VERSION ""

NS_ :

BS_:

BU_: PPIM HCP VDCM APM2 SGW IDCM EVCU2 BPCM

BO_ 1852 HVBATTERY_RM_CELLS8: 64 BPCM
 SG_ HVBatCellVoltage_Cell192 : 36|13@0+ (0.001,0) [0|5] "V"  SGW
 SG_ HVBatCellVoltage_Cell191 : 20|13@0+ (0.001,0) [0|5] "V"  SGW
 SG_ HVBatCellVoltage_Cell190 : 4|13@0+ (0.001,0) [0|5] "V"  SGW
 SG_ HVBatCellVoltage_Cell216 : 420|13@0+ (0.001,0) [0|5] "V"  SGW
 SG_ HVBatCellVoltage_Cell215 : 404|13@0+ (0.001,0) [0|5] "V"  Vector__XXX
 SG_ HVBatCellVoltage_Cell214 : 388|13@0+ (0.001,0) [0|5] "V"  Vector__XXX
 SG_ HVBatCellVoltage_Cell213 : 372|13@0+ (0.001,0) [0|5] "V"  Vector__XXX
 SG_ HVBatCellVoltage_Cell212 : 356|13@0+ (0.001,0) [0|5] "V"  Vector__XXX
 SG_ HVBatCellVoltage_Cell211 : 340|13@0+ (0.001,0) [0|5] "V"  Vector__XXX
 SG_ HVBatCellVoltage_Cell210 : 324|13@0+ (0.001,0) [0|5] "V"  Vector__XXX
 SG_ HVBatCellVoltage_Cell209 : 308|13@0+ (0.001,0) [0|5] "V"  Vector__XXX
 SG_ HVBatCellVoltage_Cell208 : 292|13@0+ (0.001,0) [0|5] "V"  Vector__XXX
 SG_ HVBatCellVoltage_Cell207 : 276|13@0+ (0.001,0) [0|5] "V"  Vector__XXX
 SG_ HVBatCellVoltage_Cell206 : 260|13@0+ (0.001,0) [0|5] "V"  Vector__XXX
 SG_ HVBatCellVoltage_Cell205 : 244|13@0+ (0.001,0) [0|5] "V"  Vector__XXX
 SG_ HVBatCellVoltage_Cell204 : 228|13@0+ (0.001,0) [0|5] "V"  Vector__XXX
 SG_ HVBatCellVoltage_Cell203 : 212|13@0+ (0.001,0) [0|5] "V"  Vector__XXX
 SG_ HVBatCellVoltage_Cell202 : 196|13@0+ (0.001,0) [0|5] "V"  Vector__XXX
 SG_ HVBatCellVoltage_Cell201 : 180|13@0+ (0.001,0) [0|5] "V"  Vector__XXX
 SG_ HVBatCellVoltage_Cell200 : 164|13@0+ (0.001,0) [0|5] "V"  Vector__XXX
 SG_ HVBatCellVoltage_Cell198 : 132|13@0+ (0.001,0) [0|5] "V"  Vector__XXX
 SG_ HVBatCellVoltage_Cell197 : 116|13@0+ (0.001,0) [0|5] "V"  Vector__XXX
 SG_ HVBatCellVoltage_Cell196 : 100|13@0+ (0.001,0) [0|5] "V"  Vector__XXX
 SG_ HVBatCellVoltage_Cell195 : 84|13@0+ (0.001,0) [0|5] "V"  Vector__XXX
 SG_ HVBatCellVoltage_Cell194 : 68|13@0+ (0.001,0) [0|5] "V"  Vector__XXX
 SG_ HVBatCellVoltage_Cell193 : 52|13@0+ (0.001,0) [0|5] "V"  Vector__XXX

BO_ 1851 HVBATTERY_RM_CELLS7: 64 BPCM
 SG_ HVBatCellVoltage_Cell189 : 420|13@0+ (0.001,0) [0|5] "V"  SGW
 SG_ HVBatCellVoltage_Cell188 : 404|13@0+ (0.001,0) [0|5] "V"  SGW
 SG_ HVBatCellVoltage_Cell187 : 388|13@0+ (0.001,0) [0|5] "V"  SGW
 SG_ HVBatCellVoltage_Cell186 : 372|13@0+ (0.001,0) [0|5] "V"  SGW
 SG_ HVBatCellVoltage_Cell185 : 356|13@0+ (0.001,0) [0|5] "V"  SGW
 SG_ HVBatCellVoltage_Cell184 : 340|13@0+ (0.001,0) [0|5] "V"  SGW
 SG_ HVBatCellVoltage_Cell183 : 324|13@0+ (0.001,0) [0|5] "V"  SGW
 SG_ HVBatCellVoltage_Cell182 : 308|13@0+ (0.001,0) [0|5] "V"  SGW
 SG_ HVBatCellVoltage_Cell181 : 292|13@0+ (0.001,0) [0|5] "V"  SGW
 SG_ HVBatCellVoltage_Cell180 : 276|13@0+ (0.001,0) [0|5] "V"  SGW
 SG_ HVBatCellVoltage_Cell179 : 260|13@0+ (0.001,0) [0|5] "V"  SGW
 SG_ HVBatCellVoltage_Cell178 : 244|13@0+ (0.001,0) [0|5] "V"  SGW
 SG_ HVBatCellVoltage_Cell177 : 228|13@0+ (0.001,0) [0|5] "V"  SGW
 SG_ HVBatCellVoltage_Cell176 : 212|13@0+ (0.001,0) [0|5] "V"  SGW
 SG_ HVBatCellVoltage_Cell175 : 196|13@0+ (0.001,0) [0|5] "V"  SGW
 SG_ HVBatCellVoltage_Cell174 : 180|13@0+ (0.001,0) [0|5] "V"  SGW
 SG_ HVBatCellVoltage_Cell173 : 164|13@0+ (0.001,0) [0|5] "V"  SGW
 SG_ HVBatCellVoltage_Cell172 : 148|13@0+ (0.001,0) [0|5] "V"  SGW
 SG_ HVBatCellVoltage_Cell171 : 132|13@0+ (0.001,0) [0|5] "V"  SGW
 SG_ HVBatCellVoltage_Cell170 : 116|13@0+ (0.001,0) [0|5] "V"  SGW
 SG_ HVBatCellVoltage_Cell169 : 100|13@0+ (0.001,0) [0|5] "V"  SGW
 SG_ HVBatCellVoltage_Cell168 : 84|13@0+ (0.001,0) [0|5] "V"  SGW
 SG_ HVBatCellVoltage_Cell167 : 68|13@0+ (0.001,0) [0|5] "V"  SGW
 SG_ HVBatCellVoltage_Cell166 : 52|13@0+ (0.001,0) [0|5] "V"  SGW
 SG_ HVBatCellVoltage_Cell165 : 36|13@0+ (0.001,0) [0|5] "V"  SGW
 SG_ HVBatCellVoltage_Cell164 : 20|13@0+ (0.001,0) [0|5] "V"  SGW
 SG_ HVBatCellVoltage_Cell163 : 4|13@0+ (0.001,0) [0|5] "V"  SGW

BO_ 1850 HVBATTERY_RM_CELLS6: 64 BPCM
 SG_ HVBatCellVoltage_Cell162 : 420|13@0+ (0.001,0) [0|5] "V"  SGW
 SG_ HVBatCellVoltage_Cell161 : 404|13@0+ (0.001,0) [0|5] "V"  SGW
 SG_ HVBatCellVoltage_Cell160 : 388|13@0+ (0.001,0) [0|5] "V"  SGW
 SG_ HVBatCellVoltage_Cell159 : 372|13@0+ (0.001,0) [0|5] "V"  SGW
 SG_ HVBatCellVoltage_Cell158 : 356|13@0+ (0.001,0) [0|5] "V"  SGW
 SG_ HVBatCellVoltage_Cell157 : 340|13@0+ (0.001,0) [0|5] "V"  SGW
 SG_ HVBatCellVoltage_Cell156 : 324|13@0+ (0.001,0) [0|5] "V"  SGW
 SG_ HVBatCellVoltage_Cell155 : 308|13@0+ (0.001,0) [0|5] "V"  SGW
 SG_ HVBatCellVoltage_Cell154 : 292|13@0+ (0.001,0) [0|5] "V"  SGW
 SG_ HVBatCellVoltage_Cell153 : 276|13@0+ (0.001,0) [0|5] "V"  SGW
 SG_ HVBatCellVoltage_Cell152 : 260|13@0+ (0.001,0) [0|5] "V"  SGW
 SG_ HVBatCellVoltage_Cell151 : 244|13@0+ (0.001,0) [0|5] "V"  SGW
 SG_ HVBatCellVoltage_Cell150 : 228|13@0+ (0.001,0) [0|5] "V"  SGW
 SG_ HVBatCellVoltage_Cell149 : 212|13@0+ (0.001,0) [0|5] "V"  SGW
 SG_ HVBatCellVoltage_Cell148 : 196|13@0+ (0.001,0) [0|5] "V"  SGW
 SG_ HVBatCellVoltage_Cell147 : 180|13@0+ (0.001,0) [0|5] "V"  SGW
 SG_ HVBatCellVoltage_Cell146 : 164|13@0+ (0.001,0) [0|5] "V"  SGW
 SG_ HVBatCellVoltage_Cell145 : 148|13@0+ (0.001,0) [0|5] "V"  SGW
 SG_ HVBatCellVoltage_Cell144 : 132|13@0+ (0.001,0) [0|5] "V"  SGW
 SG_ HVBatCellVoltage_Cell143 : 116|13@0+ (0.001,0) [0|5] "V"  SGW
 SG_ HVBatCellVoltage_Cell142 : 100|13@0+ (0.001,0) [0|5] "V"  SGW
 SG_ HVBatCellVoltage_Cell141 : 84|13@0+ (0.001,0) [0|5] "V"  SGW
 SG_ HVBatCellVoltage_Cell140 : 68|13@0+ (0.001,0) [0|5] "V"  SGW
 SG_ HVBatCellVoltage_Cell139 : 52|13@0+ (0.001,0) [0|5] "V"  SGW
 SG_ HVBatCellVoltage_Cell138 : 36|13@0+ (0.001,0) [0|5] "V"  SGW
 SG_ HVBatCellVoltage_Cell137 : 20|13@0+ (0.001,0) [0|5] "V"  SGW
 SG_ HVBatCellVoltage_Cell136 : 4|13@0+ (0.001,0) [0|5] "V"  SGW

BO_ 1849 HVBATTERY_RM_CELLS5: 64 BPCM
 SG_ HVBatCellVoltage_Cell135 : 420|13@0+ (0.001,0) [0|5] "V"  SGW
 SG_ HVBatCellVoltage_Cell134 : 404|13@0+ (0.001,0) [0|5] "V"  SGW
 SG_ HVBatCellVoltage_Cell133 : 388|13@0+ (0.001,0) [0|5] "V"  SGW
 SG_ HVBatCellVoltage_Cell132 : 372|13@0+ (0.001,0) [0|5] "V"  SGW
 SG_ HVBatCellVoltage_Cell131 : 356|13@0+ (0.001,0) [0|5] "V"  SGW
 SG_ HVBatCellVoltage_Cell130 : 340|13@0+ (0.001,0) [0|5] "V"  SGW
 SG_ HVBatCellVoltage_Cell129 : 324|13@0+ (0.001,0) [0|5] "V"  SGW
 SG_ HVBatCellVoltage_Cell128 : 308|13@0+ (0.001,0) [0|5] "V"  SGW
 SG_ HVBatCellVoltage_Cell127 : 292|13@0+ (0.001,0) [0|5] "V"  SGW
 SG_ HVBatCellVoltage_Cell126 : 276|13@0+ (0.001,0) [0|5] "V"  SGW
 SG_ HVBatCellVoltage_Cell125 : 260|13@0+ (0.001,0) [0|5] "V"  SGW
 SG_ HVBatCellVoltage_Cell124 : 244|13@0+ (0.001,0) [0|5] "V"  SGW
 SG_ HVBatCellVoltage_Cell123 : 228|13@0+ (0.001,0) [0|5] "V"  SGW
 SG_ HVBatCellVoltage_Cell122 : 212|13@0+ (0.001,0) [0|5] "V"  SGW
 SG_ HVBatCellVoltage_Cell121 : 196|13@0+ (0.001,0) [0|5] "V"  SGW
 SG_ HVBatCellVoltage_Cell120 : 180|13@0+ (0.001,0) [0|5] "V"  SGW
 SG_ HVBatCellVoltage_Cell119 : 164|13@0+ (0.001,0) [0|5] "V"  SGW
 SG_ HVBatCellVoltage_Cell118 : 148|13@0+ (0.001,0) [0|5] "V"  SGW
 SG_ HVBatCellVoltage_Cell117 : 132|13@0+ (0.001,0) [0|5] "V"  SGW
 SG_ HVBatCellVoltage_Cell116 : 116|13@0+ (0.001,0) [0|5] "V"  SGW
 SG_ HVBatCellVoltage_Cell115 : 100|13@0+ (0.001,0) [0|5] "V"  SGW
 SG_ HVBatCellVoltage_Cell114 : 84|13@0+ (0.001,0) [0|5] "V"  SGW
 SG_ HVBatCellVoltage_Cell113 : 68|13@0+ (0.001,0) [0|5] "V"  SGW
 SG_ HVBatCellVoltage_Cell112 : 52|13@0+ (0.001,0) [0|5] "V"  SGW
 SG_ HVBatCellVoltage_Cell111 : 36|13@0+ (0.001,0) [0|5] "V"  SGW
 SG_ HVBatCellVoltage_Cell110 : 20|13@0+ (0.001,0) [0|5] "V"  SGW
 SG_ HVBatCellVoltage_Cell109 : 4|13@0+ (0.001,0) [0|5] "V"  SGW

BO_ 2564485412 DIAGNOSTIC_RESPONSE_VDCM: 8 VDCM
 SG_ N_PDU_18DAF124 : 7|64@0+ (1,0) [0|0] "" SGW

BO_ 2564433137 DIAGNOSTIC_REQUEST_VDCM: 8 SGW
 SG_ N_PDU_18DA24F1 : 7|64@0+ (1,0) [0|0] "" VDCM

BO_ 502 VDCM_OBCM: 48 EVCU2
 SG_ VDCM_OBCDischCurrentLim : 265|14@0+ (0.1,-815) [-815|823.3] "A"  IDCM
 SG_ VDCM_BattBulkSOC : 283|10@0+ (0.1,0) [0|100] "%"  IDCM
 SG_ HVCMS_ServiceScope : 87|16@0+ (1,0) [0|65534] "" IDCM
 SG_ HVCMS_ReadyToChargeState : 271|1@0+ (1,0) [0|1] "" IDCM
 SG_ HVCMS_Protocol_Entry3 : 39|16@0+ (1,0) [0|65534] "" IDCM
 SG_ HVCMS_Protocol_Entry2 : 23|16@0+ (1,0) [0|65534] "" IDCM
 SG_ HVCMS_Protocol_Entry1 : 7|16@0+ (1,0) [0|65534] "" IDCM
 SG_ HVCMS_EVTargetVoltage : 247|14@0+ (0.1,0) [0|1638.2] "V"  IDCM
 SG_ HVCMS_EVTargetCurrent : 249|10@0+ (1,-500) [-500|522] "" IDCM
 SG_ HVCMS_EVRESSConditioning : 171|1@0+ (1,0) [0|1] "" IDCM
 SG_ HVCMS_EVRESS_SOC : 159|12@0+ (0.02442,0) [0|99.97548] "%"  IDCM
 SG_ HVCMS_EVReady : 170|1@0+ (1,0) [0|1] "" IDCM
 SG_ HVCMS_EVMax_V_Limit : 215|14@0+ (0.1,0) [0|1638.2] "V"  IDCM
 SG_ HVCMS_EVMax_P_Limit : 191|24@0+ (0.1,0) [0|1677721.4] "W"  IDCM
 SG_ HVCMS_EVMax_I_Limit : 169|10@0+ (1,-500) [-500|522] "A"  IDCM
 SG_ HVCMS_EVEnergyCapacity : 217|17@0+ (1,0) [0|131070] "Wh"  IDCM
 SG_ HVCMS_ChargingComplete : 269|1@0+ (1,0) [0|1] "" IDCM
 SG_ HVCMS_BulkChargingComplete : 270|1@0+ (1,0) [0|1] "" IDCM
 SG_ VDCM_TypeCNegotiationSts : 378|3@0+ (1,0) [0|7] "" IDCM
 SG_ VDCM_GenChallenge : 362|16@0+ (1,0) [0|65535] "" IDCM
 SG_ VDCM_ContractAuthenticationID : 346|16@0+ (1,0) [0|65535] "" IDCM
 SG_ HVCMS_EVEnergyRequest : 331|17@0+ (1,0) [0|131071] "Wh"  IDCM
 SG_ OBCM_OutVoltageSyncTgt : 289|10@0+ (1,0) [0|1022] "V"  IDCM
 SG_ HVCMS_ServiceCategory : 103|4@0+ (1,0) [0|15] "" IDCM
 SG_ HVCMS_SelectedServiceId : 135|16@0+ (1,0) [0|65535] "" IDCM
 SG_ HVCMS_SelectedPaymentOptn : 119|2@0+ (1,0) [0|3] "" IDCM
 SG_ HVCMS_SelectedEnergyTransferType : 151|4@0+ (1,0) [0|15] "" IDCM
 SG_ HVCMS_RemaningTimeToFullSOC : 71|16@0+ (1,0) [0|65535] "sec"  IDCM
 SG_ HVCMS_RemaningTimeToBulkSOC : 55|16@0+ (1,0) [0|65534] "" IDCM
 SG_ HVCMS_EVErrorCode : 163|4@0+ (1,0) [0|15] "" IDCM
 SG_ V2X_HVCMS_SlctdEnergyTransfType : 99|1@0+ (1,0) [0|1] "-"  IDCM

BO_ 498 OBCM_VDCM: 48 IDCM
 SG_ HVCMS_EVSEPresentVoltage : 250|14@0+ (0.1,0) [0|1638.3] "V"  EVCU2
 SG_ HVCMS_EVSEPeakCurrentRipple : 199|10@0+ (1,-500) [-500|523] "A"  EVCU2
 SG_ HVCMS_EVSEMinCurrentLimit : 157|10@0+ (1,-500) [-500|523] "A"  EVCU2
 SG_ HVCMS_EVSEMaxPowerLimit : 205|24@0+ (0.1,0) [0|1677721.5] "W"  EVCU2
 SG_ HVCMS_EVSEMaxCurrentLimit : 151|10@0+ (1,-500) [-500|523] "A"  EVCU2
 SG_ HVCMS_EVSECurrRegulationTol : 244|10@0+ (1,-500) [-500|523] "A"  EVCU2
 SG_ HVCMS_EnergyToBeDelivered : 229|17@0+ (1,0) [0|131071] "Wh"  EVCU2
 SG_ EVSE_IsolationSts : 143|3@0+ (1,0) [0|7] "" EVCU2
 SG_ EVSE_Accepted_Protocol : 39|16@0+ (1,0) [0|65535] "" EVCU2
 SG_ DC_TimeOut : 139|1@0+ (1,0) [0|1] "" EVCU2
 SG_ DC_Isolation_Disable_Cmd : 140|1@0+ (1,0) [0|1] "" EVCU2
 SG_ OBCM_PLCTypeSts : 337|3@0+ (1,0) [0|6] "" EVCU2
 SG_ HVCMS_EVSEVoltageLimitAchieved : 286|2@0+ (1,0) [0|3] "" EVCU2
 SG_ HVCMS_EVSEPowerLimitAchieved : 272|2@0+ (1,0) [0|3] "" EVCU2
 SG_ HVCMS_EVSEMinimumVoltageLimit : 300|16@0+ (0.1,0) [0|6553.4] "V"  EVCU2
 SG_ HVCMS_EVSEMaximumVoltageLimit : 284|16@0+ (0.1,0) [0|6553.4] "V"  EVCU2
 SG_ HVCMS_EVSECurrentLimitAchieved : 274|2@0+ (1,0) [0|3] "" EVCU2
 SG_ HVCMS_EVSEPresentCurrent : 350|16@0+ (0.02,0) [0|1310.7] "A"  EVCU2
 SG_ EVSE_OfferedEnergyTransferType : 103|4@0+ (1,0) [0|15] "" EVCU2
 SG_ HVCMS_TxMessageStat : 7|5@0+ (1,0) [0|31] "" EVCU2
 SG_ HVCMS_ResponseCode : 23|5@0+ (1,0) [0|31] "" EVCU2
 SG_ HVCMS_EVSEProcessing : 119|1@0+ (1,0) [0|1] "" EVCU2
 SG_ EVSE_FreeService : 71|1@0+ (1,0) [0|1] "" EVCU2
 SG_ TxMessageResponse : 70|5@0+ (1,0) [0|31] "" EVCU2
 SG_ HVCMS_EVSEStatusCode : 135|4@0+ (1,0) [0|15] "" EVCU2
 SG_ EVSE_ServiceId : 55|16@0+ (1,0) [0|65535] "" EVCU2
 SG_ EVSE_OfferedService : 138|3@0+ (1,0) [0|7] "" EVCU2
 SG_ EVSE_OfferedPaymentOptn : 87|2@0+ (1,0) [0|3] "" EVCU2
 SG_ V2H_HVCMS_EVSEPresentCurrent : 268|10@0+ (1,-500) [-500|523] "A"  EVCU2
 SG_ MC_OBCM_VDCM : 371|4@0+ (1,0) [0|15] "" EVCU2
 SG_ EVSE_Supported_ISO1 : 64|1@0+ (1,0) [0|1] "" EVCU2
 SG_ EVSE_Supported_DIN : 65|1@0+ (1,0) [0|1] "-"  EVCU2
 SG_ CRC_OBCM_VDCM : 383|8@0+ (1,0) [0|255] "" EVCU2
 SG_ EVSE_Supported_SAE : 31|1@0+ (1,0) [0|1] "" EVCU2
 SG_ EVSE_Service2_Certificate : 16|1@0+ (1,0) [0|1] "-"  EVCU2
 SG_ EVSE_OfferedPaymentEIM : 18|1@0+ (1,0) [0|1] "-"  EVCU2
 SG_ EVSE_OfferedPaymentContract : 17|1@0+ (1,0) [0|1] "-"  EVCU2
 SG_ EVSE_Notification : 2|2@0+ (1,0) [0|3] "" EVCU2
 SG_ OBCM_ThermalRunaway : 131|2@0+ (1,0) [0|3] "" EVCU2
 SG_ ReceiptRequired : 0|1@0+ (1,0) [0|1] "-"  EVCU2
 SG_ V2X_EVSE_Service_6_V2G : 29|1@0+ (1,0) [0|1] "-"  EVCU2
 SG_ V2X_EVSE_Service_5_V2H : 30|1@0+ (1,0) [0|1] "-"  EVCU2

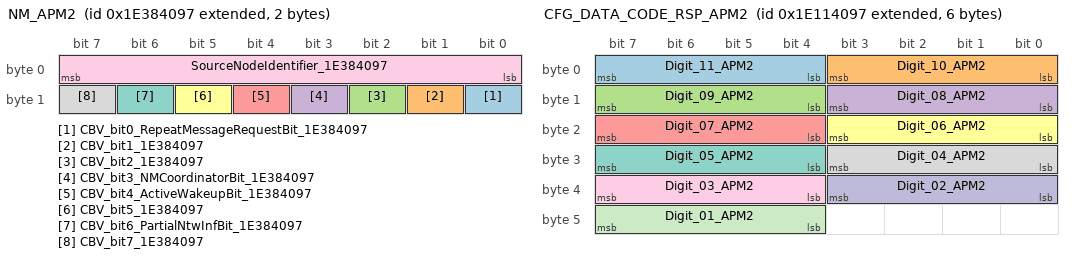
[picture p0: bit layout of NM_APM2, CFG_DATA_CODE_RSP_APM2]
BO_ 2654486679 NM_APM2: 2 APM2
 SG_ CBV_bit0_RepeatMessageRequestBit_1E384097 : 8|1@0+ (1,0) [0|1] "" EVCU2,IDCM,SGW,BPCM
 SG_ CBV_bit1_1E384097 : 9|1@0+ (1,0) [0|1] "" EVCU2,IDCM,SGW,BPCM
 SG_ CBV_bit2_1E384097 : 10|1@0+ (1,0) [0|1] "" EVCU2,IDCM,SGW,BPCM
 SG_ CBV_bit3_NMCoordinatorBit_1E384097 : 11|1@0+ (1,0) [0|1] "" EVCU2,IDCM,SGW,BPCM
 SG_ CBV_bit4_ActiveWakeupBit_1E384097 : 12|1@0+ (1,0) [0|1] "" EVCU2,IDCM,SGW,BPCM
 SG_ CBV_bit5_1E384097 : 13|1@0+ (1,0) [0|1] "" EVCU2,IDCM,SGW,BPCM
 SG_ CBV_bit6_PartialNtwInfBit_1E384097 : 14|1@0+ (1,0) [0|1] "" EVCU2,IDCM,SGW,BPCM
 SG_ CBV_bit7_1E384097 : 15|1@0+ (1,0) [0|1] "" EVCU2,IDCM,SGW,BPCM
 SG_ SourceNodeIdentifier_1E384097 : 7|8@0+ (1,0) [0|255] "-"  EVCU2,IDCM,SGW,BPCM

BO_ 2564682261 DIAGNOSTIC_ROE_FD_MCPB: 64 EVCU2
 SG_ N_PDU_18DDF215 : 7|64@0+ (1,0) [0|0] "" SGW

BO_ 2564682260 DIAGNOSTIC_ROE_FD_MCPA: 64 EVCU2
 SG_ N_PDU_18DDF214 : 7|64@0+ (1,0) [0|0] "" SGW

BO_ 2564682335 DIAGNOSTIC_ROE_FD_APM2: 64 APM2
 SG_ N_PDU_18DDF25F : 7|64@0+ (1,0) [0|0] "" SGW

BO_ 2564682079 DIAGNOSTIC_ROE_APM2: 8 APM2
 SG_ N_PDU_18DDF15F : 7|64@0+ (1,0) [0|0] "" SGW

BO_ 2564485396 DIAGNOSTIC_RESPONSE_MCPA: 8 EVCU2
 SG_ N_PDU_18DAF114 : 7|64@0+ (1,0) [0|0] "" SGW

BO_ 2564485653 DIAGNOSTIC_RESPONSE_FD_MCPB: 64 EVCU2
 SG_ N_PDU_18DAF215 : 7|64@0+ (1,0) [0|0] "" SGW

BO_ 2564485652 DIAGNOSTIC_RESPONSE_FD_MCPA: 64 EVCU2
 SG_ N_PDU_18DAF214 : 7|64@0+ (1,0) [0|0] "" SGW

BO_ 2564485727 DIAGNOSTIC_RESPONSE_FD_APM2: 64 APM2
 SG_ N_PDU_18DAF25F : 7|64@0+ (1,0) [0|0] "" SGW

BO_ 2564485471 DIAGNOSTIC_RESPONSE_APM2: 8 APM2
 SG_ N_PDU_18DAF15F : 7|64@0+ (1,0) [0|0] "" SGW

BO_ 2564429297 DIAGNOSTIC_REQUEST_MCPB: 8 SGW
 SG_ N_PDU_18DA15F1 : 7|64@0+ (1,0) [0|0] "" EVCU2

BO_ 2564429041 DIAGNOSTIC_REQUEST_MCPA: 8 SGW
 SG_ N_PDU_18DA14F1 : 7|64@0+ (1,0) [0|0] "" EVCU2

BO_ 2564429298 DIAGNOSTIC_REQUEST_FD_MCPB: 64 SGW
 SG_ N_PDU_18DA15F2 : 7|64@0+ (1,0) [0|0] "" EVCU2

BO_ 2564429042 DIAGNOSTIC_REQUEST_FD_MCPA: 64 SGW
 SG_ N_PDU_18DA14F2 : 7|64@0+ (1,0) [0|0] "" EVCU2

BO_ 2564448242 DIAGNOSTIC_REQUEST_FD_APM2: 64 SGW
 SG_ N_PDU_18DA5FF2 : 7|64@0+ (1,0) [0|0] "" APM2

BO_ 2564448241 DIAGNOSTIC_REQUEST_APM2: 8 SGW
 SG_ N_PDU_18DA5FF1 : 7|64@0+ (1,0) [0|0] "" APM2

BO_ 2651930775 CFG_DATA_CODE_RSP_APM2: 6 APM2
 SG_ Digit_11_APM2 : 7|4@0+ (1,0) [0|15] "-"  EVCU2
 SG_ Digit_10_APM2 : 3|4@0+ (1,0) [0|15] "-"  EVCU2
 SG_ Digit_09_APM2 : 15|4@0+ (1,0) [0|15] "-"  EVCU2
 SG_ Digit_08_APM2 : 11|4@0+ (1,0) [0|15] "-"  EVCU2
 SG_ Digit_07_APM2 : 23|4@0+ (1,0) [0|15] "-"  EVCU2
 SG_ Digit_06_APM2 : 19|4@0+ (1,0) [0|15] "-"  EVCU2
 SG_ Digit_05_APM2 : 31|4@0+ (1,0) [0|15] "-"  EVCU2
 SG_ Digit_04_APM2 : 27|4@0+ (1,0) [0|15] "-"  EVCU2
 SG_ Digit_03_APM2 : 39|4@0+ (1,0) [0|15] "-"  EVCU2
 SG_ Digit_02_APM2 : 35|4@0+ (1,0) [0|15] "-"  EVCU2
 SG_ Digit_01_APM2 : 47|4@0+ (1,0) [0|15] "-"  EVCU2

BO_ 244 BATTERY_HV: 64 BPCM
 SG_ BMS_HV_Trac_PreCha_Contac_Sts : 305|3@0+ (1,0) [0|7] "" SGW
 SG_ BMS_HV_Trac_Main_Contac_Sts : 318|3@0+ (1,0) [0|7] "" SGW
 SG_ BMS_HV_SOH_Low : 31|7@0+ (1,0) [0|127] "" SGW
 SG_ BMS_HV_SOH : 22|7@0+ (1,0) [0|127] "" SGW
 SG_ BMS_HV_SOC : 55|10@0+ (0.1,0) [0|102.2] "%"  SGW
 SG_ BMS_HV_InternalVoltage : 278|13@0+ (0.1,90.9) [90.9|910] "V"  SGW
 SG_ BMS_HV_Current : 213|15@0+ (0.1,-1638.4) [-1638.4|1638.2] "A"  SGW
 SG_ BMS_HV_Char_PreCha_Contac_Sts : 312|3@0+ (1,0) [0|7] "" SGW
 SG_ BMS_HV_Char_Main_Contac_Sts : 315|3@0+ (1,0) [0|7] "" SGW
 SG_ BMS_HV_Capacity_Vldty : 79|1@0+ (1,0) [0|1] "" SGW
 SG_ BMS_HV_Battery_GFD_Sts : 251|3@0+ (1,0) [0|7] "" SGW
 SG_ BPCM_Comm_Fail_CAN : 162|4@0+ (1,0) [0|14] "" SGW
 SG_ BMS_HV_Trac_Bus_Sts : 61|3@0+ (1,0) [0|6] "" SGW
 SG_ BMS_HV_Temperature_Min : 157|11@0+ (0.1,-40) [-40|164.7] "°C"  SGW
 SG_ BMS_HV_Temperature_Max : 136|11@0+ (0.1,-40) [-40|164.7] "°C"  SGW
 SG_ BMS_HV_Temperature_Avg : 131|11@0+ (0.1,-40) [-40|164.7] "°C"  SGW
 SG_ BMS_HV_SOH_Vldty : 230|1@0+ (1,0) [0|1] "" SGW
 SG_ BMS_HV_AC_Char_Main_Contac_Sts : 200|3@0+ (1,0) [0|7] "" SGW
 SG_ ImpactHardwireV : 500|1@0+ (1,0) [0|1] "" EVCU2
 SG_ ImpactHardwire : 501|1@0+ (1,0) [0|1] "" EVCU2
 SG_ BMS_HV_Capacity : 58|11@0+ (0.15,0) [0|307.05] "Ah"  SGW

BO_ 252 BATT_PACK_LIM: 48 BPCM
 SG_ BMS_HV_Current_MaxDischrg_MdTrm : 93|14@0+ (0.1,0) [0|1638.2] "A"  SGW
 SG_ BMS_HV_Current_MaxDischrg_LgTrm : 149|14@0+ (0.1,0) [0|1638.2] "A"  SGW
 SG_ BMS_HV_Current_Discharge_ShrTrm : 37|14@0+ (0.1,0) [0|1638.2] "A"  SGW
 SG_ BMS_CntctrsShtTrmOpeningWarn : 321|1@0+ (1,0) [0|1] "" SGW
 SG_ BMS_CntctrsMidTrmOpeningWarn : 322|1@0+ (1,0) [0|1] "" SGW

BO_ 500 BATT_PACK_DEV: 32 BPCM
 SG_ BMS_HV_NumCellMinVolt : 61|8@0+ (1,0) [0|255] "" SGW
 SG_ BMS_HV_NumCellMinTemp : 174|9@0+ (1,0) [0|510] "" SGW
 SG_ BMS_HV_NumCellMaxVolt : 53|8@0+ (1,0) [0|255] "" SGW
 SG_ BMS_HV_NumCellMaxTemp : 167|9@0+ (1,0) [0|510] "" SGW
 SG_ BMS_Cell_Volt_Min_Vldty : 96|1@0+ (1,0) [0|1] "" SGW
 SG_ BMS_Cell_Volt_Min : 93|13@0+ (0.001,0) [0|8.19] "V"  SGW
 SG_ BMS_Cell_Volt_Max_Vldty : 94|1@0+ (1,0) [0|1] "" SGW
 SG_ BMS_Cell_Volt_Max : 75|13@0+ (0.001,0) [0|8.19] "V"  SGW

BO_ 250 APM_VDCM: 32 IDCM
 SG_ APM_Water_Temp : 95|8@0+ (1,-40) [-40|214] "°C"  EVCU2
 SG_ APM_RecoveryAction : 101|8@0+ (1,0) [0|255] "" EVCU2
 SG_ APM_PSFB_Temp2 : 75|12@0+ (0.1,-40) [-40|369.4] "°C"  EVCU2
 SG_ APM_PSFB_Temp1 : 71|12@0+ (0.1,-40) [-40|369.4] "°C"  EVCU2
 SG_ APM_LV_V_Fbk : 47|12@0+ (0.009143,0) [0|37.431442] "V"  EVCU2
 SG_ APM_LV_I_Fbk : 23|12@0+ (0.076917,0) [0|314.898198] "A"  EVCU2
 SG_ APM_HV_V_Fbk : 51|12@0+ (0.445636,0) [0|1824.433784] "V"  EVCU2
 SG_ APM_HV_I_Fbk : 27|12@0+ (0.002718,0) [0|11.127492] "A"  EVCU2
 SG_ APM_Buck_Temp : 3|12@0+ (0.1,-40) [-40|369.4] "°C"  EVCU2
 SG_ APM_UtilPctOfDCDC : 154|7@0+ (1,0) [0|127] "%"  EVCU2
 SG_ APM_TempColdPlate : 146|8@0+ (1,-40) [-40|215] "degC"  EVCU2
 SG_ APM_PowerLimitMode : 112|1@0+ (1,0) [0|1] "" EVCU2
 SG_ APM_OutputPower : 179|10@0+ (3,0) [0|3069] "W"  EVCU2
 SG_ APM_InputPower : 173|10@0+ (3,0) [0|3069] "W"  EVCU2
 SG_ APM_IdcHvSetPFdbk : 140|10@0+ (0.2,-100) [-100|104.6] "Amp"  EVCU2
 SG_ APM_HvVsetPFdbk : 185|9@0+ (1,0) [0|511] "V"  EVCU2
 SG_ APM_HvOverVStatus : 114|1@0+ (1,0) [0|1] "" EVCU2
 SG_ APM_FailureType : 103|2@0+ (1,0) [0|3] "" EVCU2
 SG_ APM_FailureReason : 122|6@0+ (1,0) [0|63] "" EVCU2
 SG_ APM_EstPwrLoss : 132|8@0+ (2,0) [0|510] "W"  EVCU2
 SG_ APM_DeratingReason : 127|5@0+ (1,0) [0|31] "" EVCU2
 SG_ APM_DeratingModeStatus : 109|3@0+ (1,0) [0|7] "" EVCU2
 SG_ APM_CurrentLimitMode : 113|1@0+ (1,0) [0|1] "" EVCU2
 SG_ APM_CtrlSts_Fbk : 7|4@0+ (1,0) [0|15] "" EVCU2
 SG_ MessageCounter_APM_VDCM : 243|4@0+ (1,0) [0|15] "-"  EVCU2
 SG_ CRC_APM_VDCM : 255|8@0+ (1,0) [0|255] "-"  EVCU2
 SG_ APM_DeratingPower : 163|6@0+ (50,0) [0|3100] "W"  EVCU2
 SG_ APM_ThermalRunaway : 118|2@0+ (1,0) [0|3] "" EVCU2

BO_ 2564485397 DIAGNOSTIC_RESPONSE_MCPB: 8 EVCU2
 SG_ N_PDU_18DAF115 : 7|64@0+ (1,0) [0|0] "" SGW

CM_ SG_ 1852 HVBatCellVoltage_Cell192 "High voltage battery cell voltage for Cell 192";
CM_ SG_ 1852 HVBatCellVoltage_Cell191 "High voltage battery cell voltage for Cell 191";
CM_ SG_ 1852 HVBatCellVoltage_Cell190 "High voltage battery cell voltage for Cell 190";
CM_ SG_ 1851 HVBatCellVoltage_Cell189 "High voltage battery cell voltage for Cell 189";
CM_ SG_ 1851 HVBatCellVoltage_Cell188 "High voltage battery cell voltage for Cell 188";
CM_ SG_ 1851 HVBatCellVoltage_Cell187 "High voltage battery cell voltage for Cell 187";
CM_ SG_ 1851 HVBatCellVoltage_Cell186 "High voltage battery cell voltage for Cell 186";
CM_ SG_ 1851 HVBatCellVoltage_Cell185 "High voltage battery cell voltage for Cell 185";
CM_ SG_ 1851 HVBatCellVoltage_Cell184 "High voltage battery cell voltage for Cell 184";
CM_ SG_ 1851 HVBatCellVoltage_Cell183 "High voltage battery cell voltage for Cell 183";
CM_ SG_ 1851 HVBatCellVoltage_Cell182 "High voltage battery cell voltage for Cell 182";
CM_ SG_ 1851 HVBatCellVoltage_Cell181 "High voltage battery cell voltage for Cell 181";
CM_ SG_ 1851 HVBatCellVoltage_Cell180 "High voltage battery cell voltage for Cell 180";
CM_ SG_ 1851 HVBatCellVoltage_Cell179 "High voltage battery cell voltage for Cell 179";
CM_ SG_ 1851 HVBatCellVoltage_Cell178 "High voltage battery cell voltage for Cell 178";
CM_ SG_ 1851 HVBatCellVoltage_Cell177 "High voltage battery cell voltage for Cell 177";
CM_ SG_ 1851 HVBatCellVoltage_Cell176 "High voltage battery cell voltage for Cell 176";
CM_ SG_ 1851 HVBatCellVoltage_Cell175 "High voltage battery cell voltage for Cell 175";
CM_ SG_ 1851 HVBatCellVoltage_Cell174 "High voltage battery cell voltage for Cell 174";
CM_ SG_ 1851 HVBatCellVoltage_Cell173 "High voltage battery cell voltage for Cell 173";
CM_ SG_ 1851 HVBatCellVoltage_Cell172 "High voltage battery cell voltage for Cell 172";
CM_ SG_ 1851 HVBatCellVoltage_Cell171 "High voltage battery cell voltage for Cell 171";
CM_ SG_ 1851 HVBatCellVoltage_Cell170 "High voltage battery cell voltage for Cell 170";
CM_ SG_ 1851 HVBatCellVoltage_Cell169 "High voltage battery cell voltage for Cell 169";
CM_ SG_ 1851 HVBatCellVoltage_Cell168 "High voltage battery cell voltage for Cell 168";
CM_ SG_ 1851 HVBatCellVoltage_Cell167 "High voltage battery cell voltage for Cell 167";
CM_ SG_ 1851 HVBatCellVoltage_Cell166 "High voltage battery cell voltage for Cell 166";
CM_ SG_ 1851 HVBatCellVoltage_Cell165 "High voltage battery cell voltage for Cell 165";
CM_ SG_ 1851 HVBatCellVoltage_Cell164 "High voltage battery cell voltage for Cell 164";
CM_ SG_ 1851 HVBatCellVoltage_Cell163 "High voltage battery cell voltage for Cell 163";
CM_ SG_ 1850 HVBatCellVoltage_Cell162 "High voltage battery cell voltage for Cell 162";
CM_ SG_ 1850 HVBatCellVoltage_Cell161 "High voltage battery cell voltage for Cell 161";
CM_ SG_ 1850 HVBatCellVoltage_Cell160 "High voltage battery cell voltage for Cell 160";
CM_ SG_ 1850 HVBatCellVoltage_Cell159 "High voltage battery cell voltage for Cell 159";
CM_ SG_ 1850 HVBatCellVoltage_Cell158 "High voltage battery cell voltage for Cell 158";
CM_ SG_ 1850 HVBatCellVoltage_Cell157 "High voltage battery cell voltage for Cell 157";
CM_ SG_ 1850 HVBatCellVoltage_Cell156 "High voltage battery cell voltage for Cell 156";
CM_ SG_ 1850 HVBatCellVoltage_Cell155 "High voltage battery cell voltage for Cell 155";
CM_ SG_ 1850 HVBatCellVoltage_Cell154 "High voltage battery cell voltage for Cell 154";
CM_ SG_ 1850 HVBatCellVoltage_Cell153 "High voltage battery cell voltage for Cell 153";
CM_ SG_ 1850 HVBatCellVoltage_Cell152 "High voltage battery cell voltage for Cell 152";
CM_ SG_ 1850 HVBatCellVoltage_Cell151 "High voltage battery cell voltage for Cell 151";
CM_ SG_ 1850 HVBatCellVoltage_Cell150 "High voltage battery cell voltage for Cell 150";
CM_ SG_ 1850 HVBatCellVoltage_Cell149 "High voltage battery cell voltage for Cell 149";
CM_ SG_ 1850 HVBatCellVoltage_Cell148 "High voltage battery cell voltage for Cell 148";
CM_ SG_ 1850 HVBatCellVoltage_Cell147 "High voltage battery cell voltage for Cell 147";
CM_ SG_ 1850 HVBatCellVoltage_Cell146 "High voltage battery cell voltage for Cell 146";
CM_ SG_ 1850 HVBatCellVoltage_Cell145 "High voltage battery cell voltage for Cell 145";
CM_ SG_ 1850 HVBatCellVoltage_Cell144 "High voltage battery cell voltage for Cell 144";
CM_ SG_ 1850 HVBatCellVoltage_Cell143 "High voltage battery cell voltage for Cell 143";
CM_ SG_ 1850 HVBatCellVoltage_Cell142 "High voltage battery cell voltage for Cell 142";
CM_ SG_ 1850 HVBatCellVoltage_Cell141 "High voltage battery cell voltage for Cell 141";
CM_ SG_ 1850 HVBatCellVoltage_Cell140 "High voltage battery cell voltage for Cell 140";
CM_ SG_ 1850 HVBatCellVoltage_Cell139 "High voltage battery cell voltage for Cell 139";
CM_ SG_ 1850 HVBatCellVoltage_Cell138 "High voltage battery cell voltage for Cell 138";
CM_ SG_ 1850 HVBatCellVoltage_Cell137 "High voltage battery cell voltage for Cell 137";
CM_ SG_ 1850 HVBatCellVoltage_Cell136 "High voltage battery cell voltage for Cell 136";
CM_ SG_ 1849 HVBatCellVoltage_Cell135 "High voltage battery cell voltage for Cell 135";
CM_ SG_ 1849 HVBatCellVoltage_Cell134 "High voltage battery cell voltage for Cell 134";
CM_ SG_ 1849 HVBatCellVoltage_Cell133 "High voltage battery cell voltage for Cell 133";
CM_ SG_ 1849 HVBatCellVoltage_Cell132 "High voltage battery cell voltage for Cell 132";
CM_ SG_ 1849 HVBatCellVoltage_Cell131 "High voltage battery cell voltage for Cell 131";
CM_ SG_ 1849 HVBatCellVoltage_Cell130 "High voltage battery cell voltage for Cell 130";
CM_ SG_ 1849 HVBatCellVoltage_Cell129 "High voltage battery cell voltage for Cell 129";
CM_ SG_ 1849 HVBatCellVoltage_Cell128 "High voltage battery cell voltage for Cell 128";
CM_ SG_ 1849 HVBatCellVoltage_Cell127 "High voltage battery cell voltage for Cell 127";
CM_ SG_ 1849 HVBatCellVoltage_Cell126 "High voltage battery cell voltage for Cell 126";
CM_ SG_ 1849 HVBatCellVoltage_Cell125 "High voltage battery cell voltage for Cell 125";
CM_ SG_ 1849 HVBatCellVoltage_Cell124 "High voltage battery cell voltage for Cell 124";
CM_ SG_ 1849 HVBatCellVoltage_Cell123 "High voltage battery cell voltage for Cell 123";
CM_ SG_ 1849 HVBatCellVoltage_Cell122 "High voltage battery cell voltage for Cell 122";
CM_ SG_ 1849 HVBatCellVoltage_Cell121 "High voltage battery cell voltage for Cell 121";
CM_ SG_ 1849 HVBatCellVoltage_Cell120 "High voltage battery cell voltage for Cell 120";
CM_ SG_ 1849 HVBatCellVoltage_Cell119 "High voltage battery cell voltage for Cell 119";
CM_ SG_ 1849 HVBatCellVoltage_Cell118 "High voltage battery cell voltage for Cell 118";
CM_ SG_ 1849 HVBatCellVoltage_Cell117 "High voltage battery cell voltage for Cell 117";
CM_ SG_ 1849 HVBatCellVoltage_Cell116 "High voltage battery cell voltage for Cell 116";
CM_ SG_ 1849 HVBatCellVoltage_Cell115 "High voltage battery cell voltage for Cell 115";
CM_ SG_ 1849 HVBatCellVoltage_Cell114 "High voltage battery cell voltage for Cell 114";
CM_ SG_ 1849 HVBatCellVoltage_Cell113 "High voltage battery cell voltage for Cell 113";
CM_ SG_ 1849 HVBatCellVoltage_Cell112 "High voltage battery cell voltage for Cell 112";
CM_ SG_ 1849 HVBatCellVoltage_Cell111 "High voltage battery cell voltage for Cell 111";
CM_ SG_ 1849 HVBatCellVoltage_Cell110 "High voltage battery cell voltage for Cell 110";
CM_ SG_ 1849 HVBatCellVoltage_Cell109 "High voltage battery cell voltage for Cell 109";
CM_ SG_ 502 VDCM_OBCDischCurrentLim "This signal indicates the Limit of discharge current.";
CM_ SG_ 502 VDCM_BattBulkSOC "This signal indicates the SOC at which the battery is considered as full.";
CM_ SG_ 502 HVCMS_ServiceScope "This signal indicates the HVCMS Service Scope.";
CM_ SG_ 502 HVCMS_ReadyToChargeState "This signal indicates the HVCMS_ReadyToChargeState.";
CM_ SG_ 502 HVCMS_Protocol_Entry3 "HVCMS Protocol";
CM_ SG_ 502 HVCMS_Protocol_Entry2 "HVCMS Protocol";
CM_ SG_ 502 HVCMS_Protocol_Entry1 "HVCMS Protocol";
CM_ SG_ 502 HVCMS_EVTargetVoltage "This signal indicates the HVCMS EV Target Voltage.";
CM_ SG_ 502 HVCMS_EVTargetCurrent "This signal indicates the HVCMS_EVTargetCurrent.";
CM_ SG_ 502 HVCMS_EVRESSConditioning "This signal indicates the HVCMS EV RESS Conditioning.";
CM_ SG_ 502 HVCMS_EVRESS_SOC "This signal indicates the HVCMS EV RESS State Of Charge.";
CM_ SG_ 502 HVCMS_EVReady "This signal indicates the HVCMS EV Ready.";
CM_ SG_ 502 HVCMS_EVMax_V_Limit "This signal indicates the HVCMS EV Max Voltage Limit.";
CM_ SG_ 502 HVCMS_EVMax_P_Limit "This signal indicates the HVCMS EV Max Power Limit.";
CM_ SG_ 502 HVCMS_EVMax_I_Limit "This signal indicates the HVCMS EV Max Current Limit.";
CM_ SG_ 502 HVCMS_EVEnergyCapacity "This signal indicates the HVCMS EV Energy Capacity.";
CM_ SG_ 502 HVCMS_ChargingComplete "This signal indicates the HVCMS Charging Complete.";
CM_ SG_ 502 HVCMS_BulkChargingComplete "This signal indicates the HVCMS Bulk Charging Complete.";
CM_ SG_ 498 HVCMS_EVSEPeakCurrentRipple "Peak-to-peak magnitude of the current ripple of the EVSE.";
CM_ SG_ 498 HVCMS_EVSEMaxPowerLimit "Maximum power the EVSE can deliver.";
CM_ SG_ 498 HVCMS_EVSECurrRegulationTol "Absolute magnitude of the regulation tolerance of the EVSE.";
CM_ SG_ 498 HVCMS_EnergyToBeDelivered "Amount of energy to be delivered by the EVSE.";
CM_ SG_ 498 DC_TimeOut "DC Charging session time out";
CM_ SG_ 498 DC_Isolation_Disable_Cmd "Isolation Disabling command for DC charging";
CM_ SG_ 244 BMS_HV_Trac_PreCha_Contac_Sts "Traction pre-charge contactor Physical relay status";
CM_ SG_ 244 BMS_HV_Trac_Main_Contac_Sts "Traction main contactor physical relay status";
CM_ SG_ 244 BMS_HV_SOH_Low "State of Health calculated at low SOC";
CM_ SG_ 244 BMS_HV_SOH "Status of Healt";
CM_ SG_ 244 BMS_HV_SOC "State of Charge";
CM_ SG_ 244 BMS_HV_InternalVoltage "Battery internal voltage";
CM_ SG_ 244 BMS_HV_Current "Battery Current";
CM_ SG_ 244 BMS_HV_Char_PreCha_Contac_Sts "DC Pre-Charging contactor physical relay status";
CM_ SG_ 244 BMS_HV_Char_Main_Contac_Sts "DC Charging main contactor physical relay status";
CM_ SG_ 244 BMS_HV_Capacity_Vldty "Battery Capacity validity";
CM_ SG_ 244 BMS_HV_Battery_GFD_Sts "HV Battery ground fault detection(Isolation)";
CM_ SG_ 252 BMS_HV_Current_MaxDischrg_MdTrm "This signal indicates the Maximum discharge current available for the next mid term.";
CM_ SG_ 252 BMS_HV_Current_MaxDischrg_LgTrm "This signal indicates the Maximum discharge current available for the next long term.";
CM_ SG_ 252 BMS_HV_Current_Discharge_ShrTrm "This signal indicates the Maximum discharge current available for the next short term.";
CM_ SG_ 252 BMS_CntctrsShtTrmOpeningWarn "This signal indicates the Battery warning imminent emergency contactors opening.";
CM_ SG_ 252 BMS_CntctrsMidTrmOpeningWarn "This signal indicates the Battery warning mid term emergency contactors opening.";
CM_ SG_ 500 BMS_HV_NumCellMinVolt "This signal indicates the ID No. of cell with min. voltage";
CM_ SG_ 500 BMS_HV_NumCellMinTemp "This signal indicates the Numner of the battery cell with the lowest temperature.";
CM_ SG_ 500 BMS_HV_NumCellMaxVolt "This signal indicates the ID No. of cell with max. voltage";
CM_ SG_ 500 BMS_HV_NumCellMaxTemp "This signal indicates the Number of the battery cell with the highest temperature.";
CM_ SG_ 500 BMS_Cell_Volt_Min_Vldty "This signal indicates the Min cell voltage validity.";
CM_ SG_ 500 BMS_Cell_Volt_Min "This signal indicates the Min cell voltage.";
CM_ SG_ 500 BMS_Cell_Volt_Max_Vldty "This signal indicates the Max cell voltage validity.";
CM_ SG_ 500 BMS_Cell_Volt_Max "This signal indicates the Max cell voltage.";
CM_ SG_ 250 APM_Water_Temp "This signal indicates the Estimated water temperature  into the cooling channel.";
CM_ SG_ 250 APM_RecoveryAction "This signal indicates the APM recovery action according to fault error";
CM_ SG_ 250 APM_PSFB_Temp2 "This signal indicates the Measured temperature on the phase shift full bridge converter hot spot 2";
CM_ SG_ 250 APM_PSFB_Temp1 "This signal indicates the Measured temperature on the phase shift full bridge converter hot spot 1";
CM_ SG_ 250 APM_LV_V_Fbk "This signal indicates the LV voltage feedback.";
CM_ SG_ 250 APM_LV_I_Fbk "This signal indicates the LV bus current feedback.";
CM_ SG_ 250 APM_HV_V_Fbk "This signal indicates the HV voltage feedback.";
CM_ SG_ 250 APM_HV_I_Fbk "This signal indicates the HV bus current feedback.";
CM_ SG_ 250 APM_Buck_Temp "This signal indicates the Buck stage hot spot temperature.";
CM_ SG_ 502 VDCM_TypeCNegotiationSts "This signal indicates the Status of Negotiation in case of Type C EVSE";
CM_ SG_ 502 VDCM_GenChallenge "This signal indicates the Contract Authentication request gen challenge.";
CM_ SG_ 502 VDCM_ContractAuthenticationID "This signal indicates the Contract Authentication ID.";
CM_ SG_ 502 HVCMS_EVEnergyRequest "This signal indicates the HVCMS EV Energy Request.";
CM_ SG_ 498 OBCM_PLCTypeSts "Power Line communication";
CM_ SG_ 498 HVCMS_EVSEMinimumVoltageLimit "For communication with charging station type A,B,C";
CM_ SG_ 498 HVCMS_EVSEMaximumVoltageLimit "For communication with charging station type A,B,C";
CM_ SG_ 244 BPCM_Comm_Fail_CAN "Communication fault on CAN detected by BPCM.";
CM_ SG_ 502 OBCM_OutVoltageSyncTgt "This signal indicates the OBCM Precharge Voltage Level";
CM_ SG_ 244 BMS_HV_Temperature_Min "Battery Minimum Temperature";
CM_ SG_ 244 BMS_HV_Temperature_Max "Battery Maximum Temperature";
CM_ SG_ 244 BMS_HV_Temperature_Avg "Battery Average Temperature";
CM_ SG_ 244 BMS_HV_SOH_Vldty "HV SOH validity";
CM_ SG_ 244 BMS_HV_AC_Char_Main_Contac_Sts "AC Charging main contactor physical relay status";
CM_ SG_ 250 APM_UtilPctOfDCDC "Utilization of DCDC output power capability";
CM_ SG_ 250 APM_TempColdPlate "Cold Plate Temperature";
CM_ SG_ 250 APM_PowerLimitMode "Low voltage at HV side";
CM_ SG_ 250 APM_OutputPower "APM Output Power";
CM_ SG_ 250 APM_InputPower "APM Input Power";
CM_ SG_ 250 APM_IdcHvSetPFdbk "Feedback of set point high voltage current";
CM_ SG_ 250 APM_HvVsetPFdbk "APM HV  Voltage set point feedback";
CM_ SG_ 250 APM_HvOverVStatus "over voltage at HV";
CM_ SG_ 250 APM_FailureType "APM Failure type";
CM_ SG_ 250 APM_FailureReason "FailureReason";
CM_ SG_ 250 APM_EstPwrLoss "Estimated Power Loss";
CM_ SG_ 250 APM_DeratingReason "APM Derating";
CM_ SG_ 250 APM_DeratingModeStatus "APM Derating status during operation";
CM_ SG_ 250 APM_CurrentLimitMode "Derating becasuse of too high current at HV";
CM_ SG_ 250 APM_CtrlSts_Fbk "This signal indicates the DC-DC feedback mode.";
CM_ SG_ 2564485412 N_PDU_18DAF124 "This signal is used for diagnostic purposes";
CM_ SG_ 2564485396 N_PDU_18DAF114 "This signal is used for diagnostic purposes";
CM_ SG_ 2564433137 N_PDU_18DA24F1 "This signal is used for diagnostic purposes";
CM_ SG_ 2564429041 N_PDU_18DA14F1 "This signal is used for diagnostic purposes";
CM_ SG_ 2654486679 CBV_bit0_RepeatMessageRequestBit_1E384097 "Repeat Message Request Bit";
CM_ SG_ 2654486679 CBV_bit3_NMCoordinatorBit_1E384097 "NM Coordinator Sleep Bit";
CM_ SG_ 2654486679 CBV_bit4_ActiveWakeupBit_1E384097 "Active Wakeup Bit";
CM_ SG_ 2654486679 CBV_bit6_PartialNtwInfBit_1E384097 "Partial Network Information Bit (PNI)";
CM_ SG_ 2654486679 SourceNodeIdentifier_1E384097 "Source Node Identifier";
CM_ SG_ 2564682261 N_PDU_18DDF215 "This signal is used for diagnostic purposes";
CM_ SG_ 2564682260 N_PDU_18DDF214 "This signal is used for diagnostic purposes";
CM_ SG_ 2564682335 N_PDU_18DDF25F "This signal is used for diagnostic purposes";
CM_ SG_ 2564682079 N_PDU_18DDF15F "This signal is used for diagnostic purposes";
CM_ SG_ 2564485653 N_PDU_18DAF215 "This signal is used for diagnostic purposes";
CM_ SG_ 2564485652 N_PDU_18DAF214 "This signal is used for diagnostic purposes";
CM_ SG_ 2564485727 N_PDU_18DAF25F "This signal is used for diagnostic purposes";
CM_ SG_ 2564485471 N_PDU_18DAF15F "This signal is used for diagnostic purposes";
CM_ SG_ 2564429297 N_PDU_18DA15F1 "This signal is used for diagnostic purposes";
CM_ SG_ 2564429298 N_PDU_18DA15F2 "This signal is used for diagnostic purposes";
CM_ SG_ 2564429042 N_PDU_18DA14F2 "This signal is used for diagnostic purposes";
CM_ SG_ 2564448242 N_PDU_18DA5FF2 "This signal is used for diagnostic purposes";
CM_ SG_ 2564448241 N_PDU_18DA5FF1 "This signal is used for diagnostic purposes";
CM_ SG_ 498 HVCMS_TxMessageStat "Response code from the Charging Station";
CM_ SG_ 498 HVCMS_ResponseCode "Response code from the Charging Station";
CM_ SG_ 244 ImpactHardwireV "This signal is used to indicate a Valid serial line comunication";
CM_ SG_ 244 ImpactHardwire "This signal is used to indicate that a crash happened";
CM_ SG_ 250 MessageCounter_APM_VDCM "This signal is a counter used for safety checks strategies. This counter is incremented of 1 (one) unit at each frame transmission.";
CM_ SG_ 250 CRC_APM_VDCM "CRC according to SAE J1850 standard at each frame transmission.";
CM_ SG_ 502 HVCMS_ServiceCategory "This signal indicates the HVCMS Service Category.";
CM_ SG_ 502 HVCMS_SelectedServiceId "This signal indicates the HVCMS Selected Service Identifier.";
CM_ SG_ 502 HVCMS_SelectedPaymentOptn "This signal indicates the HVCMS Selected Payment Option.";
CM_ SG_ 502 HVCMS_SelectedEnergyTransferType "This signal indicates the HVCMS Selected Energy Transfer Type.";
CM_ SG_ 502 HVCMS_RemaningTimeToFullSOC "This signal indicates the HVCM Remaning Time To Full SOC.";
CM_ SG_ 502 HVCMS_RemaningTimeToBulkSOC "This signal indicates the HVCM Remaning Time To Bulk SOC.";
CM_ SG_ 502 HVCMS_EVErrorCode "This signal indicates the HVCMS EV Error Code.";
CM_ SG_ 498 TxMessageResponse "This signal indicates the HVCMS Service Category.";
CM_ SG_ 498 EVSE_ServiceId "EVSE Service ID";
CM_ SG_ 498 EVSE_OfferedPaymentOptn "List of payment options offered.";
CM_ SG_ 244 BMS_HV_Capacity "Battery Capacity";
CM_ SG_ 1852 HVBatCellVoltage_Cell216 "High voltage battery cell voltage for Cell 216";
CM_ SG_ 1852 HVBatCellVoltage_Cell215 "High voltage battery cell voltage for Cell 215";
CM_ SG_ 1852 HVBatCellVoltage_Cell214 "High voltage battery cell voltage for Cell 214";
CM_ SG_ 1852 HVBatCellVoltage_Cell213 "High voltage battery cell voltage for Cell 213";
CM_ SG_ 1852 HVBatCellVoltage_Cell212 "High voltage battery cell voltage for Cell 212";
CM_ SG_ 1852 HVBatCellVoltage_Cell211 "High voltage battery cell voltage for Cell 211";
CM_ SG_ 1852 HVBatCellVoltage_Cell210 "High voltage battery cell voltage for Cell 210";
CM_ SG_ 1852 HVBatCellVoltage_Cell209 "High voltage battery cell voltage for Cell 209";
CM_ SG_ 1852 HVBatCellVoltage_Cell208 "High voltage battery cell voltage for Cell 208";
CM_ SG_ 1852 HVBatCellVoltage_Cell207 "High voltage battery cell voltage for Cell 207";
CM_ SG_ 1852 HVBatCellVoltage_Cell206 "High voltage battery cell voltage for Cell 206";
CM_ SG_ 1852 HVBatCellVoltage_Cell205 "High voltage battery cell voltage for Cell 205";
CM_ SG_ 1852 HVBatCellVoltage_Cell204 "High voltage battery cell voltage for Cell 204";
CM_ SG_ 1852 HVBatCellVoltage_Cell203 "High voltage battery cell voltage for Cell 203";
CM_ SG_ 1852 HVBatCellVoltage_Cell202 "High voltage battery cell voltage for Cell 202";
CM_ SG_ 1852 HVBatCellVoltage_Cell201 "High voltage battery cell voltage for Cell 201";
CM_ SG_ 1852 HVBatCellVoltage_Cell200 "High voltage battery cell voltage for Cell 200";
CM_ SG_ 1852 HVBatCellVoltage_Cell198 "High voltage battery cell voltage for Cell 198";
CM_ SG_ 1852 HVBatCellVoltage_Cell197 "High voltage battery cell voltage for Cell 197";
CM_ SG_ 1852 HVBatCellVoltage_Cell196 "High voltage battery cell voltage for Cell 196";
CM_ SG_ 1852 HVBatCellVoltage_Cell195 "High voltage battery cell voltage for Cell 195";
CM_ SG_ 1852 HVBatCellVoltage_Cell194 "High voltage battery cell voltage for Cell 194";
CM_ SG_ 1852 HVBatCellVoltage_Cell193 "High voltage battery cell voltage for Cell 193";
CM_ SG_ 2564485397 N_PDU_18DAF115 "This signal is used for diagnostic purposes";
CM_ SG_ 498 V2H_HVCMS_EVSEPresentCurrent "Indicates the EVSE Present Current for both Charging and discharging";
CM_ SG_ 498 EVSE_Supported_ISO1 "Used to report if ISO15118_2 protocol is offered or not.";
CM_ SG_ 498 EVSE_Supported_DIN "Used to report if DIN protocol is offered or not.";
CM_ SG_ 498 EVSE_Supported_SAE "Used to report if SAE protocol is offered or not.";
CM_ SG_ 498 EVSE_Service2_Certificate "Used to report the availability of Contract Certificate services.";
CM_ SG_ 498 EVSE_OfferedPaymentEIM "Used to report if EIM is offered as a method of paymet by EVSE.";
CM_ SG_ 498 EVSE_OfferedPaymentContract "Used to report if Contract is offered as a method of paymet by EVSE.";
CM_ SG_ 498 EVSE_Notification "This signal contains an action that the SECC wants the EVCC to perform.";
CM_ SG_ 498 OBCM_ThermalRunaway "OBCM Thermal Runaway Detection signal";
CM_ SG_ 250 APM_ThermalRunaway "APM Thermal Runaway Detection signal";
CM_ SG_ 498 ReceiptRequired "Signal Used by SECC in order to request a MeteringReceiptReq message to the OBCM.";
CM_ SG_ 502 V2X_HVCMS_SlctdEnergyTransfType "Selected Energy Tranfer Type Other/Custom to V2X functions";
CM_ SG_ 498 V2X_EVSE_Service_6_V2G "DC Vehicle to Home - V2G";
CM_ SG_ 498 V2X_EVSE_Service_5_V2H "DC Vehicle to Home - V2H";
BA_DEF_ SG_ "GenSigTimeoutTime_HCP" INT 0 65535;
BA_DEF_ SG_ "GenSigTimeoutTime_PPIM" INT 0 65535;
BA_DEF_ SG_ "GenSigTimeoutTime_APM2" INT 0 65535;
BA_DEF_ SG_ "GenSigTimeoutTime_VDCM" INT 0 65535;
BA_DEF_ SG_ "GenSigStartValue" INT 0 2147483647;
BA_DEF_ SG_ "GenSigInactiveValue" INT 0 2147483647;
BA_DEF_ SG_ "GenSigSendType" ENUM "NotUsed","OnWrite","OnWriteWithRepetition","OnChange","OnChangeWithRepetition","IfActive","IfActiveWithRepetition","NoSigSendType";
BA_DEF_ SG_ "SystemSignalLongSymbol" STRING ;
BA_DEF_ SG_ "GenSigTimeoutTime_BPCM" INT 0 65535;
BA_DEF_ SG_ "GenSigTimeoutTime_EVCU2" INT 0 65535;
BA_DEF_ SG_ "GenSigTimeoutTime_IDCM" INT 0 65535;
BA_DEF_ SG_ "GenSigTimeoutTime_SGW" INT 0 65535;
BA_DEF_ BO_ "DiagRequest" ENUM "No","Yes";
BA_DEF_ BO_ "Type" ENUM "P","C","PE","COC","PE_Cntrl","E","E_Cntrl","OC","S","BAF","DC","EM","MM","ISO-TP","-";
BA_DEF_ BO_ "DiagResponse" ENUM "No","Yes";
BA_DEF_ BO_ "NmMessage" ENUM "No","Yes";
BA_DEF_ BO_ "GenMsgSendType" ENUM "Cyclic","NotUsed","NotUsed","NotUsed","NotUsed","NotUsed","NotUsed","NotUsed","NoMsgSendType";
BA_DEF_ BO_ "GenMsgNrOfRepetition" INT 0 255;
BA_DEF_ BO_ "GenMsgILSupport" ENUM "No","Yes";
BA_DEF_ BO_ "GenMsgStartDelayTime" INT 0 65535;
BA_DEF_ BO_ "GenMsgCycleTimeFast" INT 0 65535;
BA_DEF_ BO_ "GenMsgCycleTime" INT 0 65535;
BA_DEF_ BO_ "GenMsgDelayTime" INT 0 65535;
BA_DEF_ BO_ "NmAsrMessage" ENUM "No","Yes";
BA_DEF_ BO_ "DiagState" ENUM "No","Yes";
BA_DEF_ BO_ "DiagConnection" HEX 0 65535;
BA_DEF_ BO_ "CanTpFcFrameId" HEX 0 2147483647;
BA_DEF_ BO_ "VFrameFormat" ENUM "StandardCAN","ExtendedCAN","reserved","reserved","reserved","reserved","reserved","reserved","reserved","reserved","reserved","reserved","reserved","reserved","StandardCAN_FD","ExtendedCAN_FD";
BA_DEF_ BO_ "CANFD_BRS" ENUM "0","1";
BA_DEF_DEF_ "GenSigTimeoutTime_HCP" 2500;
BA_DEF_DEF_ "GenSigTimeoutTime_PPIM" 2500;
BA_DEF_DEF_ "GenSigTimeoutTime_APM2" 2500;
BA_DEF_DEF_ "GenSigTimeoutTime_VDCM" 2500;
BA_DEF_DEF_ "GenSigStartValue" 0;
BA_DEF_DEF_ "GenSigInactiveValue" 0;
BA_DEF_DEF_ "GenSigSendType" "NoSigSendType";
BA_DEF_DEF_ "SystemSignalLongSymbol" "";
BA_DEF_DEF_ "GenSigTimeoutTime_BPCM" 2500;
BA_DEF_DEF_ "GenSigTimeoutTime_EVCU2" 2500;
BA_DEF_DEF_ "GenSigTimeoutTime_IDCM" 2500;
BA_DEF_DEF_ "GenSigTimeoutTime_SGW" 2500;
BA_DEF_DEF_ "DiagRequest" "No";
BA_DEF_DEF_ "Type" "-";
BA_DEF_DEF_ "DiagResponse" "No";
BA_DEF_DEF_ "NmMessage" "No";
BA_DEF_DEF_ "GenMsgSendType" "NoMsgSendType";
BA_DEF_DEF_ "GenMsgNrOfRepetition" 0;
BA_DEF_DEF_ "GenMsgILSupport" "No";
BA_DEF_DEF_ "GenMsgStartDelayTime" 0;
BA_DEF_DEF_ "GenMsgCycleTimeFast" 0;
BA_DEF_DEF_ "GenMsgCycleTime" 0;
BA_DEF_DEF_ "GenMsgDelayTime" 0;
BA_DEF_DEF_ "NmAsrMessage" "No";
BA_DEF_DEF_ "DiagState" "No";
BA_DEF_DEF_ "DiagConnection" 0;
BA_DEF_DEF_ "CanTpFcFrameId" 2147483647;
BA_DEF_DEF_ "VFrameFormat" "StandardCAN_FD";
BA_DEF_DEF_ "CANFD_BRS" "0";
BA_ "Type" BO_ 1852 1;
BA_ "GenMsgSendType" BO_ 1852 0;
BA_ "GenMsgILSupport" BO_ 1852 1;
BA_ "GenMsgCycleTime" BO_ 1852 1000;
BA_ "CANFD_BRS" BO_ 1852 1;
BA_ "GenMsgCycleTime" BO_ 1851 1000;
BA_ "CANFD_BRS" BO_ 1851 1;
BA_ "Type" BO_ 1851 1;
BA_ "GenMsgSendType" BO_ 1851 0;
BA_ "GenMsgILSupport" BO_ 1851 1;
BA_ "Type" BO_ 1850 1;
BA_ "GenMsgSendType" BO_ 1850 0;
BA_ "GenMsgILSupport" BO_ 1850 1;
BA_ "GenMsgCycleTime" BO_ 1850 1000;
BA_ "CANFD_BRS" BO_ 1850 1;
BA_ "Type" BO_ 1849 1;
BA_ "GenMsgSendType" BO_ 1849 0;
BA_ "GenMsgILSupport" BO_ 1849 1;
BA_ "GenMsgCycleTime" BO_ 1849 1000;
BA_ "CANFD_BRS" BO_ 1849 1;
BA_ "Type" BO_ 2564485412 8;
BA_ "DiagResponse" BO_ 2564485412 1;
BA_ "DiagConnection" BO_ 2564485412 61732;
BA_ "VFrameFormat" BO_ 2564485412 1;
BA_ "DiagRequest" BO_ 2564433137 1;
BA_ "Type" BO_ 2564433137 8;
BA_ "DiagConnection" BO_ 2564433137 61732;
BA_ "VFrameFormat" BO_ 2564433137 1;
BA_ "Type" BO_ 502 1;
BA_ "GenMsgSendType" BO_ 502 0;
BA_ "GenMsgILSupport" BO_ 502 1;
BA_ "GenMsgCycleTime" BO_ 502 20;
BA_ "CANFD_BRS" BO_ 502 1;
BA_ "Type" BO_ 498 1;
BA_ "GenMsgSendType" BO_ 498 0;
BA_ "GenMsgILSupport" BO_ 498 1;
BA_ "GenMsgCycleTime" BO_ 498 20;
BA_ "CANFD_BRS" BO_ 498 1;
BA_ "Type" BO_ 2654486679 8;
BA_ "NmMessage" BO_ 2654486679 1;
BA_ "NmAsrMessage" BO_ 2654486679 1;
BA_ "VFrameFormat" BO_ 2654486679 15;
BA_ "CANFD_BRS" BO_ 2654486679 1;
BA_ "Type" BO_ 2564682261 8;
BA_ "DiagResponse" BO_ 2564682261 1;
BA_ "DiagConnection" BO_ 2564682261 61973;
BA_ "VFrameFormat" BO_ 2564682261 15;
BA_ "CANFD_BRS" BO_ 2564682261 1;
BA_ "Type" BO_ 2564682260 8;
BA_ "DiagResponse" BO_ 2564682260 1;
BA_ "DiagConnection" BO_ 2564682260 61972;
BA_ "VFrameFormat" BO_ 2564682260 15;
BA_ "CANFD_BRS" BO_ 2564682260 1;
BA_ "Type" BO_ 2564682335 8;
BA_ "DiagResponse" BO_ 2564682335 1;
BA_ "DiagConnection" BO_ 2564682335 62047;
BA_ "VFrameFormat" BO_ 2564682335 15;
BA_ "CANFD_BRS" BO_ 2564682335 1;
BA_ "Type" BO_ 2564682079 8;
BA_ "DiagResponse" BO_ 2564682079 1;
BA_ "DiagConnection" BO_ 2564682079 61791;
BA_ "VFrameFormat" BO_ 2564682079 1;
BA_ "Type" BO_ 2564485396 8;
BA_ "DiagResponse" BO_ 2564485396 1;
BA_ "DiagConnection" BO_ 2564485396 61716;
BA_ "VFrameFormat" BO_ 2564485396 1;
BA_ "Type" BO_ 2564485653 8;
BA_ "DiagResponse" BO_ 2564485653 1;
BA_ "DiagConnection" BO_ 2564485653 61973;
BA_ "VFrameFormat" BO_ 2564485653 15;
BA_ "CANFD_BRS" BO_ 2564485653 1;
BA_ "Type" BO_ 2564485652 8;
BA_ "DiagResponse" BO_ 2564485652 1;
BA_ "DiagConnection" BO_ 2564485652 61972;
BA_ "VFrameFormat" BO_ 2564485652 15;
BA_ "CANFD_BRS" BO_ 2564485652 1;
BA_ "Type" BO_ 2564485727 8;
BA_ "DiagResponse" BO_ 2564485727 1;
BA_ "DiagConnection" BO_ 2564485727 62047;
BA_ "VFrameFormat" BO_ 2564485727 15;
BA_ "CANFD_BRS" BO_ 2564485727 1;
BA_ "Type" BO_ 2564485471 8;
BA_ "DiagResponse" BO_ 2564485471 1;
BA_ "DiagConnection" BO_ 2564485471 61791;
BA_ "VFrameFormat" BO_ 2564485471 1;
BA_ "DiagRequest" BO_ 2564429297 1;
BA_ "Type" BO_ 2564429297 8;
BA_ "DiagConnection" BO_ 2564429297 61717;
BA_ "VFrameFormat" BO_ 2564429297 1;
BA_ "DiagRequest" BO_ 2564429041 1;
BA_ "Type" BO_ 2564429041 8;
BA_ "DiagConnection" BO_ 2564429041 61716;
BA_ "VFrameFormat" BO_ 2564429041 1;
BA_ "DiagRequest" BO_ 2564429298 1;
BA_ "Type" BO_ 2564429298 8;
BA_ "DiagConnection" BO_ 2564429298 61973;
BA_ "VFrameFormat" BO_ 2564429298 15;
BA_ "CANFD_BRS" BO_ 2564429298 1;
BA_ "DiagRequest" BO_ 2564429042 1;
BA_ "Type" BO_ 2564429042 8;
BA_ "DiagConnection" BO_ 2564429042 61972;
BA_ "VFrameFormat" BO_ 2564429042 15;
BA_ "CANFD_BRS" BO_ 2564429042 1;
BA_ "DiagRequest" BO_ 2564448242 1;
BA_ "Type" BO_ 2564448242 8;
BA_ "DiagConnection" BO_ 2564448242 62047;
BA_ "VFrameFormat" BO_ 2564448242 15;
BA_ "CANFD_BRS" BO_ 2564448242 1;
BA_ "DiagRequest" BO_ 2564448241 1;
BA_ "Type" BO_ 2564448241 8;
BA_ "DiagConnection" BO_ 2564448241 61791;
BA_ "VFrameFormat" BO_ 2564448241 1;
BA_ "Type" BO_ 2651930775 11;
BA_ "GenMsgILSupport" BO_ 2651930775 1;
BA_ "VFrameFormat" BO_ 2651930775 15;
BA_ "CANFD_BRS" BO_ 2651930775 1;
BA_ "Type" BO_ 244 1;
BA_ "GenMsgSendType" BO_ 244 0;
BA_ "GenMsgILSupport" BO_ 244 1;
BA_ "GenMsgCycleTime" BO_ 244 10;
BA_ "CANFD_BRS" BO_ 244 1;
BA_ "Type" BO_ 252 1;
BA_ "GenMsgSendType" BO_ 252 0;
BA_ "GenMsgILSupport" BO_ 252 1;
BA_ "GenMsgCycleTime" BO_ 252 10;
BA_ "CANFD_BRS" BO_ 252 1;
BA_ "Type" BO_ 500 1;
BA_ "GenMsgSendType" BO_ 500 0;
BA_ "GenMsgILSupport" BO_ 500 1;
BA_ "GenMsgCycleTime" BO_ 500 20;
BA_ "CANFD_BRS" BO_ 500 1;
BA_ "Type" BO_ 250 1;
BA_ "GenMsgSendType" BO_ 250 0;
BA_ "GenMsgILSupport" BO_ 250 1;
BA_ "GenMsgCycleTime" BO_ 250 20;
BA_ "CANFD_BRS" BO_ 250 1;
BA_ "Type" BO_ 2564485397 8;
BA_ "DiagResponse" BO_ 2564485397 1;
BA_ "DiagConnection" BO_ 2564485397 61717;
BA_ "VFrameFormat" BO_ 2564485397 1;
BA_ "GenSigTimeoutTime_APM2" SG_ 252 BMS_CntctrsMidTrmOpeningWarn 0;
BA_ "GenSigTimeoutTime_BPCM" SG_ 252 BMS_CntctrsMidTrmOpeningWarn 0;
BA_ "GenSigTimeoutTime_EVCU2" SG_ 252 BMS_CntctrsMidTrmOpeningWarn 0;
BA_ "GenSigTimeoutTime_IDCM" SG_ 252 BMS_CntctrsMidTrmOpeningWarn 0;
BA_ "GenSigTimeoutTime_APM2" SG_ 252 BMS_CntctrsShtTrmOpeningWarn 0;
BA_ "GenSigTimeoutTime_BPCM" SG_ 252 BMS_CntctrsShtTrmOpeningWarn 0;
BA_ "GenSigTimeoutTime_EVCU2" SG_ 252 BMS_CntctrsShtTrmOpeningWarn 0;
BA_ "GenSigTimeoutTime_IDCM" SG_ 252 BMS_CntctrsShtTrmOpeningWarn 0;
BA_ "GenSigTimeoutTime_APM2" SG_ 252 BMS_HV_Current_Discharge_ShrTrm 0;
BA_ "GenSigTimeoutTime_BPCM" SG_ 252 BMS_HV_Current_Discharge_ShrTrm 0;
BA_ "GenSigTimeoutTime_EVCU2" SG_ 252 BMS_HV_Current_Discharge_ShrTrm 0;
BA_ "GenSigTimeoutTime_IDCM" SG_ 252 BMS_HV_Current_Discharge_ShrTrm 0;
BA_ "GenSigTimeoutTime_APM2" SG_ 252 BMS_HV_Current_MaxDischrg_LgTrm 0;
BA_ "GenSigTimeoutTime_BPCM" SG_ 252 BMS_HV_Current_MaxDischrg_LgTrm 0;
BA_ "GenSigTimeoutTime_EVCU2" SG_ 252 BMS_HV_Current_MaxDischrg_LgTrm 0;
BA_ "GenSigTimeoutTime_IDCM" SG_ 252 BMS_HV_Current_MaxDischrg_LgTrm 0;
BA_ "GenSigTimeoutTime_APM2" SG_ 252 BMS_HV_Current_MaxDischrg_MdTrm 0;
BA_ "GenSigTimeoutTime_BPCM" SG_ 252 BMS_HV_Current_MaxDischrg_MdTrm 0;
BA_ "GenSigTimeoutTime_EVCU2" SG_ 252 BMS_HV_Current_MaxDischrg_MdTrm 0;
BA_ "GenSigTimeoutTime_IDCM" SG_ 252 BMS_HV_Current_MaxDischrg_MdTrm 0;
BA_ "GenSigTimeoutTime_APM2" SG_ 2564485396 N_PDU_18DAF114 0;
BA_ "GenSigTimeoutTime_BPCM" SG_ 2564485396 N_PDU_18DAF114 0;
BA_ "GenSigTimeoutTime_EVCU2" SG_ 2564485396 N_PDU_18DAF114 0;
BA_ "GenSigTimeoutTime_IDCM" SG_ 2564485396 N_PDU_18DAF114 0;
BA_ "GenSigTimeoutTime_SGW" SG_ 2564485396 N_PDU_18DAF114 0;
BA_ "GenSigTimeoutTime_APM2" SG_ 2564429041 N_PDU_18DA14F1 0;
BA_ "GenSigTimeoutTime_BPCM" SG_ 2564429041 N_PDU_18DA14F1 0;
BA_ "GenSigTimeoutTime_EVCU2" SG_ 2564429041 N_PDU_18DA14F1 0;
BA_ "GenSigTimeoutTime_IDCM" SG_ 2564429041 N_PDU_18DA14F1 0;
BA_ "GenSigTimeoutTime_SGW" SG_ 2564429041 N_PDU_18DA14F1 0;
BA_ "GenSigTimeoutTime_APM2" SG_ 2564429297 N_PDU_18DA15F1 0;
BA_ "GenSigTimeoutTime_BPCM" SG_ 2564429297 N_PDU_18DA15F1 0;
BA_ "GenSigTimeoutTime_EVCU2" SG_ 2564429297 N_PDU_18DA15F1 0;
BA_ "GenSigTimeoutTime_IDCM" SG_ 2564429297 N_PDU_18DA15F1 0;
BA_ "GenSigTimeoutTime_SGW" SG_ 2564429297 N_PDU_18DA15F1 0;
BA_ "GenSigTimeoutTime_VDCM" SG_ 2564448242 N_PDU_18DA5FF2 0;
BA_ "GenSigTimeoutTime_APM2" SG_ 2564448242 N_PDU_18DA5FF2 0;
BA_ "GenSigTimeoutTime_BPCM" SG_ 2564448242 N_PDU_18DA5FF2 0;
BA_ "GenSigTimeoutTime_EVCU2" SG_ 2564448242 N_PDU_18DA5FF2 0;
BA_ "GenSigTimeoutTime_IDCM" SG_ 2564448242 N_PDU_18DA5FF2 0;
BA_ "GenSigTimeoutTime_SGW" SG_ 2564448242 N_PDU_18DA5FF2 0;
BA_ "GenSigTimeoutTime_APM2" SG_ 2564448241 N_PDU_18DA5FF1 0;
BA_ "GenSigTimeoutTime_VDCM" SG_ 2564448241 N_PDU_18DA5FF1 0;
BA_ "GenSigTimeoutTime_BPCM" SG_ 2564448241 N_PDU_18DA5FF1 0;
BA_ "GenSigTimeoutTime_EVCU2" SG_ 2564448241 N_PDU_18DA5FF1 0;
BA_ "GenSigTimeoutTime_IDCM" SG_ 2564448241 N_PDU_18DA5FF1 0;
BA_ "GenSigTimeoutTime_SGW" SG_ 2564448241 N_PDU_18DA5FF1 0;
BA_ "GenSigTimeoutTime_APM2" SG_ 2654486679 CBV_bit0_RepeatMessageRequestBit_1E384097 0;
BA_ "GenSigTimeoutTime_VDCM" SG_ 2654486679 CBV_bit0_RepeatMessageRequestBit_1E384097 0;
BA_ "GenSigTimeoutTime_BPCM" SG_ 2654486679 CBV_bit0_RepeatMessageRequestBit_1E384097 0;
BA_ "GenSigTimeoutTime_EVCU2" SG_ 2654486679 CBV_bit0_RepeatMessageRequestBit_1E384097 0;
BA_ "GenSigTimeoutTime_IDCM" SG_ 2654486679 CBV_bit0_RepeatMessageRequestBit_1E384097 0;
BA_ "GenSigTimeoutTime_SGW" SG_ 2654486679 CBV_bit0_RepeatMessageRequestBit_1E384097 0;
BA_ "GenSigTimeoutTime_APM2" SG_ 2564433137 N_PDU_18DA24F1 0;
BA_ "GenSigTimeoutTime_VDCM" SG_ 2564433137 N_PDU_18DA24F1 0;
BA_ "GenSigTimeoutTime_BPCM" SG_ 2564433137 N_PDU_18DA24F1 0;
BA_ "GenSigTimeoutTime_EVCU2" SG_ 2564433137 N_PDU_18DA24F1 0;
BA_ "GenSigTimeoutTime_IDCM" SG_ 2564433137 N_PDU_18DA24F1 0;
BA_ "GenSigTimeoutTime_SGW" SG_ 2564433137 N_PDU_18DA24F1 0;
BA_ "GenSigTimeoutTime_APM2" SG_ 2564485412 N_PDU_18DAF124 0;
BA_ "GenSigTimeoutTime_VDCM" SG_ 2564485412 N_PDU_18DAF124 0;
BA_ "GenSigTimeoutTime_BPCM" SG_ 2564485412 N_PDU_18DAF124 0;
BA_ "GenSigTimeoutTime_EVCU2" SG_ 2564485412 N_PDU_18DAF124 0;
BA_ "GenSigTimeoutTime_IDCM" SG_ 2564485412 N_PDU_18DAF124 0;
BA_ "GenSigTimeoutTime_SGW" SG_ 2564485412 N_PDU_18DAF124 0;
BA_ "GenSigTimeoutTime_APM2" SG_ 2654486679 CBV_bit1_1E384097 0;
BA_ "GenSigTimeoutTime_VDCM" SG_ 2654486679 CBV_bit1_1E384097 0;
BA_ "GenSigTimeoutTime_BPCM" SG_ 2654486679 CBV_bit1_1E384097 0;
BA_ "GenSigTimeoutTime_EVCU2" SG_ 2654486679 CBV_bit1_1E384097 0;
BA_ "GenSigTimeoutTime_IDCM" SG_ 2654486679 CBV_bit1_1E384097 0;
BA_ "GenSigTimeoutTime_SGW" SG_ 2654486679 CBV_bit1_1E384097 0;
BA_ "GenSigTimeoutTime_APM2" SG_ 2654486679 CBV_bit2_1E384097 0;
BA_ "GenSigTimeoutTime_VDCM" SG_ 2654486679 CBV_bit2_1E384097 0;
BA_ "GenSigTimeoutTime_BPCM" SG_ 2654486679 CBV_bit2_1E384097 0;
BA_ "GenSigTimeoutTime_EVCU2" SG_ 2654486679 CBV_bit2_1E384097 0;
BA_ "GenSigTimeoutTime_IDCM" SG_ 2654486679 CBV_bit2_1E384097 0;
BA_ "GenSigTimeoutTime_SGW" SG_ 2654486679 CBV_bit2_1E384097 0;
BA_ "GenSigTimeoutTime_APM2" SG_ 2654486679 CBV_bit3_NMCoordinatorBit_1E384097 0;
BA_ "GenSigTimeoutTime_VDCM" SG_ 2654486679 CBV_bit3_NMCoordinatorBit_1E384097 0;
BA_ "GenSigTimeoutTime_BPCM" SG_ 2654486679 CBV_bit3_NMCoordinatorBit_1E384097 0;
BA_ "GenSigTimeoutTime_EVCU2" SG_ 2654486679 CBV_bit3_NMCoordinatorBit_1E384097 0;
BA_ "GenSigTimeoutTime_IDCM" SG_ 2654486679 CBV_bit3_NMCoordinatorBit_1E384097 0;
BA_ "GenSigTimeoutTime_SGW" SG_ 2654486679 CBV_bit3_NMCoordinatorBit_1E384097 0;
BA_ "GenSigTimeoutTime_APM2" SG_ 2654486679 CBV_bit4_ActiveWakeupBit_1E384097 0;
BA_ "GenSigTimeoutTime_VDCM" SG_ 2654486679 CBV_bit4_ActiveWakeupBit_1E384097 0;
BA_ "GenSigTimeoutTime_BPCM" SG_ 2654486679 CBV_bit4_ActiveWakeupBit_1E384097 0;
BA_ "GenSigTimeoutTime_EVCU2" SG_ 2654486679 CBV_bit4_ActiveWakeupBit_1E384097 0;
BA_ "GenSigTimeoutTime_IDCM" SG_ 2654486679 CBV_bit4_ActiveWakeupBit_1E384097 0;
BA_ "GenSigTimeoutTime_SGW" SG_ 2654486679 CBV_bit4_ActiveWakeupBit_1E384097 0;
BA_ "GenSigTimeoutTime_APM2" SG_ 2654486679 CBV_bit5_1E384097 0;
BA_ "GenSigTimeoutTime_VDCM" SG_ 2654486679 CBV_bit5_1E384097 0;
BA_ "GenSigTimeoutTime_BPCM" SG_ 2654486679 CBV_bit5_1E384097 0;
BA_ "GenSigTimeoutTime_EVCU2" SG_ 2654486679 CBV_bit5_1E384097 0;
BA_ "GenSigTimeoutTime_IDCM" SG_ 2654486679 CBV_bit5_1E384097 0;
BA_ "GenSigTimeoutTime_SGW" SG_ 2654486679 CBV_bit5_1E384097 0;
BA_ "GenSigTimeoutTime_APM2" SG_ 2654486679 CBV_bit6_PartialNtwInfBit_1E384097 0;
BA_ "GenSigTimeoutTime_VDCM" SG_ 2654486679 CBV_bit6_PartialNtwInfBit_1E384097 0;
BA_ "GenSigTimeoutTime_BPCM" SG_ 2654486679 CBV_bit6_PartialNtwInfBit_1E384097 0;
BA_ "GenSigTimeoutTime_EVCU2" SG_ 2654486679 CBV_bit6_PartialNtwInfBit_1E384097 0;
BA_ "GenSigTimeoutTime_IDCM" SG_ 2654486679 CBV_bit6_PartialNtwInfBit_1E384097 0;
BA_ "GenSigTimeoutTime_SGW" SG_ 2654486679 CBV_bit6_PartialNtwInfBit_1E384097 0;
BA_ "GenSigTimeoutTime_APM2" SG_ 2654486679 SourceNodeIdentifier_1E384097 0;
BA_ "GenSigTimeoutTime_VDCM" SG_ 2654486679 SourceNodeIdentifier_1E384097 0;
BA_ "GenSigTimeoutTime_BPCM" SG_ 2654486679 SourceNodeIdentifier_1E384097 0;
BA_ "GenSigTimeoutTime_EVCU2" SG_ 2654486679 SourceNodeIdentifier_1E384097 0;
BA_ "GenSigTimeoutTime_IDCM" SG_ 2654486679 SourceNodeIdentifier_1E384097 0;
BA_ "GenSigTimeoutTime_SGW" SG_ 2654486679 SourceNodeIdentifier_1E384097 0;
BA_ "GenSigTimeoutTime_APM2" SG_ 2654486679 CBV_bit7_1E384097 0;
BA_ "GenSigTimeoutTime_VDCM" SG_ 2654486679 CBV_bit7_1E384097 0;
BA_ "GenSigTimeoutTime_BPCM" SG_ 2654486679 CBV_bit7_1E384097 0;
BA_ "GenSigTimeoutTime_EVCU2" SG_ 2654486679 CBV_bit7_1E384097 0;
BA_ "GenSigTimeoutTime_IDCM" SG_ 2654486679 CBV_bit7_1E384097 0;
BA_ "GenSigTimeoutTime_SGW" SG_ 2654486679 CBV_bit7_1E384097 0;
BA_ "GenSigTimeoutTime_APM2" SG_ 2564682079 N_PDU_18DDF15F 0;
BA_ "GenSigTimeoutTime_VDCM" SG_ 2564682079 N_PDU_18DDF15F 0;
BA_ "GenSigTimeoutTime_BPCM" SG_ 2564682079 N_PDU_18DDF15F 0;
BA_ "GenSigTimeoutTime_EVCU2" SG_ 2564682079 N_PDU_18DDF15F 0;
BA_ "GenSigTimeoutTime_IDCM" SG_ 2564682079 N_PDU_18DDF15F 0;
BA_ "GenSigTimeoutTime_SGW" SG_ 2564682079 N_PDU_18DDF15F 0;
BA_ "GenSigTimeoutTime_VDCM" SG_ 2564682335 N_PDU_18DDF25F 0;
BA_ "GenSigTimeoutTime_APM2" SG_ 2564682335 N_PDU_18DDF25F 0;
BA_ "GenSigTimeoutTime_BPCM" SG_ 2564682335 N_PDU_18DDF25F 0;
BA_ "GenSigTimeoutTime_EVCU2" SG_ 2564682335 N_PDU_18DDF25F 0;
BA_ "GenSigTimeoutTime_IDCM" SG_ 2564682335 N_PDU_18DDF25F 0;
BA_ "GenSigTimeoutTime_SGW" SG_ 2564682335 N_PDU_18DDF25F 0;
BA_ "GenSigTimeoutTime_VDCM" SG_ 2564485727 N_PDU_18DAF25F 0;
BA_ "GenSigTimeoutTime_APM2" SG_ 2564485727 N_PDU_18DAF25F 0;
BA_ "GenSigTimeoutTime_BPCM" SG_ 2564485727 N_PDU_18DAF25F 0;
BA_ "GenSigTimeoutTime_EVCU2" SG_ 2564485727 N_PDU_18DAF25F 0;
BA_ "GenSigTimeoutTime_IDCM" SG_ 2564485727 N_PDU_18DAF25F 0;
BA_ "GenSigTimeoutTime_SGW" SG_ 2564485727 N_PDU_18DAF25F 0;
BA_ "GenSigTimeoutTime_APM2" SG_ 2564485471 N_PDU_18DAF15F 0;
BA_ "GenSigTimeoutTime_VDCM" SG_ 2564485471 N_PDU_18DAF15F 0;
BA_ "GenSigTimeoutTime_BPCM" SG_ 2564485471 N_PDU_18DAF15F 0;
BA_ "GenSigTimeoutTime_EVCU2" SG_ 2564485471 N_PDU_18DAF15F 0;
BA_ "GenSigTimeoutTime_IDCM" SG_ 2564485471 N_PDU_18DAF15F 0;
BA_ "GenSigTimeoutTime_SGW" SG_ 2564485471 N_PDU_18DAF15F 0;
BA_ "GenSigTimeoutTime_APM2" SG_ 2651930775 Digit_11_APM2 0;
BA_ "GenSigTimeoutTime_BPCM" SG_ 2651930775 Digit_11_APM2 0;
BA_ "GenSigTimeoutTime_IDCM" SG_ 2651930775 Digit_11_APM2 0;
BA_ "GenSigTimeoutTime_SGW" SG_ 2651930775 Digit_11_APM2 0;
BA_ "GenSigTimeoutTime_BPCM" SG_ 2651930775 Digit_10_APM2 0;
BA_ "GenSigTimeoutTime_IDCM" SG_ 2651930775 Digit_10_APM2 0;
BA_ "GenSigTimeoutTime_SGW" SG_ 2651930775 Digit_10_APM2 0;
BA_ "GenSigTimeoutTime_APM2" SG_ 1849 HVBatCellVoltage_Cell115 0;
BA_ "GenSigTimeoutTime_VDCM" SG_ 1849 HVBatCellVoltage_Cell115 0;
BA_ "GenSigTimeoutTime_VDCM" SG_ 1849 HVBatCellVoltage_Cell135 0;
BA_ "GenSigTimeoutTime_VDCM" SG_ 1849 HVBatCellVoltage_Cell134 0;
BA_ "GenSigTimeoutTime_VDCM" SG_ 1849 HVBatCellVoltage_Cell133 0;
BA_ "GenSigTimeoutTime_VDCM" SG_ 1849 HVBatCellVoltage_Cell132 0;
BA_ "GenSigTimeoutTime_VDCM" SG_ 1849 HVBatCellVoltage_Cell131 0;
BA_ "GenSigTimeoutTime_VDCM" SG_ 1849 HVBatCellVoltage_Cell130 0;
BA_ "GenSigTimeoutTime_VDCM" SG_ 1849 HVBatCellVoltage_Cell129 0;
BA_ "GenSigTimeoutTime_APM2" SG_ 1849 HVBatCellVoltage_Cell129 0;
BA_ "GenSigTimeoutTime_BPCM" SG_ 1849 HVBatCellVoltage_Cell129 0;
BA_ "GenSigTimeoutTime_EVCU2" SG_ 1849 HVBatCellVoltage_Cell129 0;
BA_ "GenSigTimeoutTime_IDCM" SG_ 1849 HVBatCellVoltage_Cell129 0;
BA_ "GenSigTimeoutTime_VDCM" SG_ 1849 HVBatCellVoltage_Cell128 0;
BA_ "GenSigTimeoutTime_APM2" SG_ 1849 HVBatCellVoltage_Cell128 0;
BA_ "GenSigTimeoutTime_BPCM" SG_ 1849 HVBatCellVoltage_Cell128 0;
BA_ "GenSigTimeoutTime_EVCU2" SG_ 1849 HVBatCellVoltage_Cell128 0;
BA_ "GenSigTimeoutTime_IDCM" SG_ 1849 HVBatCellVoltage_Cell128 0;
BA_ "GenSigTimeoutTime_VDCM" SG_ 1849 HVBatCellVoltage_Cell127 0;
BA_ "GenSigTimeoutTime_APM2" SG_ 1849 HVBatCellVoltage_Cell127 0;
BA_ "GenSigTimeoutTime_BPCM" SG_ 1849 HVBatCellVoltage_Cell127 0;
BA_ "GenSigTimeoutTime_EVCU2" SG_ 1849 HVBatCellVoltage_Cell127 0;
BA_ "GenSigTimeoutTime_IDCM" SG_ 1849 HVBatCellVoltage_Cell127 0;
BA_ "GenSigTimeoutTime_VDCM" SG_ 1849 HVBatCellVoltage_Cell126 0;
BA_ "GenSigTimeoutTime_APM2" SG_ 1849 HVBatCellVoltage_Cell126 0;
BA_ "GenSigTimeoutTime_BPCM" SG_ 1849 HVBatCellVoltage_Cell126 0;
BA_ "GenSigTimeoutTime_EVCU2" SG_ 1849 HVBatCellVoltage_Cell126 0;
BA_ "GenSigTimeoutTime_IDCM" SG_ 1849 HVBatCellVoltage_Cell126 0;
BA_ "GenSigTimeoutTime_VDCM" SG_ 1849 HVBatCellVoltage_Cell125 0;
BA_ "GenSigTimeoutTime_APM2" SG_ 1849 HVBatCellVoltage_Cell125 0;
BA_ "GenSigTimeoutTime_BPCM" SG_ 1849 HVBatCellVoltage_Cell125 0;
BA_ "GenSigTimeoutTime_EVCU2" SG_ 1849 HVBatCellVoltage_Cell125 0;
BA_ "GenSigTimeoutTime_IDCM" SG_ 1849 HVBatCellVoltage_Cell125 0;
BA_ "GenSigTimeoutTime_VDCM" SG_ 1849 HVBatCellVoltage_Cell124 0;
BA_ "GenSigTimeoutTime_APM2" SG_ 1849 HVBatCellVoltage_Cell124 0;
BA_ "GenSigTimeoutTime_BPCM" SG_ 1849 HVBatCellVoltage_Cell124 0;
BA_ "GenSigTimeoutTime_EVCU2" SG_ 1849 HVBatCellVoltage_Cell124 0;
BA_ "GenSigTimeoutTime_IDCM" SG_ 1849 HVBatCellVoltage_Cell124 0;
BA_ "GenSigTimeoutTime_APM2" SG_ 1849 HVBatCellVoltage_Cell123 0;
BA_ "GenSigTimeoutTime_BPCM" SG_ 1849 HVBatCellVoltage_Cell123 0;
BA_ "GenSigTimeoutTime_EVCU2" SG_ 1849 HVBatCellVoltage_Cell123 0;
BA_ "GenSigTimeoutTime_IDCM" SG_ 1849 HVBatCellVoltage_Cell123 0;
BA_ "GenSigTimeoutTime_VDCM" SG_ 1849 HVBatCellVoltage_Cell123 0;
BA_ "GenSigTimeoutTime_APM2" SG_ 1849 HVBatCellVoltage_Cell122 0;
BA_ "GenSigTimeoutTime_BPCM" SG_ 1849 HVBatCellVoltage_Cell122 0;
BA_ "GenSigTimeoutTime_EVCU2" SG_ 1849 HVBatCellVoltage_Cell122 0;
BA_ "GenSigTimeoutTime_IDCM" SG_ 1849 HVBatCellVoltage_Cell122 0;
BA_ "GenSigTimeoutTime_VDCM" SG_ 1849 HVBatCellVoltage_Cell122 0;
BA_ "GenSigTimeoutTime_BPCM" SG_ 1849 HVBatCellVoltage_Cell121 0;
BA_ "GenSigTimeoutTime_EVCU2" SG_ 1849 HVBatCellVoltage_Cell121 0;
BA_ "GenSigTimeoutTime_IDCM" SG_ 1849 HVBatCellVoltage_Cell121 0;
BA_ "GenSigTimeoutTime_VDCM" SG_ 1849 HVBatCellVoltage_Cell121 0;
BA_ "GenSigTimeoutTime_APM2" SG_ 1849 HVBatCellVoltage_Cell121 0;
BA_ "GenSigTimeoutTime_VDCM" SG_ 1849 HVBatCellVoltage_Cell120 0;
BA_ "GenSigTimeoutTime_APM2" SG_ 1849 HVBatCellVoltage_Cell120 0;
BA_ "GenSigTimeoutTime_BPCM" SG_ 1849 HVBatCellVoltage_Cell120 0;
BA_ "GenSigTimeoutTime_EVCU2" SG_ 1849 HVBatCellVoltage_Cell120 0;
BA_ "GenSigTimeoutTime_IDCM" SG_ 1849 HVBatCellVoltage_Cell120 0;
BA_ "GenSigTimeoutTime_VDCM" SG_ 1849 HVBatCellVoltage_Cell118 0;
BA_ "GenSigTimeoutTime_APM2" SG_ 1849 HVBatCellVoltage_Cell118 0;
BA_ "GenSigTimeoutTime_BPCM" SG_ 1849 HVBatCellVoltage_Cell118 0;
BA_ "GenSigTimeoutTime_EVCU2" SG_ 1849 HVBatCellVoltage_Cell118 0;
BA_ "GenSigTimeoutTime_IDCM" SG_ 1849 HVBatCellVoltage_Cell118 0;
BA_ "GenSigTimeoutTime_VDCM" SG_ 1849 HVBatCellVoltage_Cell119 0;
BA_ "GenSigTimeoutTime_APM2" SG_ 1849 HVBatCellVoltage_Cell119 0;
BA_ "GenSigTimeoutTime_BPCM" SG_ 1849 HVBatCellVoltage_Cell119 0;
BA_ "GenSigTimeoutTime_EVCU2" SG_ 1849 HVBatCellVoltage_Cell119 0;
BA_ "GenSigTimeoutTime_IDCM" SG_ 1849 HVBatCellVoltage_Cell119 0;
BA_ "GenSigTimeoutTime_VDCM" SG_ 1849 HVBatCellVoltage_Cell117 0;
BA_ "GenSigTimeoutTime_VDCM" SG_ 1849 HVBatCellVoltage_Cell116 0;
BA_ "GenSigTimeoutTime_APM2" SG_ 1849 HVBatCellVoltage_Cell114 0;
BA_ "GenSigTimeoutTime_BPCM" SG_ 1849 HVBatCellVoltage_Cell114 0;
BA_ "GenSigTimeoutTime_EVCU2" SG_ 1849 HVBatCellVoltage_Cell114 0;
BA_ "GenSigTimeoutTime_IDCM" SG_ 1849 HVBatCellVoltage_Cell114 0;
BA_ "GenSigTimeoutTime_VDCM" SG_ 1849 HVBatCellVoltage_Cell114 0;
BA_ "GenSigTimeoutTime_APM2" SG_ 1849 HVBatCellVoltage_Cell112 0;
BA_ "GenSigTimeoutTime_BPCM" SG_ 1849 HVBatCellVoltage_Cell112 0;
BA_ "GenSigTimeoutTime_EVCU2" SG_ 1849 HVBatCellVoltage_Cell112 0;
BA_ "GenSigTimeoutTime_IDCM" SG_ 1849 HVBatCellVoltage_Cell112 0;
BA_ "GenSigTimeoutTime_VDCM" SG_ 1849 HVBatCellVoltage_Cell112 0;
BA_ "GenSigTimeoutTime_APM2" SG_ 1849 HVBatCellVoltage_Cell113 0;
BA_ "GenSigTimeoutTime_BPCM" SG_ 1849 HVBatCellVoltage_Cell113 0;
BA_ "GenSigTimeoutTime_EVCU2" SG_ 1849 HVBatCellVoltage_Cell113 0;
BA_ "GenSigTimeoutTime_IDCM" SG_ 1849 HVBatCellVoltage_Cell113 0;
BA_ "GenSigTimeoutTime_VDCM" SG_ 1849 HVBatCellVoltage_Cell113 0;
BA_ "GenSigTimeoutTime_VDCM" SG_ 1849 HVBatCellVoltage_Cell111 0;
BA_ "GenSigTimeoutTime_VDCM" SG_ 1849 HVBatCellVoltage_Cell110 0;
BA_ "GenSigTimeoutTime_VDCM" SG_ 1849 HVBatCellVoltage_Cell109 0;
BA_ "GenSigTimeoutTime_VDCM" SG_ 2651930775 Digit_11_APM2 0;
BA_ "GenSigTimeoutTime_APM2" SG_ 2651930775 Digit_07_APM2 0;
BA_ "GenSigTimeoutTime_BPCM" SG_ 2651930775 Digit_07_APM2 0;
BA_ "GenSigTimeoutTime_IDCM" SG_ 2651930775 Digit_07_APM2 0;
BA_ "GenSigTimeoutTime_SGW" SG_ 2651930775 Digit_07_APM2 0;
BA_ "GenSigTimeoutTime_VDCM" SG_ 2651930775 Digit_07_APM2 0;
BA_ "GenSigTimeoutTime_APM2" SG_ 2651930775 Digit_08_APM2 0;
BA_ "GenSigTimeoutTime_BPCM" SG_ 2651930775 Digit_08_APM2 0;
BA_ "GenSigTimeoutTime_IDCM" SG_ 2651930775 Digit_08_APM2 0;
BA_ "GenSigTimeoutTime_SGW" SG_ 2651930775 Digit_08_APM2 0;
BA_ "GenSigTimeoutTime_VDCM" SG_ 2651930775 Digit_08_APM2 0;
BA_ "GenSigTimeoutTime_APM2" SG_ 2651930775 Digit_10_APM2 0;
BA_ "GenSigTimeoutTime_VDCM" SG_ 2651930775 Digit_10_APM2 0;
BA_ "GenSigTimeoutTime_HCP" SG_ 250 APM_ThermalRunaway 0;
BA_ "GenSigTimeoutTime_PPIM" SG_ 250 APM_ThermalRunaway 0;
BA_ "GenSigTimeoutTime_APM2" SG_ 250 APM_ThermalRunaway 0;
BA_ "GenSigTimeoutTime_VDCM" SG_ 250 APM_ThermalRunaway 0;
BA_ "GenSigTimeoutTime_BPCM" SG_ 250 APM_ThermalRunaway 0;
BA_ "GenSigTimeoutTime_IDCM" SG_ 250 APM_ThermalRunaway 0;
BA_ "GenSigTimeoutTime_SGW" SG_ 250 APM_ThermalRunaway 0;
BA_ "GenSigTimeoutTime_HCP" SG_ 498 OBCM_ThermalRunaway 0;
BA_ "GenSigTimeoutTime_PPIM" SG_ 498 OBCM_ThermalRunaway 0;
BA_ "GenSigTimeoutTime_APM2" SG_ 498 OBCM_ThermalRunaway 0;
BA_ "GenSigTimeoutTime_VDCM" SG_ 498 OBCM_ThermalRunaway 0;
BA_ "GenSigTimeoutTime_BPCM" SG_ 498 OBCM_ThermalRunaway 0;
BA_ "GenSigTimeoutTime_IDCM" SG_ 498 OBCM_ThermalRunaway 0;
BA_ "GenSigTimeoutTime_SGW" SG_ 498 OBCM_ThermalRunaway 0;
BA_ "GenSigTimeoutTime_HCP" SG_ 498 EVSE_Supported_ISO1 0;
BA_ "GenSigTimeoutTime_PPIM" SG_ 498 EVSE_Supported_ISO1 0;
BA_ "GenSigTimeoutTime_APM2" SG_ 498 EVSE_Supported_ISO1 0;
BA_ "GenSigTimeoutTime_VDCM" SG_ 498 EVSE_Supported_ISO1 0;
BA_ "GenSigTimeoutTime_HCP" SG_ 498 EVSE_Supported_DIN 0;
BA_ "GenSigTimeoutTime_PPIM" SG_ 498 EVSE_Supported_DIN 0;
BA_ "GenSigTimeoutTime_APM2" SG_ 498 EVSE_Supported_DIN 0;
BA_ "GenSigTimeoutTime_VDCM" SG_ 498 EVSE_Supported_DIN 0;
BA_ "GenSigTimeoutTime_HCP" SG_ 498 CRC_OBCM_VDCM 0;
BA_ "GenSigTimeoutTime_PPIM" SG_ 498 CRC_OBCM_VDCM 0;
BA_ "GenSigTimeoutTime_APM2" SG_ 498 CRC_OBCM_VDCM 0;
BA_ "GenSigTimeoutTime_BPCM" SG_ 498 EVSE_Supported_SAE 0;
BA_ "GenSigTimeoutTime_IDCM" SG_ 498 EVSE_Supported_SAE 0;
BA_ "GenSigTimeoutTime_SGW" SG_ 498 EVSE_Supported_SAE 0;
BA_ "GenSigTimeoutTime_HCP" SG_ 498 EVSE_Supported_SAE 0;
BA_ "GenSigTimeoutTime_PPIM" SG_ 498 EVSE_Supported_SAE 0;
BA_ "GenSigTimeoutTime_APM2" SG_ 498 EVSE_Supported_SAE 0;
BA_ "GenSigTimeoutTime_BPCM" SG_ 498 EVSE_Service2_Certificate 0;
BA_ "GenSigTimeoutTime_IDCM" SG_ 498 EVSE_Service2_Certificate 0;
BA_ "GenSigTimeoutTime_SGW" SG_ 498 EVSE_Service2_Certificate 0;
BA_ "GenSigTimeoutTime_HCP" SG_ 498 EVSE_Service2_Certificate 0;
BA_ "GenSigTimeoutTime_PPIM" SG_ 498 EVSE_Service2_Certificate 0;
BA_ "GenSigTimeoutTime_APM2" SG_ 498 EVSE_Service2_Certificate 0;
BA_ "GenSigTimeoutTime_VDCM" SG_ 498 EVSE_Service2_Certificate 0;
BA_ "GenSigTimeoutTime_BPCM" SG_ 498 EVSE_OfferedPaymentEIM 0;
BA_ "GenSigTimeoutTime_IDCM" SG_ 498 EVSE_OfferedPaymentEIM 0;
BA_ "GenSigTimeoutTime_SGW" SG_ 498 EVSE_OfferedPaymentEIM 0;
BA_ "GenSigTimeoutTime_HCP" SG_ 498 EVSE_OfferedPaymentEIM 0;
BA_ "GenSigTimeoutTime_PPIM" SG_ 498 EVSE_OfferedPaymentEIM 0;
BA_ "GenSigTimeoutTime_APM2" SG_ 498 EVSE_OfferedPaymentEIM 0;
BA_ "GenSigTimeoutTime_VDCM" SG_ 498 EVSE_OfferedPaymentEIM 0;
BA_ "GenSigTimeoutTime_HCP" SG_ 498 V2H_HVCMS_EVSEPresentCurrent 0;
BA_ "GenSigTimeoutTime_PPIM" SG_ 498 V2H_HVCMS_EVSEPresentCurrent 0;
BA_ "GenSigTimeoutTime_APM2" SG_ 498 V2H_HVCMS_EVSEPresentCurrent 0;
BA_ "GenSigStartValue" SG_ 498 V2H_HVCMS_EVSEPresentCurrent 500;
BA_ "GenSigTimeoutTime_BPCM" SG_ 498 V2H_HVCMS_EVSEPresentCurrent 0;
BA_ "GenSigTimeoutTime_IDCM" SG_ 498 V2H_HVCMS_EVSEPresentCurrent 0;
BA_ "GenSigTimeoutTime_SGW" SG_ 498 V2H_HVCMS_EVSEPresentCurrent 0;
BA_ "GenSigTimeoutTime_HCP" SG_ 498 MC_OBCM_VDCM 0;
BA_ "GenSigTimeoutTime_PPIM" SG_ 498 MC_OBCM_VDCM 0;
BA_ "GenSigTimeoutTime_APM2" SG_ 498 MC_OBCM_VDCM 0;
BA_ "GenSigTimeoutTime_BPCM" SG_ 498 MC_OBCM_VDCM 0;
BA_ "GenSigTimeoutTime_IDCM" SG_ 498 MC_OBCM_VDCM 0;
BA_ "GenSigTimeoutTime_SGW" SG_ 498 MC_OBCM_VDCM 0;
BA_ "GenSigTimeoutTime_HCP" SG_ 498 EVSE_OfferedPaymentContract 0;
BA_ "GenSigTimeoutTime_PPIM" SG_ 498 EVSE_OfferedPaymentContract 0;
BA_ "GenSigTimeoutTime_APM2" SG_ 498 EVSE_OfferedPaymentContract 0;
BA_ "GenSigTimeoutTime_VDCM" SG_ 498 EVSE_OfferedPaymentContract 0;
BA_ "GenSigTimeoutTime_HCP" SG_ 498 EVSE_Notification 0;
BA_ "GenSigTimeoutTime_PPIM" SG_ 498 EVSE_Notification 0;
BA_ "GenSigTimeoutTime_APM2" SG_ 498 EVSE_Notification 0;
BA_ "GenSigTimeoutTime_VDCM" SG_ 498 EVSE_Notification 0;
BA_ "GenSigTimeoutTime_HCP" SG_ 498 ReceiptRequired 0;
BA_ "GenSigTimeoutTime_PPIM" SG_ 498 ReceiptRequired 0;
BA_ "GenSigTimeoutTime_APM2" SG_ 498 ReceiptRequired 0;
BA_ "GenSigTimeoutTime_VDCM" SG_ 498 ReceiptRequired 0;
BA_ "GenSigTimeoutTime_HCP" SG_ 498 V2X_EVSE_Service_6_V2G 0;
BA_ "GenSigTimeoutTime_PPIM" SG_ 498 V2X_EVSE_Service_6_V2G 0;
BA_ "GenSigTimeoutTime_APM2" SG_ 498 V2X_EVSE_Service_6_V2G 0;
BA_ "GenSigTimeoutTime_HCP" SG_ 498 V2X_EVSE_Service_5_V2H 0;
BA_ "GenSigTimeoutTime_PPIM" SG_ 498 V2X_EVSE_Service_5_V2H 0;
BA_ "GenSigTimeoutTime_APM2" SG_ 498 V2X_EVSE_Service_5_V2H 0;
BA_ "GenSigTimeoutTime_BPCM" SG_ 498 V2X_EVSE_Service_5_V2H 0;
BA_ "GenSigTimeoutTime_IDCM" SG_ 498 V2X_EVSE_Service_5_V2H 0;
BA_ "GenSigTimeoutTime_SGW" SG_ 498 V2X_EVSE_Service_5_V2H 0;
BA_ "GenSigTimeoutTime_BPCM" SG_ 498 V2X_EVSE_Service_6_V2G 0;
BA_ "GenSigTimeoutTime_IDCM" SG_ 498 V2X_EVSE_Service_6_V2G 0;
BA_ "GenSigTimeoutTime_SGW" SG_ 498 V2X_EVSE_Service_6_V2G 0;
BA_ "GenSigTimeoutTime_BPCM" SG_ 498 ReceiptRequired 0;
BA_ "GenSigTimeoutTime_IDCM" SG_ 498 ReceiptRequired 0;
BA_ "GenSigTimeoutTime_SGW" SG_ 498 ReceiptRequired 0;
BA_ "GenSigTimeoutTime_BPCM" SG_ 498 EVSE_Notification 0;
BA_ "GenSigTimeoutTime_IDCM" SG_ 498 EVSE_Notification 0;
BA_ "GenSigTimeoutTime_SGW" SG_ 498 EVSE_Notification 0;
BA_ "GenSigTimeoutTime_BPCM" SG_ 498 EVSE_OfferedPaymentContract 0;
BA_ "GenSigTimeoutTime_IDCM" SG_ 498 EVSE_OfferedPaymentContract 0;
BA_ "GenSigTimeoutTime_SGW" SG_ 498 EVSE_OfferedPaymentContract 0;
BA_ "GenSigTimeoutTime_BPCM" SG_ 498 CRC_OBCM_VDCM 0;
BA_ "GenSigTimeoutTime_IDCM" SG_ 498 CRC_OBCM_VDCM 0;
BA_ "GenSigTimeoutTime_SGW" SG_ 498 CRC_OBCM_VDCM 0;
BA_ "GenSigTimeoutTime_BPCM" SG_ 498 EVSE_Supported_DIN 0;
BA_ "GenSigTimeoutTime_IDCM" SG_ 498 EVSE_Supported_DIN 0;
BA_ "GenSigTimeoutTime_SGW" SG_ 498 EVSE_Supported_DIN 0;
BA_ "GenSigTimeoutTime_BPCM" SG_ 498 EVSE_Supported_ISO1 0;
BA_ "GenSigTimeoutTime_IDCM" SG_ 498 EVSE_Supported_ISO1 0;
BA_ "GenSigTimeoutTime_SGW" SG_ 498 EVSE_Supported_ISO1 0;
BA_ "GenSigTimeoutTime_HCP" SG_ 502 V2X_HVCMS_SlctdEnergyTransfType 0;
BA_ "GenSigTimeoutTime_PPIM" SG_ 502 V2X_HVCMS_SlctdEnergyTransfType 0;
BA_ "GenSigTimeoutTime_APM2" SG_ 502 V2X_HVCMS_SlctdEnergyTransfType 0;
BA_ "GenSigTimeoutTime_BPCM" SG_ 502 V2X_HVCMS_SlctdEnergyTransfType 0;
BA_ "GenSigTimeoutTime_EVCU2" SG_ 502 V2X_HVCMS_SlctdEnergyTransfType 0;
BA_ "GenSigTimeoutTime_SGW" SG_ 502 V2X_HVCMS_SlctdEnergyTransfType 0;
BA_ "GenSigTimeoutTime_EVCU2" SG_ 1852 HVBatCellVoltage_Cell194 0;
BA_ "GenSigTimeoutTime_IDCM" SG_ 1852 HVBatCellVoltage_Cell194 0;
BA_ "GenSigTimeoutTime_SGW" SG_ 1852 HVBatCellVoltage_Cell194 0;
BA_ "GenSigTimeoutTime_APM2" SG_ 1852 HVBatCellVoltage_Cell193 0;
BA_ "GenSigTimeoutTime_BPCM" SG_ 1852 HVBatCellVoltage_Cell193 0;
BA_ "GenSigTimeoutTime_EVCU2" SG_ 1852 HVBatCellVoltage_Cell193 0;
BA_ "GenSigTimeoutTime_IDCM" SG_ 1852 HVBatCellVoltage_Cell193 0;
BA_ "GenSigTimeoutTime_SGW" SG_ 1852 HVBatCellVoltage_Cell193 0;
BA_ "GenSigTimeoutTime_APM2" SG_ 1852 HVBatCellVoltage_Cell215 0;
BA_ "GenSigTimeoutTime_BPCM" SG_ 1852 HVBatCellVoltage_Cell215 0;
BA_ "GenSigTimeoutTime_EVCU2" SG_ 1852 HVBatCellVoltage_Cell215 0;
BA_ "GenSigTimeoutTime_IDCM" SG_ 1852 HVBatCellVoltage_Cell215 0;
BA_ "GenSigTimeoutTime_SGW" SG_ 1852 HVBatCellVoltage_Cell215 0;
BA_ "GenSigTimeoutTime_APM2" SG_ 1852 HVBatCellVoltage_Cell214 0;
BA_ "GenSigTimeoutTime_BPCM" SG_ 1852 HVBatCellVoltage_Cell214 0;
BA_ "GenSigTimeoutTime_EVCU2" SG_ 1852 HVBatCellVoltage_Cell214 0;
BA_ "GenSigTimeoutTime_IDCM" SG_ 1852 HVBatCellVoltage_Cell214 0;
BA_ "GenSigTimeoutTime_SGW" SG_ 1852 HVBatCellVoltage_Cell214 0;
BA_ "GenSigTimeoutTime_EVCU2" SG_ 1852 HVBatCellVoltage_Cell213 0;
BA_ "GenSigTimeoutTime_IDCM" SG_ 1852 HVBatCellVoltage_Cell213 0;
BA_ "GenSigTimeoutTime_SGW" SG_ 1852 HVBatCellVoltage_Cell213 0;
BA_ "GenSigTimeoutTime_APM2" SG_ 1852 HVBatCellVoltage_Cell216 0;
BA_ "GenSigTimeoutTime_BPCM" SG_ 1852 HVBatCellVoltage_Cell216 0;
BA_ "GenSigTimeoutTime_EVCU2" SG_ 1852 HVBatCellVoltage_Cell216 0;
BA_ "GenSigTimeoutTime_IDCM" SG_ 1852 HVBatCellVoltage_Cell216 0;
BA_ "GenSigTimeoutTime_APM2" SG_ 1852 HVBatCellVoltage_Cell192 0;
BA_ "GenSigTimeoutTime_BPCM" SG_ 1852 HVBatCellVoltage_Cell192 0;
BA_ "GenSigTimeoutTime_EVCU2" SG_ 1852 HVBatCellVoltage_Cell192 0;
BA_ "GenSigTimeoutTime_IDCM" SG_ 1852 HVBatCellVoltage_Cell192 0;
BA_ "GenSigTimeoutTime_SGW" SG_ 1852 HVBatCellVoltage_Cell192 0;
BA_ "GenSigTimeoutTime_APM2" SG_ 1852 HVBatCellVoltage_Cell191 0;
BA_ "GenSigTimeoutTime_BPCM" SG_ 1852 HVBatCellVoltage_Cell191 0;
BA_ "GenSigTimeoutTime_EVCU2" SG_ 1852 HVBatCellVoltage_Cell191 0;
BA_ "GenSigTimeoutTime_IDCM" SG_ 1852 HVBatCellVoltage_Cell191 0;
BA_ "GenSigTimeoutTime_SGW" SG_ 1852 HVBatCellVoltage_Cell191 0;
BA_ "GenSigTimeoutTime_APM2" SG_ 1852 HVBatCellVoltage_Cell190 0;
BA_ "GenSigTimeoutTime_BPCM" SG_ 1852 HVBatCellVoltage_Cell190 0;
BA_ "GenSigTimeoutTime_EVCU2" SG_ 1852 HVBatCellVoltage_Cell190 0;
BA_ "GenSigTimeoutTime_IDCM" SG_ 1852 HVBatCellVoltage_Cell190 0;
BA_ "GenSigTimeoutTime_SGW" SG_ 1852 HVBatCellVoltage_Cell190 0;
BA_ "GenSigTimeoutTime_HCP" SG_ 250 APM_TempColdPlate 0;
BA_ "GenSigTimeoutTime_PPIM" SG_ 250 APM_TempColdPlate 0;
BA_ "GenSigTimeoutTime_APM2" SG_ 250 APM_TempColdPlate 0;
BA_ "GenSigTimeoutTime_VDCM" SG_ 250 APM_TempColdPlate 0;
BA_ "GenSigTimeoutTime_HCP" SG_ 250 MessageCounter_APM_VDCM 0;
BA_ "GenSigTimeoutTime_PPIM" SG_ 250 MessageCounter_APM_VDCM 0;
BA_ "GenSigTimeoutTime_APM2" SG_ 250 MessageCounter_APM_VDCM 0;
BA_ "GenSigTimeoutTime_VDCM" SG_ 250 MessageCounter_APM_VDCM 0;
BA_ "GenSigTimeoutTime_BPCM" SG_ 250 MessageCounter_APM_VDCM 0;
BA_ "GenSigTimeoutTime_IDCM" SG_ 250 MessageCounter_APM_VDCM 0;
BA_ "GenSigTimeoutTime_SGW" SG_ 250 MessageCounter_APM_VDCM 0;
BA_ "GenSigTimeoutTime_HCP" SG_ 250 APM_DeratingPower 0;
BA_ "GenSigTimeoutTime_PPIM" SG_ 250 APM_DeratingPower 0;
BA_ "GenSigTimeoutTime_APM2" SG_ 250 APM_DeratingPower 0;
BA_ "GenSigTimeoutTime_VDCM" SG_ 250 APM_DeratingPower 0;
BA_ "GenSigTimeoutTime_BPCM" SG_ 250 APM_DeratingPower 0;
BA_ "GenSigTimeoutTime_IDCM" SG_ 250 APM_DeratingPower 0;
BA_ "GenSigTimeoutTime_SGW" SG_ 250 APM_DeratingPower 0;
BA_ "GenSigTimeoutTime_HCP" SG_ 250 CRC_APM_VDCM 0;
BA_ "GenSigTimeoutTime_PPIM" SG_ 250 CRC_APM_VDCM 0;
BA_ "GenSigTimeoutTime_APM2" SG_ 250 CRC_APM_VDCM 0;
BA_ "GenSigTimeoutTime_VDCM" SG_ 250 CRC_APM_VDCM 0;
BA_ "GenSigTimeoutTime_BPCM" SG_ 250 CRC_APM_VDCM 0;
BA_ "GenSigTimeoutTime_IDCM" SG_ 250 CRC_APM_VDCM 0;
BA_ "GenSigTimeoutTime_SGW" SG_ 250 CRC_APM_VDCM 0;
BA_ "GenSigStartValue" SG_ 250 APM_TempColdPlate 25;
BA_ "GenSigTimeoutTime_BPCM" SG_ 250 APM_TempColdPlate 0;
BA_ "GenSigTimeoutTime_IDCM" SG_ 250 APM_TempColdPlate 0;
BA_ "GenSigTimeoutTime_SGW" SG_ 250 APM_TempColdPlate 0;
BA_ "GenSigTimeoutTime_HCP" SG_ 250 APM_PowerLimitMode 0;
BA_ "GenSigTimeoutTime_PPIM" SG_ 250 APM_PowerLimitMode 0;
BA_ "GenSigTimeoutTime_APM2" SG_ 250 APM_PowerLimitMode 0;
BA_ "GenSigTimeoutTime_VDCM" SG_ 250 APM_PowerLimitMode 0;
BA_ "GenSigTimeoutTime_BPCM" SG_ 250 APM_PowerLimitMode 0;
BA_ "GenSigTimeoutTime_IDCM" SG_ 250 APM_PowerLimitMode 0;
BA_ "GenSigTimeoutTime_SGW" SG_ 250 APM_PowerLimitMode 0;
BA_ "GenSigTimeoutTime_HCP" SG_ 250 APM_UtilPctOfDCDC 0;
BA_ "GenSigTimeoutTime_PPIM" SG_ 250 APM_UtilPctOfDCDC 0;
BA_ "GenSigTimeoutTime_APM2" SG_ 250 APM_UtilPctOfDCDC 0;
BA_ "GenSigTimeoutTime_VDCM" SG_ 250 APM_UtilPctOfDCDC 0;
BA_ "GenSigTimeoutTime_BPCM" SG_ 250 APM_UtilPctOfDCDC 0;
BA_ "GenSigTimeoutTime_IDCM" SG_ 250 APM_UtilPctOfDCDC 0;
BA_ "GenSigTimeoutTime_SGW" SG_ 250 APM_UtilPctOfDCDC 0;
BA_ "GenSigTimeoutTime_HCP" SG_ 250 APM_HvVsetPFdbk 0;
BA_ "GenSigTimeoutTime_PPIM" SG_ 250 APM_HvVsetPFdbk 0;
BA_ "GenSigTimeoutTime_APM2" SG_ 250 APM_HvVsetPFdbk 0;
BA_ "GenSigTimeoutTime_VDCM" SG_ 250 APM_HvVsetPFdbk 0;
BA_ "GenSigTimeoutTime_BPCM" SG_ 250 APM_HvVsetPFdbk 0;
BA_ "GenSigTimeoutTime_IDCM" SG_ 250 APM_HvVsetPFdbk 0;
BA_ "GenSigTimeoutTime_SGW" SG_ 250 APM_HvVsetPFdbk 0;
BA_ "GenSigTimeoutTime_HCP" SG_ 250 APM_IdcHvSetPFdbk 0;
BA_ "GenSigTimeoutTime_PPIM" SG_ 250 APM_IdcHvSetPFdbk 0;
BA_ "GenSigTimeoutTime_APM2" SG_ 250 APM_IdcHvSetPFdbk 0;
BA_ "GenSigTimeoutTime_VDCM" SG_ 250 APM_IdcHvSetPFdbk 0;
BA_ "GenSigStartValue" SG_ 250 APM_IdcHvSetPFdbk 1021;
BA_ "GenSigTimeoutTime_BPCM" SG_ 250 APM_IdcHvSetPFdbk 0;
BA_ "GenSigTimeoutTime_IDCM" SG_ 250 APM_IdcHvSetPFdbk 0;
BA_ "GenSigTimeoutTime_SGW" SG_ 250 APM_IdcHvSetPFdbk 0;
BA_ "GenSigTimeoutTime_HCP" SG_ 250 APM_InputPower 0;
BA_ "GenSigTimeoutTime_PPIM" SG_ 250 APM_InputPower 0;
BA_ "GenSigTimeoutTime_APM2" SG_ 250 APM_InputPower 0;
BA_ "GenSigTimeoutTime_VDCM" SG_ 250 APM_InputPower 0;
BA_ "GenSigTimeoutTime_BPCM" SG_ 250 APM_InputPower 0;
BA_ "GenSigTimeoutTime_IDCM" SG_ 250 APM_InputPower 0;
BA_ "GenSigTimeoutTime_SGW" SG_ 250 APM_InputPower 0;
BA_ "GenSigTimeoutTime_HCP" SG_ 250 APM_OutputPower 0;
BA_ "GenSigTimeoutTime_PPIM" SG_ 250 APM_OutputPower 0;
BA_ "GenSigTimeoutTime_APM2" SG_ 250 APM_OutputPower 0;
BA_ "GenSigTimeoutTime_VDCM" SG_ 250 APM_OutputPower 0;
BA_ "GenSigTimeoutTime_BPCM" SG_ 250 APM_OutputPower 0;
BA_ "GenSigTimeoutTime_IDCM" SG_ 250 APM_OutputPower 0;
BA_ "GenSigTimeoutTime_SGW" SG_ 250 APM_OutputPower 0;
BA_ "GenSigTimeoutTime_HCP" SG_ 250 APM_CtrlSts_Fbk 0;
BA_ "GenSigTimeoutTime_PPIM" SG_ 250 APM_CtrlSts_Fbk 0;
BA_ "GenSigTimeoutTime_APM2" SG_ 250 APM_CtrlSts_Fbk 0;
BA_ "GenSigTimeoutTime_VDCM" SG_ 250 APM_CtrlSts_Fbk 0;
BA_ "GenSigTimeoutTime_BPCM" SG_ 250 APM_CtrlSts_Fbk 0;
BA_ "GenSigTimeoutTime_IDCM" SG_ 250 APM_CtrlSts_Fbk 0;
BA_ "GenSigTimeoutTime_SGW" SG_ 250 APM_CtrlSts_Fbk 0;
BA_ "GenSigTimeoutTime_HCP" SG_ 250 APM_CurrentLimitMode 0;
BA_ "GenSigTimeoutTime_PPIM" SG_ 250 APM_CurrentLimitMode 0;
BA_ "GenSigTimeoutTime_APM2" SG_ 250 APM_CurrentLimitMode 0;
BA_ "GenSigTimeoutTime_VDCM" SG_ 250 APM_CurrentLimitMode 0;
BA_ "GenSigTimeoutTime_BPCM" SG_ 250 APM_CurrentLimitMode 0;
BA_ "GenSigTimeoutTime_IDCM" SG_ 250 APM_CurrentLimitMode 0;
BA_ "GenSigTimeoutTime_SGW" SG_ 250 APM_CurrentLimitMode 0;
BA_ "GenSigTimeoutTime_HCP" SG_ 250 APM_DeratingModeStatus 0;
BA_ "GenSigTimeoutTime_PPIM" SG_ 250 APM_DeratingModeStatus 0;
BA_ "GenSigTimeoutTime_APM2" SG_ 250 APM_DeratingModeStatus 0;
BA_ "GenSigTimeoutTime_VDCM" SG_ 250 APM_DeratingModeStatus 0;
BA_ "GenSigTimeoutTime_BPCM" SG_ 250 APM_DeratingModeStatus 0;
BA_ "GenSigTimeoutTime_IDCM" SG_ 250 APM_DeratingModeStatus 0;
BA_ "GenSigTimeoutTime_SGW" SG_ 250 APM_DeratingModeStatus 0;
BA_ "GenSigTimeoutTime_HCP" SG_ 250 APM_DeratingReason 0;
BA_ "GenSigTimeoutTime_PPIM" SG_ 250 APM_DeratingReason 0;
BA_ "GenSigTimeoutTime_APM2" SG_ 250 APM_DeratingReason 0;
BA_ "GenSigTimeoutTime_VDCM" SG_ 250 APM_DeratingReason 0;
BA_ "GenSigTimeoutTime_BPCM" SG_ 250 APM_DeratingReason 0;
BA_ "GenSigTimeoutTime_IDCM" SG_ 250 APM_DeratingReason 0;
BA_ "GenSigTimeoutTime_SGW" SG_ 250 APM_DeratingReason 0;
BA_ "GenSigTimeoutTime_HCP" SG_ 250 APM_EstPwrLoss 0;
BA_ "GenSigTimeoutTime_PPIM" SG_ 250 APM_EstPwrLoss 0;
BA_ "GenSigTimeoutTime_APM2" SG_ 250 APM_EstPwrLoss 0;
BA_ "GenSigTimeoutTime_VDCM" SG_ 250 APM_EstPwrLoss 0;
BA_ "GenSigTimeoutTime_BPCM" SG_ 250 APM_EstPwrLoss 0;
BA_ "GenSigTimeoutTime_IDCM" SG_ 250 APM_EstPwrLoss 0;
BA_ "GenSigTimeoutTime_SGW" SG_ 250 APM_EstPwrLoss 0;
BA_ "GenSigTimeoutTime_HCP" SG_ 250 APM_FailureReason 0;
BA_ "GenSigTimeoutTime_PPIM" SG_ 250 APM_FailureReason 0;
BA_ "GenSigTimeoutTime_APM2" SG_ 250 APM_FailureReason 0;
BA_ "GenSigTimeoutTime_VDCM" SG_ 250 APM_FailureReason 0;
BA_ "GenSigTimeoutTime_BPCM" SG_ 250 APM_FailureReason 0;
BA_ "GenSigTimeoutTime_IDCM" SG_ 250 APM_FailureReason 0;
BA_ "GenSigTimeoutTime_SGW" SG_ 250 APM_FailureReason 0;
BA_ "GenSigTimeoutTime_HCP" SG_ 250 APM_FailureType 0;
BA_ "GenSigTimeoutTime_PPIM" SG_ 250 APM_FailureType 0;
BA_ "GenSigTimeoutTime_APM2" SG_ 250 APM_FailureType 0;
BA_ "GenSigTimeoutTime_VDCM" SG_ 250 APM_FailureType 0;
BA_ "GenSigTimeoutTime_BPCM" SG_ 250 APM_FailureType 0;
BA_ "GenSigTimeoutTime_IDCM" SG_ 250 APM_FailureType 0;
BA_ "GenSigTimeoutTime_SGW" SG_ 250 APM_FailureType 0;
BA_ "GenSigTimeoutTime_HCP" SG_ 250 APM_HvOverVStatus 0;
BA_ "GenSigTimeoutTime_PPIM" SG_ 250 APM_HvOverVStatus 0;
BA_ "GenSigTimeoutTime_APM2" SG_ 250 APM_HvOverVStatus 0;
BA_ "GenSigTimeoutTime_VDCM" SG_ 250 APM_HvOverVStatus 0;
BA_ "GenSigTimeoutTime_BPCM" SG_ 250 APM_HvOverVStatus 0;
BA_ "GenSigTimeoutTime_IDCM" SG_ 250 APM_HvOverVStatus 0;
BA_ "GenSigTimeoutTime_SGW" SG_ 250 APM_HvOverVStatus 0;
BA_ "GenSigTimeoutTime_BPCM" SG_ 250 APM_Water_Temp 0;
BA_ "GenSigTimeoutTime_IDCM" SG_ 250 APM_Water_Temp 0;
BA_ "GenSigTimeoutTime_SGW" SG_ 250 APM_Water_Temp 0;
BA_ "GenSigTimeoutTime_HCP" SG_ 250 APM_Water_Temp 0;
BA_ "GenSigTimeoutTime_PPIM" SG_ 250 APM_Water_Temp 0;
BA_ "GenSigTimeoutTime_APM2" SG_ 250 APM_Water_Temp 0;
BA_ "GenSigTimeoutTime_VDCM" SG_ 250 APM_Water_Temp 0;
BA_ "GenSigTimeoutTime_HCP" SG_ 250 APM_LV_V_Fbk 0;
BA_ "GenSigTimeoutTime_PPIM" SG_ 250 APM_LV_V_Fbk 0;
BA_ "GenSigTimeoutTime_APM2" SG_ 250 APM_LV_V_Fbk 0;
BA_ "GenSigTimeoutTime_VDCM" SG_ 250 APM_LV_V_Fbk 0;
BA_ "GenSigTimeoutTime_BPCM" SG_ 250 APM_LV_V_Fbk 0;
BA_ "GenSigTimeoutTime_IDCM" SG_ 250 APM_LV_V_Fbk 0;
BA_ "GenSigTimeoutTime_SGW" SG_ 250 APM_LV_V_Fbk 0;
BA_ "GenSigTimeoutTime_HCP" SG_ 250 APM_PSFB_Temp1 0;
BA_ "GenSigTimeoutTime_PPIM" SG_ 250 APM_PSFB_Temp1 0;
BA_ "GenSigTimeoutTime_APM2" SG_ 250 APM_PSFB_Temp1 0;
BA_ "GenSigTimeoutTime_VDCM" SG_ 250 APM_PSFB_Temp1 0;
BA_ "GenSigTimeoutTime_BPCM" SG_ 250 APM_PSFB_Temp1 0;
BA_ "GenSigTimeoutTime_IDCM" SG_ 250 APM_PSFB_Temp1 0;
BA_ "GenSigTimeoutTime_SGW" SG_ 250 APM_PSFB_Temp1 0;
BA_ "GenSigTimeoutTime_BPCM" SG_ 250 APM_PSFB_Temp2 0;
BA_ "GenSigTimeoutTime_IDCM" SG_ 250 APM_PSFB_Temp2 0;
BA_ "GenSigTimeoutTime_SGW" SG_ 250 APM_PSFB_Temp2 0;
BA_ "GenSigTimeoutTime_HCP" SG_ 250 APM_PSFB_Temp2 0;
BA_ "GenSigTimeoutTime_PPIM" SG_ 250 APM_PSFB_Temp2 0;
BA_ "GenSigTimeoutTime_APM2" SG_ 250 APM_PSFB_Temp2 0;
BA_ "GenSigTimeoutTime_VDCM" SG_ 250 APM_PSFB_Temp2 0;
BA_ "GenSigTimeoutTime_BPCM" SG_ 250 APM_RecoveryAction 0;
BA_ "GenSigTimeoutTime_IDCM" SG_ 250 APM_RecoveryAction 0;
BA_ "GenSigTimeoutTime_SGW" SG_ 250 APM_RecoveryAction 0;
BA_ "GenSigTimeoutTime_HCP" SG_ 250 APM_RecoveryAction 0;
BA_ "GenSigTimeoutTime_PPIM" SG_ 250 APM_RecoveryAction 0;
BA_ "GenSigTimeoutTime_APM2" SG_ 250 APM_RecoveryAction 0;
BA_ "GenSigTimeoutTime_VDCM" SG_ 250 APM_RecoveryAction 0;
BA_ "GenSigTimeoutTime_HCP" SG_ 250 APM_Buck_Temp 0;
BA_ "GenSigTimeoutTime_PPIM" SG_ 250 APM_Buck_Temp 0;
BA_ "GenSigTimeoutTime_APM2" SG_ 250 APM_Buck_Temp 0;
BA_ "GenSigTimeoutTime_VDCM" SG_ 250 APM_Buck_Temp 0;
BA_ "GenSigTimeoutTime_BPCM" SG_ 250 APM_Buck_Temp 0;
BA_ "GenSigTimeoutTime_IDCM" SG_ 250 APM_Buck_Temp 0;
BA_ "GenSigTimeoutTime_SGW" SG_ 250 APM_Buck_Temp 0;
BA_ "GenSigTimeoutTime_HCP" SG_ 250 APM_HV_I_Fbk 0;
BA_ "GenSigTimeoutTime_PPIM" SG_ 250 APM_HV_I_Fbk 0;
BA_ "GenSigTimeoutTime_APM2" SG_ 250 APM_HV_I_Fbk 0;
BA_ "GenSigTimeoutTime_VDCM" SG_ 250 APM_HV_I_Fbk 0;
BA_ "GenSigTimeoutTime_BPCM" SG_ 250 APM_HV_I_Fbk 0;
BA_ "GenSigTimeoutTime_IDCM" SG_ 250 APM_HV_I_Fbk 0;
BA_ "GenSigTimeoutTime_SGW" SG_ 250 APM_HV_I_Fbk 0;
BA_ "GenSigTimeoutTime_HCP" SG_ 250 APM_HV_V_Fbk 0;
BA_ "GenSigTimeoutTime_PPIM" SG_ 250 APM_HV_V_Fbk 0;
BA_ "GenSigTimeoutTime_APM2" SG_ 250 APM_HV_V_Fbk 0;
BA_ "GenSigTimeoutTime_VDCM" SG_ 250 APM_HV_V_Fbk 0;
BA_ "GenSigTimeoutTime_BPCM" SG_ 250 APM_HV_V_Fbk 0;
BA_ "GenSigTimeoutTime_IDCM" SG_ 250 APM_HV_V_Fbk 0;
BA_ "GenSigTimeoutTime_SGW" SG_ 250 APM_HV_V_Fbk 0;
BA_ "GenSigTimeoutTime_HCP" SG_ 250 APM_LV_I_Fbk 0;
BA_ "GenSigTimeoutTime_PPIM" SG_ 250 APM_LV_I_Fbk 0;
BA_ "GenSigTimeoutTime_APM2" SG_ 250 APM_LV_I_Fbk 0;
BA_ "GenSigTimeoutTime_VDCM" SG_ 250 APM_LV_I_Fbk 0;
BA_ "GenSigTimeoutTime_BPCM" SG_ 250 APM_LV_I_Fbk 0;
BA_ "GenSigTimeoutTime_IDCM" SG_ 250 APM_LV_I_Fbk 0;
BA_ "GenSigTimeoutTime_SGW" SG_ 250 APM_LV_I_Fbk 0;
BA_ "GenSigTimeoutTime_APM2" SG_ 500 BMS_Cell_Volt_Max_Vldty 0;
BA_ "GenSigTimeoutTime_BPCM" SG_ 500 BMS_Cell_Volt_Max_Vldty 0;
BA_ "GenSigTimeoutTime_EVCU2" SG_ 500 BMS_Cell_Volt_Max_Vldty 0;
BA_ "GenSigTimeoutTime_IDCM" SG_ 500 BMS_Cell_Volt_Max_Vldty 0;
BA_ "GenSigTimeoutTime_APM2" SG_ 500 BMS_Cell_Volt_Min_Vldty 0;
BA_ "GenSigTimeoutTime_BPCM" SG_ 500 BMS_Cell_Volt_Min_Vldty 0;
BA_ "GenSigTimeoutTime_EVCU2" SG_ 500 BMS_Cell_Volt_Min_Vldty 0;
BA_ "GenSigTimeoutTime_IDCM" SG_ 500 BMS_Cell_Volt_Min_Vldty 0;
BA_ "GenSigTimeoutTime_APM2" SG_ 500 BMS_HV_NumCellMaxTemp 0;
BA_ "GenSigTimeoutTime_VDCM" SG_ 500 BMS_HV_NumCellMaxTemp 0;
BA_ "GenSigTimeoutTime_APM2" SG_ 500 BMS_HV_NumCellMinTemp 0;
BA_ "GenSigTimeoutTime_VDCM" SG_ 500 BMS_HV_NumCellMinTemp 0;
BA_ "GenSigTimeoutTime_BPCM" SG_ 500 BMS_HV_NumCellMinTemp 0;
BA_ "GenSigTimeoutTime_EVCU2" SG_ 500 BMS_HV_NumCellMinTemp 0;
BA_ "GenSigTimeoutTime_IDCM" SG_ 500 BMS_HV_NumCellMinTemp 0;
BA_ "GenSigTimeoutTime_HCP" SG_ 500 BMS_HV_NumCellMaxVolt 0;
BA_ "GenSigTimeoutTime_PPIM" SG_ 500 BMS_HV_NumCellMaxVolt 0;
BA_ "GenSigTimeoutTime_APM2" SG_ 500 BMS_HV_NumCellMaxVolt 0;
BA_ "GenSigTimeoutTime_VDCM" SG_ 500 BMS_HV_NumCellMaxVolt 0;
BA_ "GenSigTimeoutTime_BPCM" SG_ 500 BMS_HV_NumCellMaxVolt 0;
BA_ "GenSigTimeoutTime_EVCU2" SG_ 500 BMS_HV_NumCellMaxVolt 0;
BA_ "GenSigTimeoutTime_IDCM" SG_ 500 BMS_HV_NumCellMaxVolt 0;
BA_ "GenSigTimeoutTime_APM2" SG_ 500 BMS_HV_NumCellMinVolt 0;
BA_ "GenSigTimeoutTime_BPCM" SG_ 500 BMS_HV_NumCellMinVolt 0;
BA_ "GenSigTimeoutTime_EVCU2" SG_ 500 BMS_HV_NumCellMinVolt 0;
BA_ "GenSigTimeoutTime_IDCM" SG_ 500 BMS_HV_NumCellMinVolt 0;
BA_ "GenSigTimeoutTime_APM2" SG_ 244 BMS_HV_Battery_GFD_Sts 0;
BA_ "GenSigTimeoutTime_VDCM" SG_ 244 BMS_HV_Battery_GFD_Sts 0;
BA_ "GenSigTimeoutTime_BPCM" SG_ 244 BMS_HV_Battery_GFD_Sts 0;
BA_ "GenSigTimeoutTime_EVCU2" SG_ 244 BMS_HV_Battery_GFD_Sts 0;
BA_ "GenSigTimeoutTime_IDCM" SG_ 244 BMS_HV_Battery_GFD_Sts 0;
BA_ "GenSigTimeoutTime_BPCM" SG_ 500 BMS_HV_NumCellMaxTemp 0;
BA_ "GenSigTimeoutTime_EVCU2" SG_ 500 BMS_HV_NumCellMaxTemp 0;
BA_ "GenSigTimeoutTime_IDCM" SG_ 500 BMS_HV_NumCellMaxTemp 0;
BA_ "GenSigTimeoutTime_APM2" SG_ 500 BMS_Cell_Volt_Min 0;
BA_ "GenSigTimeoutTime_VDCM" SG_ 500 BMS_Cell_Volt_Min 0;
BA_ "GenSigTimeoutTime_BPCM" SG_ 500 BMS_Cell_Volt_Min 0;
BA_ "GenSigTimeoutTime_EVCU2" SG_ 500 BMS_Cell_Volt_Min 0;
BA_ "GenSigTimeoutTime_IDCM" SG_ 500 BMS_Cell_Volt_Min 0;
BA_ "GenSigTimeoutTime_APM2" SG_ 500 BMS_Cell_Volt_Max 0;
BA_ "GenSigTimeoutTime_VDCM" SG_ 500 BMS_Cell_Volt_Max 0;
BA_ "GenSigTimeoutTime_BPCM" SG_ 500 BMS_Cell_Volt_Max 0;
BA_ "GenSigTimeoutTime_EVCU2" SG_ 500 BMS_Cell_Volt_Max 0;
BA_ "GenSigTimeoutTime_IDCM" SG_ 500 BMS_Cell_Volt_Max 0;
BA_ "GenSigTimeoutTime_APM2" SG_ 244 BMS_HV_Trac_Main_Contac_Sts 0;
BA_ "GenSigTimeoutTime_BPCM" SG_ 244 BMS_HV_Trac_Main_Contac_Sts 0;
BA_ "GenSigTimeoutTime_EVCU2" SG_ 244 BMS_HV_Trac_Main_Contac_Sts 0;
BA_ "GenSigTimeoutTime_IDCM" SG_ 244 BMS_HV_Trac_Main_Contac_Sts 0;
BA_ "GenSigTimeoutTime_APM2" SG_ 244 BMS_HV_Trac_PreCha_Contac_Sts 0;
BA_ "GenSigTimeoutTime_BPCM" SG_ 244 BMS_HV_Trac_PreCha_Contac_Sts 0;
BA_ "GenSigTimeoutTime_EVCU2" SG_ 244 BMS_HV_Trac_PreCha_Contac_Sts 0;
BA_ "GenSigTimeoutTime_IDCM" SG_ 244 BMS_HV_Trac_PreCha_Contac_Sts 0;
BA_ "GenSigTimeoutTime_APM2" SG_ 244 BMS_HV_Capacity_Vldty 0;
BA_ "GenSigTimeoutTime_BPCM" SG_ 244 BMS_HV_Capacity_Vldty 0;
BA_ "GenSigTimeoutTime_EVCU2" SG_ 244 BMS_HV_Capacity_Vldty 0;
BA_ "GenSigTimeoutTime_IDCM" SG_ 244 BMS_HV_Capacity_Vldty 0;
BA_ "GenSigTimeoutTime_APM2" SG_ 244 BMS_HV_Char_Main_Contac_Sts 0;
BA_ "GenSigTimeoutTime_BPCM" SG_ 244 BMS_HV_Char_Main_Contac_Sts 0;
BA_ "GenSigTimeoutTime_EVCU2" SG_ 244 BMS_HV_Char_Main_Contac_Sts 0;
BA_ "GenSigTimeoutTime_IDCM" SG_ 244 BMS_HV_Char_Main_Contac_Sts 0;
BA_ "GenSigTimeoutTime_APM2" SG_ 244 BMS_HV_Char_PreCha_Contac_Sts 0;
BA_ "GenSigTimeoutTime_BPCM" SG_ 244 BMS_HV_Char_PreCha_Contac_Sts 0;
BA_ "GenSigTimeoutTime_EVCU2" SG_ 244 BMS_HV_Char_PreCha_Contac_Sts 0;
BA_ "GenSigTimeoutTime_IDCM" SG_ 244 BMS_HV_Char_PreCha_Contac_Sts 0;
BA_ "GenSigTimeoutTime_APM2" SG_ 244 BMS_HV_Current 0;
BA_ "GenSigTimeoutTime_VDCM" SG_ 244 BMS_HV_Current 0;
BA_ "GenSigTimeoutTime_BPCM" SG_ 244 BMS_HV_Current 0;
BA_ "GenSigTimeoutTime_EVCU2" SG_ 244 BMS_HV_Current 0;
BA_ "GenSigTimeoutTime_IDCM" SG_ 244 BMS_HV_Current 0;
BA_ "GenSigTimeoutTime_APM2" SG_ 244 BMS_HV_InternalVoltage 0;
BA_ "GenSigTimeoutTime_VDCM" SG_ 244 BMS_HV_InternalVoltage 0;
BA_ "GenSigTimeoutTime_BPCM" SG_ 244 BMS_HV_InternalVoltage 0;
BA_ "GenSigTimeoutTime_EVCU2" SG_ 244 BMS_HV_InternalVoltage 0;
BA_ "GenSigTimeoutTime_IDCM" SG_ 244 BMS_HV_InternalVoltage 0;
BA_ "GenSigTimeoutTime_APM2" SG_ 244 BMS_HV_SOC 0;
BA_ "GenSigTimeoutTime_BPCM" SG_ 244 BMS_HV_SOC 0;
BA_ "GenSigTimeoutTime_EVCU2" SG_ 244 BMS_HV_SOC 0;
BA_ "GenSigTimeoutTime_IDCM" SG_ 244 BMS_HV_SOC 0;
BA_ "GenSigTimeoutTime_APM2" SG_ 244 BMS_HV_SOH 0;
BA_ "GenSigTimeoutTime_BPCM" SG_ 244 BMS_HV_SOH 0;
BA_ "GenSigTimeoutTime_EVCU2" SG_ 244 BMS_HV_SOH 0;
BA_ "GenSigTimeoutTime_IDCM" SG_ 244 BMS_HV_SOH 0;
BA_ "GenSigTimeoutTime_APM2" SG_ 244 BMS_HV_SOH_Low 0;
BA_ "GenSigTimeoutTime_BPCM" SG_ 244 BMS_HV_SOH_Low 0;
BA_ "GenSigTimeoutTime_EVCU2" SG_ 244 BMS_HV_SOH_Low 0;
BA_ "GenSigTimeoutTime_IDCM" SG_ 244 BMS_HV_SOH_Low 0;
BA_ "GenSigTimeoutTime_HCP" SG_ 498 DC_Isolation_Disable_Cmd 0;
BA_ "GenSigTimeoutTime_PPIM" SG_ 498 DC_Isolation_Disable_Cmd 0;
BA_ "GenSigTimeoutTime_APM2" SG_ 498 DC_Isolation_Disable_Cmd 0;
BA_ "GenSigTimeoutTime_VDCM" SG_ 498 DC_Isolation_Disable_Cmd 0;
BA_ "GenSigTimeoutTime_HCP" SG_ 498 DC_TimeOut 0;
BA_ "GenSigTimeoutTime_PPIM" SG_ 498 DC_TimeOut 0;
BA_ "GenSigTimeoutTime_APM2" SG_ 498 DC_TimeOut 0;
BA_ "GenSigTimeoutTime_VDCM" SG_ 498 DC_TimeOut 0;
BA_ "GenSigTimeoutTime_HCP" SG_ 498 EVSE_Accepted_Protocol 0;
BA_ "GenSigTimeoutTime_PPIM" SG_ 498 EVSE_Accepted_Protocol 0;
BA_ "GenSigTimeoutTime_APM2" SG_ 498 EVSE_Accepted_Protocol 0;
BA_ "GenSigTimeoutTime_VDCM" SG_ 498 EVSE_Accepted_Protocol 0;
BA_ "GenSigTimeoutTime_HCP" SG_ 498 EVSE_IsolationSts 0;
BA_ "GenSigTimeoutTime_PPIM" SG_ 498 EVSE_IsolationSts 0;
BA_ "GenSigTimeoutTime_APM2" SG_ 498 EVSE_IsolationSts 0;
BA_ "GenSigTimeoutTime_VDCM" SG_ 498 EVSE_IsolationSts 0;
BA_ "GenSigTimeoutTime_HCP" SG_ 498 HVCMS_EnergyToBeDelivered 0;
BA_ "GenSigTimeoutTime_PPIM" SG_ 498 HVCMS_EnergyToBeDelivered 0;
BA_ "GenSigTimeoutTime_APM2" SG_ 498 HVCMS_EnergyToBeDelivered 0;
BA_ "GenSigTimeoutTime_VDCM" SG_ 498 HVCMS_EnergyToBeDelivered 0;
BA_ "GenSigTimeoutTime_HCP" SG_ 498 HVCMS_EVSEPresentCurrent 0;
BA_ "GenSigTimeoutTime_PPIM" SG_ 498 HVCMS_EVSEPresentCurrent 0;
BA_ "GenSigTimeoutTime_APM2" SG_ 498 HVCMS_EVSEPresentCurrent 0;
BA_ "GenSigTimeoutTime_APM2" SG_ 244 BPCM_Comm_Fail_CAN 0;
BA_ "GenSigTimeoutTime_BPCM" SG_ 244 BPCM_Comm_Fail_CAN 0;
BA_ "GenSigTimeoutTime_EVCU2" SG_ 244 BPCM_Comm_Fail_CAN 0;
BA_ "GenSigTimeoutTime_IDCM" SG_ 244 BPCM_Comm_Fail_CAN 0;
BA_ "GenSigTimeoutTime_APM2" SG_ 244 BMS_HV_Trac_Bus_Sts 0;
BA_ "GenSigTimeoutTime_BPCM" SG_ 244 BMS_HV_Trac_Bus_Sts 0;
BA_ "GenSigTimeoutTime_EVCU2" SG_ 244 BMS_HV_Trac_Bus_Sts 0;
BA_ "GenSigTimeoutTime_IDCM" SG_ 244 BMS_HV_Trac_Bus_Sts 0;
BA_ "GenSigTimeoutTime_HCP" SG_ 498 OBCM_PLCTypeSts 0;
BA_ "GenSigTimeoutTime_PPIM" SG_ 498 OBCM_PLCTypeSts 0;
BA_ "GenSigTimeoutTime_APM2" SG_ 498 OBCM_PLCTypeSts 0;
BA_ "GenSigTimeoutTime_VDCM" SG_ 498 OBCM_PLCTypeSts 0;
BA_ "GenSigTimeoutTime_HCP" SG_ 2564485652 N_PDU_18DAF214 0;
BA_ "GenSigTimeoutTime_PPIM" SG_ 2564485652 N_PDU_18DAF214 0;
BA_ "GenSigTimeoutTime_APM2" SG_ 2564485652 N_PDU_18DAF214 0;
BA_ "GenSigTimeoutTime_VDCM" SG_ 2564485652 N_PDU_18DAF214 0;
BA_ "GenSigTimeoutTime_BPCM" SG_ 2564485652 N_PDU_18DAF214 0;
BA_ "GenSigTimeoutTime_EVCU2" SG_ 2564485652 N_PDU_18DAF214 0;
BA_ "GenSigTimeoutTime_IDCM" SG_ 2564485652 N_PDU_18DAF214 0;
BA_ "GenSigTimeoutTime_SGW" SG_ 2564485652 N_PDU_18DAF214 0;
BA_ "GenSigTimeoutTime_HCP" SG_ 2564682260 N_PDU_18DDF214 0;
BA_ "GenSigTimeoutTime_PPIM" SG_ 2564682260 N_PDU_18DDF214 0;
BA_ "GenSigTimeoutTime_BPCM" SG_ 2564682260 N_PDU_18DDF214 0;
BA_ "GenSigTimeoutTime_EVCU2" SG_ 2564682260 N_PDU_18DDF214 0;
BA_ "GenSigTimeoutTime_IDCM" SG_ 2564682260 N_PDU_18DDF214 0;
BA_ "GenSigTimeoutTime_SGW" SG_ 2564682260 N_PDU_18DDF214 0;
BA_ "GenSigTimeoutTime_HCP" SG_ 2564485653 N_PDU_18DAF215 0;
BA_ "GenSigTimeoutTime_PPIM" SG_ 2564485653 N_PDU_18DAF215 0;
BA_ "GenSigTimeoutTime_APM2" SG_ 2564485653 N_PDU_18DAF215 0;
BA_ "GenSigTimeoutTime_VDCM" SG_ 2564485653 N_PDU_18DAF215 0;
BA_ "GenSigTimeoutTime_BPCM" SG_ 2564485653 N_PDU_18DAF215 0;
BA_ "GenSigTimeoutTime_EVCU2" SG_ 2564485653 N_PDU_18DAF215 0;
BA_ "GenSigTimeoutTime_IDCM" SG_ 2564485653 N_PDU_18DAF215 0;
BA_ "GenSigTimeoutTime_SGW" SG_ 2564485653 N_PDU_18DAF215 0;
BA_ "GenSigTimeoutTime_EVCU2" SG_ 2564682261 N_PDU_18DDF215 0;
BA_ "GenSigTimeoutTime_IDCM" SG_ 2564682261 N_PDU_18DDF215 0;
BA_ "GenSigTimeoutTime_SGW" SG_ 2564682261 N_PDU_18DDF215 0;
BA_ "GenSigTimeoutTime_HCP" SG_ 2564682261 N_PDU_18DDF215 0;
BA_ "GenSigTimeoutTime_PPIM" SG_ 2564682261 N_PDU_18DDF215 0;
BA_ "GenSigTimeoutTime_BPCM" SG_ 2564682261 N_PDU_18DDF215 0;
BA_ "GenSigTimeoutTime_APM2" SG_ 244 BMS_HV_AC_Char_Main_Contac_Sts 0;
BA_ "GenSigTimeoutTime_BPCM" SG_ 244 BMS_HV_AC_Char_Main_Contac_Sts 0;
BA_ "GenSigTimeoutTime_EVCU2" SG_ 244 BMS_HV_AC_Char_Main_Contac_Sts 0;
BA_ "GenSigTimeoutTime_IDCM" SG_ 244 BMS_HV_AC_Char_Main_Contac_Sts 0;
BA_ "GenSigTimeoutTime_APM2" SG_ 244 BMS_HV_SOH_Vldty 0;
BA_ "GenSigTimeoutTime_BPCM" SG_ 244 BMS_HV_SOH_Vldty 0;
BA_ "GenSigTimeoutTime_EVCU2" SG_ 244 BMS_HV_SOH_Vldty 0;
BA_ "GenSigTimeoutTime_IDCM" SG_ 244 BMS_HV_SOH_Vldty 0;
BA_ "GenSigTimeoutTime_APM2" SG_ 244 BMS_HV_Temperature_Avg 0;
BA_ "GenSigTimeoutTime_BPCM" SG_ 244 BMS_HV_Temperature_Avg 0;
BA_ "GenSigTimeoutTime_EVCU2" SG_ 244 BMS_HV_Temperature_Avg 0;
BA_ "GenSigTimeoutTime_IDCM" SG_ 244 BMS_HV_Temperature_Avg 0;
BA_ "GenSigTimeoutTime_APM2" SG_ 244 BMS_HV_Temperature_Max 0;
BA_ "GenSigTimeoutTime_VDCM" SG_ 244 BMS_HV_Temperature_Max 0;
BA_ "GenSigTimeoutTime_BPCM" SG_ 244 BMS_HV_Temperature_Max 0;
BA_ "GenSigTimeoutTime_EVCU2" SG_ 244 BMS_HV_Temperature_Max 0;
BA_ "GenSigTimeoutTime_IDCM" SG_ 244 BMS_HV_Temperature_Max 0;
BA_ "GenSigTimeoutTime_APM2" SG_ 244 BMS_HV_Temperature_Min 0;
BA_ "GenSigTimeoutTime_VDCM" SG_ 244 BMS_HV_Temperature_Min 0;
BA_ "GenSigTimeoutTime_BPCM" SG_ 244 BMS_HV_Temperature_Min 0;
BA_ "GenSigTimeoutTime_EVCU2" SG_ 244 BMS_HV_Temperature_Min 0;
BA_ "GenSigTimeoutTime_IDCM" SG_ 244 BMS_HV_Temperature_Min 0;
BA_ "GenSigTimeoutTime_HCP" SG_ 244 ImpactHardwireV 0;
BA_ "GenSigTimeoutTime_PPIM" SG_ 244 ImpactHardwireV 0;
BA_ "GenSigTimeoutTime_APM2" SG_ 244 ImpactHardwireV 0;
BA_ "GenSigTimeoutTime_VDCM" SG_ 244 ImpactHardwireV 0;
BA_ "GenSigTimeoutTime_BPCM" SG_ 244 ImpactHardwireV 0;
BA_ "GenSigTimeoutTime_IDCM" SG_ 244 ImpactHardwireV 0;
BA_ "GenSigTimeoutTime_SGW" SG_ 244 ImpactHardwireV 0;
BA_ "GenSigTimeoutTime_HCP" SG_ 244 ImpactHardwire 0;
BA_ "GenSigTimeoutTime_PPIM" SG_ 244 ImpactHardwire 0;
BA_ "GenSigTimeoutTime_APM2" SG_ 244 ImpactHardwire 0;
BA_ "GenSigTimeoutTime_VDCM" SG_ 244 ImpactHardwire 0;
BA_ "GenSigTimeoutTime_BPCM" SG_ 244 ImpactHardwire 0;
BA_ "GenSigTimeoutTime_IDCM" SG_ 244 ImpactHardwire 0;
BA_ "GenSigTimeoutTime_SGW" SG_ 244 ImpactHardwire 0;
BA_ "GenSigTimeoutTime_HCP" SG_ 2564429042 N_PDU_18DA14F2 0;
BA_ "GenSigTimeoutTime_PPIM" SG_ 2564429042 N_PDU_18DA14F2 0;
BA_ "GenSigTimeoutTime_APM2" SG_ 2564429042 N_PDU_18DA14F2 0;
BA_ "GenSigTimeoutTime_VDCM" SG_ 2564429042 N_PDU_18DA14F2 0;
BA_ "GenSigTimeoutTime_BPCM" SG_ 2564429042 N_PDU_18DA14F2 0;
BA_ "GenSigTimeoutTime_EVCU2" SG_ 2564429042 N_PDU_18DA14F2 0;
BA_ "GenSigTimeoutTime_IDCM" SG_ 2564429042 N_PDU_18DA14F2 0;
BA_ "GenSigTimeoutTime_SGW" SG_ 2564429042 N_PDU_18DA14F2 0;
BA_ "GenSigTimeoutTime_HCP" SG_ 2564429298 N_PDU_18DA15F2 0;
BA_ "GenSigTimeoutTime_PPIM" SG_ 2564429298 N_PDU_18DA15F2 0;
BA_ "GenSigTimeoutTime_APM2" SG_ 2564429298 N_PDU_18DA15F2 0;
BA_ "GenSigTimeoutTime_VDCM" SG_ 2564429298 N_PDU_18DA15F2 0;
BA_ "GenSigTimeoutTime_BPCM" SG_ 2564429298 N_PDU_18DA15F2 0;
BA_ "GenSigTimeoutTime_EVCU2" SG_ 2564429298 N_PDU_18DA15F2 0;
BA_ "GenSigTimeoutTime_IDCM" SG_ 2564429298 N_PDU_18DA15F2 0;
BA_ "GenSigTimeoutTime_SGW" SG_ 2564429298 N_PDU_18DA15F2 0;
BA_ "GenSigTimeoutTime_APM2" SG_ 244 BMS_HV_Capacity 0;
BA_ "GenSigTimeoutTime_BPCM" SG_ 244 BMS_HV_Capacity 0;
BA_ "GenSigTimeoutTime_EVCU2" SG_ 244 BMS_HV_Capacity 0;
BA_ "GenSigTimeoutTime_IDCM" SG_ 244 BMS_HV_Capacity 0;
BA_ "GenSigTimeoutTime_HCP" SG_ 498 HVCMS_TxMessageStat 0;
BA_ "GenSigTimeoutTime_PPIM" SG_ 498 HVCMS_TxMessageStat 0;
BA_ "GenSigTimeoutTime_APM2" SG_ 498 HVCMS_TxMessageStat 0;
BA_ "GenSigTimeoutTime_VDCM" SG_ 498 HVCMS_TxMessageStat 0;
BA_ "GenSigTimeoutTime_BPCM" SG_ 498 HVCMS_TxMessageStat 0;
BA_ "GenSigTimeoutTime_IDCM" SG_ 498 HVCMS_TxMessageStat 0;
BA_ "GenSigTimeoutTime_SGW" SG_ 498 HVCMS_TxMessageStat 0;
BA_ "GenSigTimeoutTime_HCP" SG_ 498 HVCMS_EVSEProcessing 0;
BA_ "GenSigTimeoutTime_PPIM" SG_ 498 HVCMS_EVSEProcessing 0;
BA_ "GenSigTimeoutTime_APM2" SG_ 498 HVCMS_EVSEProcessing 0;
BA_ "GenSigTimeoutTime_VDCM" SG_ 498 HVCMS_EVSEProcessing 0;
BA_ "GenSigTimeoutTime_BPCM" SG_ 498 HVCMS_EVSEProcessing 0;
BA_ "GenSigTimeoutTime_IDCM" SG_ 498 HVCMS_EVSEProcessing 0;
BA_ "GenSigTimeoutTime_SGW" SG_ 498 HVCMS_EVSEProcessing 0;
BA_ "GenSigTimeoutTime_HCP" SG_ 498 HVCMS_ResponseCode 0;
BA_ "GenSigTimeoutTime_PPIM" SG_ 498 HVCMS_ResponseCode 0;
BA_ "GenSigTimeoutTime_APM2" SG_ 498 HVCMS_ResponseCode 0;
BA_ "GenSigTimeoutTime_VDCM" SG_ 498 HVCMS_ResponseCode 0;
BA_ "GenSigTimeoutTime_BPCM" SG_ 498 HVCMS_ResponseCode 0;
BA_ "GenSigTimeoutTime_IDCM" SG_ 498 HVCMS_ResponseCode 0;
BA_ "GenSigTimeoutTime_SGW" SG_ 498 HVCMS_ResponseCode 0;
BA_ "GenSigTimeoutTime_HCP" SG_ 498 EVSE_FreeService 0;
BA_ "GenSigTimeoutTime_PPIM" SG_ 498 EVSE_FreeService 0;
BA_ "GenSigTimeoutTime_APM2" SG_ 498 EVSE_FreeService 0;
BA_ "GenSigTimeoutTime_VDCM" SG_ 498 EVSE_FreeService 0;
BA_ "GenSigTimeoutTime_BPCM" SG_ 498 EVSE_FreeService 0;
BA_ "GenSigTimeoutTime_IDCM" SG_ 498 EVSE_FreeService 0;
BA_ "GenSigTimeoutTime_SGW" SG_ 498 EVSE_FreeService 0;
BA_ "GenSigTimeoutTime_HCP" SG_ 498 TxMessageResponse 0;
BA_ "GenSigTimeoutTime_PPIM" SG_ 498 TxMessageResponse 0;
BA_ "GenSigTimeoutTime_APM2" SG_ 498 TxMessageResponse 0;
BA_ "GenSigTimeoutTime_VDCM" SG_ 498 TxMessageResponse 0;
BA_ "GenSigTimeoutTime_BPCM" SG_ 498 TxMessageResponse 0;
BA_ "GenSigTimeoutTime_IDCM" SG_ 498 TxMessageResponse 0;
BA_ "GenSigTimeoutTime_SGW" SG_ 498 TxMessageResponse 0;
BA_ "GenSigTimeoutTime_BPCM" SG_ 498 EVSE_ServiceId 0;
BA_ "GenSigTimeoutTime_IDCM" SG_ 498 EVSE_ServiceId 0;
BA_ "GenSigTimeoutTime_SGW" SG_ 498 EVSE_ServiceId 0;
BA_ "GenSigTimeoutTime_HCP" SG_ 498 EVSE_ServiceId 0;
BA_ "GenSigTimeoutTime_PPIM" SG_ 498 EVSE_ServiceId 0;
BA_ "GenSigTimeoutTime_APM2" SG_ 498 EVSE_ServiceId 0;
BA_ "GenSigTimeoutTime_VDCM" SG_ 498 EVSE_ServiceId 0;
BA_ "GenSigStartValue" SG_ 498 HVCMS_EVSEStatusCode 15;
BA_ "GenSigTimeoutTime_BPCM" SG_ 498 HVCMS_EVSEStatusCode 0;
BA_ "GenSigTimeoutTime_IDCM" SG_ 498 HVCMS_EVSEStatusCode 0;
BA_ "GenSigTimeoutTime_SGW" SG_ 498 HVCMS_EVSEStatusCode 0;
BA_ "GenSigTimeoutTime_HCP" SG_ 498 HVCMS_EVSEStatusCode 0;
BA_ "GenSigTimeoutTime_PPIM" SG_ 498 HVCMS_EVSEStatusCode 0;
BA_ "GenSigTimeoutTime_APM2" SG_ 498 HVCMS_EVSEStatusCode 0;
BA_ "GenSigTimeoutTime_VDCM" SG_ 498 HVCMS_EVSEStatusCode 0;
BA_ "GenSigTimeoutTime_SGW" SG_ 498 EVSE_OfferedPaymentOptn 0;
BA_ "GenSigTimeoutTime_HCP" SG_ 498 EVSE_OfferedPaymentOptn 0;
BA_ "GenSigTimeoutTime_PPIM" SG_ 498 EVSE_OfferedPaymentOptn 0;
BA_ "GenSigTimeoutTime_APM2" SG_ 498 EVSE_OfferedPaymentOptn 0;
BA_ "GenSigTimeoutTime_VDCM" SG_ 498 EVSE_OfferedPaymentOptn 0;
BA_ "GenSigTimeoutTime_BPCM" SG_ 498 EVSE_OfferedPaymentOptn 0;
BA_ "GenSigTimeoutTime_IDCM" SG_ 498 EVSE_OfferedPaymentOptn 0;
BA_ "GenSigTimeoutTime_BPCM" SG_ 498 EVSE_OfferedService 0;
BA_ "GenSigTimeoutTime_IDCM" SG_ 498 EVSE_OfferedService 0;
BA_ "GenSigTimeoutTime_SGW" SG_ 498 EVSE_OfferedService 0;
BA_ "GenSigTimeoutTime_HCP" SG_ 498 EVSE_OfferedService 0;
BA_ "GenSigTimeoutTime_PPIM" SG_ 498 EVSE_OfferedService 0;
BA_ "GenSigTimeoutTime_APM2" SG_ 498 EVSE_OfferedService 0;
BA_ "GenSigTimeoutTime_VDCM" SG_ 498 EVSE_OfferedService 0;
BA_ "GenSigTimeoutTime_HCP" SG_ 498 EVSE_OfferedEnergyTransferType 0;
BA_ "GenSigTimeoutTime_PPIM" SG_ 498 EVSE_OfferedEnergyTransferType 0;
BA_ "GenSigTimeoutTime_APM2" SG_ 498 EVSE_OfferedEnergyTransferType 0;
BA_ "GenSigTimeoutTime_VDCM" SG_ 498 EVSE_OfferedEnergyTransferType 0;
BA_ "GenSigTimeoutTime_BPCM" SG_ 498 EVSE_OfferedEnergyTransferType 0;
BA_ "GenSigTimeoutTime_IDCM" SG_ 498 EVSE_OfferedEnergyTransferType 0;
BA_ "GenSigTimeoutTime_SGW" SG_ 498 EVSE_OfferedEnergyTransferType 0;
BA_ "GenSigTimeoutTime_BPCM" SG_ 498 OBCM_PLCTypeSts 0;
BA_ "GenSigTimeoutTime_IDCM" SG_ 498 OBCM_PLCTypeSts 0;
BA_ "GenSigTimeoutTime_SGW" SG_ 498 OBCM_PLCTypeSts 0;
BA_ "GenSigTimeoutTime_HCP" SG_ 498 HVCMS_EVSEVoltageLimitAchieved 0;
BA_ "GenSigTimeoutTime_PPIM" SG_ 498 HVCMS_EVSEVoltageLimitAchieved 0;
BA_ "GenSigTimeoutTime_APM2" SG_ 498 HVCMS_EVSEVoltageLimitAchieved 0;
BA_ "GenSigTimeoutTime_VDCM" SG_ 498 HVCMS_EVSEVoltageLimitAchieved 0;
BA_ "GenSigStartValue" SG_ 498 HVCMS_EVSEVoltageLimitAchieved 2;
BA_ "GenSigTimeoutTime_BPCM" SG_ 498 HVCMS_EVSEVoltageLimitAchieved 0;
BA_ "GenSigTimeoutTime_IDCM" SG_ 498 HVCMS_EVSEVoltageLimitAchieved 0;
BA_ "GenSigTimeoutTime_SGW" SG_ 498 HVCMS_EVSEVoltageLimitAchieved 0;
BA_ "GenSigTimeoutTime_HCP" SG_ 498 HVCMS_EVSECurrentLimitAchieved 0;
BA_ "GenSigTimeoutTime_PPIM" SG_ 498 HVCMS_EVSECurrentLimitAchieved 0;
BA_ "GenSigTimeoutTime_APM2" SG_ 498 HVCMS_EVSECurrentLimitAchieved 0;
BA_ "GenSigTimeoutTime_VDCM" SG_ 498 HVCMS_EVSECurrentLimitAchieved 0;
BA_ "GenSigStartValue" SG_ 498 HVCMS_EVSECurrentLimitAchieved 2;
BA_ "GenSigTimeoutTime_BPCM" SG_ 498 HVCMS_EVSECurrentLimitAchieved 0;
BA_ "GenSigTimeoutTime_IDCM" SG_ 498 HVCMS_EVSECurrentLimitAchieved 0;
BA_ "GenSigTimeoutTime_SGW" SG_ 498 HVCMS_EVSECurrentLimitAchieved 0;
BA_ "GenSigTimeoutTime_HCP" SG_ 498 HVCMS_EVSEMaximumVoltageLimit 0;
BA_ "GenSigTimeoutTime_PPIM" SG_ 498 HVCMS_EVSEMaximumVoltageLimit 0;
BA_ "GenSigTimeoutTime_APM2" SG_ 498 HVCMS_EVSEMaximumVoltageLimit 0;
BA_ "GenSigTimeoutTime_VDCM" SG_ 498 HVCMS_EVSEMaximumVoltageLimit 0;
BA_ "GenSigTimeoutTime_BPCM" SG_ 498 HVCMS_EVSEMaximumVoltageLimit 0;
BA_ "GenSigTimeoutTime_IDCM" SG_ 498 HVCMS_EVSEMaximumVoltageLimit 0;
BA_ "GenSigTimeoutTime_SGW" SG_ 498 HVCMS_EVSEMaximumVoltageLimit 0;
BA_ "GenSigTimeoutTime_HCP" SG_ 498 HVCMS_EVSEMinimumVoltageLimit 0;
BA_ "GenSigTimeoutTime_PPIM" SG_ 498 HVCMS_EVSEMinimumVoltageLimit 0;
BA_ "GenSigTimeoutTime_APM2" SG_ 498 HVCMS_EVSEMinimumVoltageLimit 0;
BA_ "GenSigTimeoutTime_VDCM" SG_ 498 HVCMS_EVSEMinimumVoltageLimit 0;
BA_ "GenSigTimeoutTime_BPCM" SG_ 498 HVCMS_EVSEMinimumVoltageLimit 0;
BA_ "GenSigTimeoutTime_IDCM" SG_ 498 HVCMS_EVSEMinimumVoltageLimit 0;
BA_ "GenSigTimeoutTime_SGW" SG_ 498 HVCMS_EVSEMinimumVoltageLimit 0;
BA_ "GenSigTimeoutTime_HCP" SG_ 498 HVCMS_EVSEPowerLimitAchieved 0;
BA_ "GenSigTimeoutTime_PPIM" SG_ 498 HVCMS_EVSEPowerLimitAchieved 0;
BA_ "GenSigTimeoutTime_APM2" SG_ 498 HVCMS_EVSEPowerLimitAchieved 0;
BA_ "GenSigTimeoutTime_VDCM" SG_ 498 HVCMS_EVSEPowerLimitAchieved 0;
BA_ "GenSigStartValue" SG_ 498 HVCMS_EVSEPowerLimitAchieved 2;
BA_ "GenSigTimeoutTime_BPCM" SG_ 498 HVCMS_EVSEPowerLimitAchieved 0;
BA_ "GenSigTimeoutTime_IDCM" SG_ 498 HVCMS_EVSEPowerLimitAchieved 0;
BA_ "GenSigTimeoutTime_SGW" SG_ 498 HVCMS_EVSEPowerLimitAchieved 0;
BA_ "GenSigTimeoutTime_VDCM" SG_ 498 HVCMS_EVSEPresentCurrent 0;
BA_ "GenSigTimeoutTime_BPCM" SG_ 498 HVCMS_EVSEPresentCurrent 0;
BA_ "GenSigTimeoutTime_IDCM" SG_ 498 HVCMS_EVSEPresentCurrent 0;
BA_ "GenSigTimeoutTime_SGW" SG_ 498 HVCMS_EVSEPresentCurrent 0;
BA_ "GenSigTimeoutTime_BPCM" SG_ 498 HVCMS_EnergyToBeDelivered 0;
BA_ "GenSigTimeoutTime_IDCM" SG_ 498 HVCMS_EnergyToBeDelivered 0;
BA_ "GenSigTimeoutTime_SGW" SG_ 498 HVCMS_EnergyToBeDelivered 0;
BA_ "GenSigTimeoutTime_BPCM" SG_ 498 EVSE_IsolationSts 0;
BA_ "GenSigTimeoutTime_IDCM" SG_ 498 EVSE_IsolationSts 0;
BA_ "GenSigTimeoutTime_SGW" SG_ 498 EVSE_IsolationSts 0;
BA_ "GenSigTimeoutTime_BPCM" SG_ 498 EVSE_Accepted_Protocol 0;
BA_ "GenSigTimeoutTime_IDCM" SG_ 498 EVSE_Accepted_Protocol 0;
BA_ "GenSigTimeoutTime_SGW" SG_ 498 EVSE_Accepted_Protocol 0;
BA_ "GenSigTimeoutTime_BPCM" SG_ 498 DC_TimeOut 0;
BA_ "GenSigTimeoutTime_IDCM" SG_ 498 DC_TimeOut 0;
BA_ "GenSigTimeoutTime_SGW" SG_ 498 DC_TimeOut 0;
BA_ "GenSigTimeoutTime_BPCM" SG_ 498 DC_Isolation_Disable_Cmd 0;
BA_ "GenSigTimeoutTime_IDCM" SG_ 498 DC_Isolation_Disable_Cmd 0;
BA_ "GenSigTimeoutTime_SGW" SG_ 498 DC_Isolation_Disable_Cmd 0;
BA_ "GenSigTimeoutTime_HCP" SG_ 498 HVCMS_EVSECurrRegulationTol 0;
BA_ "GenSigTimeoutTime_PPIM" SG_ 498 HVCMS_EVSECurrRegulationTol 0;
BA_ "GenSigTimeoutTime_APM2" SG_ 498 HVCMS_EVSECurrRegulationTol 0;
BA_ "GenSigTimeoutTime_VDCM" SG_ 498 HVCMS_EVSECurrRegulationTol 0;
BA_ "GenSigTimeoutTime_HCP" SG_ 498 HVCMS_EVSEMaxCurrentLimit 0;
BA_ "GenSigTimeoutTime_PPIM" SG_ 498 HVCMS_EVSEMaxCurrentLimit 0;
BA_ "GenSigTimeoutTime_APM2" SG_ 498 HVCMS_EVSEMaxCurrentLimit 0;
BA_ "GenSigTimeoutTime_VDCM" SG_ 498 HVCMS_EVSEMaxCurrentLimit 0;
BA_ "GenSigTimeoutTime_HCP" SG_ 498 HVCMS_EVSEMaxPowerLimit 0;
BA_ "GenSigTimeoutTime_PPIM" SG_ 498 HVCMS_EVSEMaxPowerLimit 0;
BA_ "GenSigTimeoutTime_APM2" SG_ 498 HVCMS_EVSEMaxPowerLimit 0;
BA_ "GenSigTimeoutTime_VDCM" SG_ 498 HVCMS_EVSEMaxPowerLimit 0;
BA_ "GenSigTimeoutTime_HCP" SG_ 498 HVCMS_EVSEMinCurrentLimit 0;
BA_ "GenSigTimeoutTime_PPIM" SG_ 498 HVCMS_EVSEMinCurrentLimit 0;
BA_ "GenSigTimeoutTime_APM2" SG_ 498 HVCMS_EVSEMinCurrentLimit 0;
BA_ "GenSigTimeoutTime_VDCM" SG_ 498 HVCMS_EVSEMinCurrentLimit 0;
BA_ "GenSigTimeoutTime_HCP" SG_ 498 HVCMS_EVSEPeakCurrentRipple 0;
BA_ "GenSigTimeoutTime_PPIM" SG_ 498 HVCMS_EVSEPeakCurrentRipple 0;
BA_ "GenSigTimeoutTime_APM2" SG_ 498 HVCMS_EVSEPeakCurrentRipple 0;
BA_ "GenSigTimeoutTime_VDCM" SG_ 498 HVCMS_EVSEPeakCurrentRipple 0;
BA_ "GenSigTimeoutTime_HCP" SG_ 498 HVCMS_EVSEPresentVoltage 0;
BA_ "GenSigTimeoutTime_PPIM" SG_ 498 HVCMS_EVSEPresentVoltage 0;
BA_ "GenSigTimeoutTime_APM2" SG_ 498 HVCMS_EVSEPresentVoltage 0;
BA_ "GenSigTimeoutTime_VDCM" SG_ 498 HVCMS_EVSEPresentVoltage 0;
BA_ "GenSigTimeoutTime_BPCM" SG_ 498 HVCMS_EVSEPresentVoltage 0;
BA_ "GenSigTimeoutTime_IDCM" SG_ 498 HVCMS_EVSEPresentVoltage 0;
BA_ "GenSigTimeoutTime_SGW" SG_ 498 HVCMS_EVSEPresentVoltage 0;
BA_ "GenSigStartValue" SG_ 498 HVCMS_EVSEPeakCurrentRipple 500;
BA_ "GenSigTimeoutTime_BPCM" SG_ 498 HVCMS_EVSEPeakCurrentRipple 0;
BA_ "GenSigTimeoutTime_IDCM" SG_ 498 HVCMS_EVSEPeakCurrentRipple 0;
BA_ "GenSigTimeoutTime_SGW" SG_ 498 HVCMS_EVSEPeakCurrentRipple 0;
BA_ "GenSigTimeoutTime_HCP" SG_ 502 HVCMS_BulkChargingComplete 0;
BA_ "GenSigTimeoutTime_PPIM" SG_ 502 HVCMS_BulkChargingComplete 0;
BA_ "GenSigTimeoutTime_APM2" SG_ 502 HVCMS_BulkChargingComplete 0;
BA_ "GenSigTimeoutTime_VDCM" SG_ 502 HVCMS_BulkChargingComplete 0;
BA_ "GenSigTimeoutTime_BPCM" SG_ 502 HVCMS_BulkChargingComplete 0;
BA_ "GenSigTimeoutTime_EVCU2" SG_ 502 HVCMS_BulkChargingComplete 0;
BA_ "GenSigTimeoutTime_SGW" SG_ 502 HVCMS_BulkChargingComplete 0;
BA_ "GenSigTimeoutTime_HCP" SG_ 502 HVCMS_ChargingComplete 0;
BA_ "GenSigTimeoutTime_PPIM" SG_ 502 HVCMS_ChargingComplete 0;
BA_ "GenSigTimeoutTime_APM2" SG_ 502 HVCMS_ChargingComplete 0;
BA_ "GenSigTimeoutTime_VDCM" SG_ 502 HVCMS_ChargingComplete 0;
BA_ "GenSigTimeoutTime_BPCM" SG_ 502 HVCMS_ChargingComplete 0;
BA_ "GenSigTimeoutTime_EVCU2" SG_ 502 HVCMS_ChargingComplete 0;
BA_ "GenSigTimeoutTime_SGW" SG_ 502 HVCMS_ChargingComplete 0;
BA_ "GenSigTimeoutTime_BPCM" SG_ 498 HVCMS_EVSEMinCurrentLimit 0;
BA_ "GenSigTimeoutTime_IDCM" SG_ 498 HVCMS_EVSEMinCurrentLimit 0;
BA_ "GenSigTimeoutTime_SGW" SG_ 498 HVCMS_EVSEMinCurrentLimit 0;
BA_ "GenSigTimeoutTime_BPCM" SG_ 498 HVCMS_EVSEMaxPowerLimit 0;
BA_ "GenSigTimeoutTime_IDCM" SG_ 498 HVCMS_EVSEMaxPowerLimit 0;
BA_ "GenSigTimeoutTime_SGW" SG_ 498 HVCMS_EVSEMaxPowerLimit 0;
BA_ "GenSigTimeoutTime_BPCM" SG_ 498 HVCMS_EVSEMaxCurrentLimit 0;
BA_ "GenSigTimeoutTime_IDCM" SG_ 498 HVCMS_EVSEMaxCurrentLimit 0;
BA_ "GenSigTimeoutTime_SGW" SG_ 498 HVCMS_EVSEMaxCurrentLimit 0;
BA_ "GenSigStartValue" SG_ 498 HVCMS_EVSECurrRegulationTol 500;
BA_ "GenSigTimeoutTime_BPCM" SG_ 498 HVCMS_EVSECurrRegulationTol 0;
BA_ "GenSigTimeoutTime_IDCM" SG_ 498 HVCMS_EVSECurrRegulationTol 0;
BA_ "GenSigTimeoutTime_SGW" SG_ 498 HVCMS_EVSECurrRegulationTol 0;
BA_ "GenSigTimeoutTime_EVCU2" SG_ 502 HVCMS_EVEnergyCapacity 0;
BA_ "GenSigTimeoutTime_SGW" SG_ 502 HVCMS_EVEnergyCapacity 0;
BA_ "GenSigTimeoutTime_HCP" SG_ 502 HVCMS_EVEnergyCapacity 0;
BA_ "GenSigTimeoutTime_PPIM" SG_ 502 HVCMS_EVEnergyCapacity 0;
BA_ "GenSigTimeoutTime_APM2" SG_ 502 HVCMS_EVEnergyCapacity 0;
BA_ "GenSigTimeoutTime_VDCM" SG_ 502 HVCMS_EVEnergyCapacity 0;
BA_ "GenSigTimeoutTime_BPCM" SG_ 502 HVCMS_EVEnergyCapacity 0;
BA_ "GenSigTimeoutTime_BPCM" SG_ 502 HVCMS_EVMax_I_Limit 0;
BA_ "GenSigTimeoutTime_EVCU2" SG_ 502 HVCMS_EVMax_I_Limit 0;
BA_ "GenSigTimeoutTime_SGW" SG_ 502 HVCMS_EVMax_I_Limit 0;
BA_ "GenSigTimeoutTime_HCP" SG_ 502 HVCMS_EVMax_I_Limit 0;
BA_ "GenSigTimeoutTime_PPIM" SG_ 502 HVCMS_EVMax_I_Limit 0;
BA_ "GenSigTimeoutTime_APM2" SG_ 502 HVCMS_EVMax_I_Limit 0;
BA_ "GenSigTimeoutTime_VDCM" SG_ 502 HVCMS_EVMax_I_Limit 0;
BA_ "GenSigTimeoutTime_BPCM" SG_ 502 HVCMS_EVMax_P_Limit 0;
BA_ "GenSigTimeoutTime_EVCU2" SG_ 502 HVCMS_EVMax_P_Limit 0;
BA_ "GenSigTimeoutTime_SGW" SG_ 502 HVCMS_EVMax_P_Limit 0;
BA_ "GenSigTimeoutTime_HCP" SG_ 502 HVCMS_EVMax_P_Limit 0;
BA_ "GenSigTimeoutTime_PPIM" SG_ 502 HVCMS_EVMax_P_Limit 0;
BA_ "GenSigTimeoutTime_APM2" SG_ 502 HVCMS_EVMax_P_Limit 0;
BA_ "GenSigTimeoutTime_VDCM" SG_ 502 HVCMS_EVMax_P_Limit 0;
BA_ "GenSigTimeoutTime_BPCM" SG_ 502 HVCMS_EVMax_V_Limit 0;
BA_ "GenSigTimeoutTime_EVCU2" SG_ 502 HVCMS_EVMax_V_Limit 0;
BA_ "GenSigTimeoutTime_SGW" SG_ 502 HVCMS_EVMax_V_Limit 0;
BA_ "GenSigTimeoutTime_HCP" SG_ 502 HVCMS_EVMax_V_Limit 0;
BA_ "GenSigTimeoutTime_PPIM" SG_ 502 HVCMS_EVMax_V_Limit 0;
BA_ "GenSigTimeoutTime_APM2" SG_ 502 HVCMS_EVMax_V_Limit 0;
BA_ "GenSigTimeoutTime_VDCM" SG_ 502 HVCMS_EVMax_V_Limit 0;
BA_ "GenSigTimeoutTime_HCP" SG_ 502 HVCMS_EVReady 0;
BA_ "GenSigTimeoutTime_PPIM" SG_ 502 HVCMS_EVReady 0;
BA_ "GenSigTimeoutTime_APM2" SG_ 502 HVCMS_EVReady 0;
BA_ "GenSigTimeoutTime_VDCM" SG_ 502 HVCMS_EVReady 0;
BA_ "GenSigTimeoutTime_BPCM" SG_ 502 HVCMS_EVReady 0;
BA_ "GenSigTimeoutTime_EVCU2" SG_ 502 HVCMS_EVReady 0;
BA_ "GenSigTimeoutTime_SGW" SG_ 502 HVCMS_EVReady 0;
BA_ "GenSigTimeoutTime_HCP" SG_ 502 HVCMS_EVRESS_SOC 0;
BA_ "GenSigTimeoutTime_PPIM" SG_ 502 HVCMS_EVRESS_SOC 0;
BA_ "GenSigTimeoutTime_APM2" SG_ 502 HVCMS_EVRESS_SOC 0;
BA_ "GenSigTimeoutTime_VDCM" SG_ 502 HVCMS_EVRESS_SOC 0;
BA_ "GenSigTimeoutTime_BPCM" SG_ 502 HVCMS_EVRESS_SOC 0;
BA_ "GenSigTimeoutTime_EVCU2" SG_ 502 HVCMS_EVRESS_SOC 0;
BA_ "GenSigTimeoutTime_SGW" SG_ 502 HVCMS_EVRESS_SOC 0;
BA_ "GenSigTimeoutTime_HCP" SG_ 502 HVCMS_EVRESSConditioning 0;
BA_ "GenSigTimeoutTime_PPIM" SG_ 502 HVCMS_EVRESSConditioning 0;
BA_ "GenSigTimeoutTime_APM2" SG_ 502 HVCMS_EVRESSConditioning 0;
BA_ "GenSigTimeoutTime_VDCM" SG_ 502 HVCMS_EVRESSConditioning 0;
BA_ "GenSigTimeoutTime_BPCM" SG_ 502 HVCMS_EVRESSConditioning 0;
BA_ "GenSigTimeoutTime_EVCU2" SG_ 502 HVCMS_EVRESSConditioning 0;
BA_ "GenSigTimeoutTime_SGW" SG_ 502 HVCMS_EVRESSConditioning 0;
BA_ "GenSigTimeoutTime_HCP" SG_ 502 HVCMS_EVTargetCurrent 0;
BA_ "GenSigTimeoutTime_PPIM" SG_ 502 HVCMS_EVTargetCurrent 0;
BA_ "GenSigTimeoutTime_APM2" SG_ 502 HVCMS_EVTargetCurrent 0;
BA_ "GenSigTimeoutTime_VDCM" SG_ 502 HVCMS_EVTargetCurrent 0;
BA_ "GenSigTimeoutTime_BPCM" SG_ 502 HVCMS_EVTargetCurrent 0;
BA_ "GenSigTimeoutTime_EVCU2" SG_ 502 HVCMS_EVTargetCurrent 0;
BA_ "GenSigTimeoutTime_SGW" SG_ 502 HVCMS_EVTargetCurrent 0;
BA_ "GenSigTimeoutTime_HCP" SG_ 502 VDCM_BattBulkSOC 0;
BA_ "GenSigTimeoutTime_PPIM" SG_ 502 VDCM_BattBulkSOC 0;
BA_ "GenSigTimeoutTime_APM2" SG_ 502 VDCM_BattBulkSOC 0;
BA_ "GenSigTimeoutTime_VDCM" SG_ 502 VDCM_BattBulkSOC 0;
BA_ "GenSigTimeoutTime_HCP" SG_ 502 HVCMS_ReadyToChargeState 0;
BA_ "GenSigTimeoutTime_PPIM" SG_ 502 HVCMS_ReadyToChargeState 0;
BA_ "GenSigTimeoutTime_APM2" SG_ 502 HVCMS_ReadyToChargeState 0;
BA_ "GenSigTimeoutTime_VDCM" SG_ 502 HVCMS_ReadyToChargeState 0;
BA_ "GenSigTimeoutTime_HCP" SG_ 502 HVCMS_ServiceScope 0;
BA_ "GenSigTimeoutTime_PPIM" SG_ 502 HVCMS_ServiceScope 0;
BA_ "GenSigTimeoutTime_APM2" SG_ 502 HVCMS_ServiceScope 0;
BA_ "GenSigTimeoutTime_VDCM" SG_ 502 HVCMS_ServiceScope 0;
BA_ "GenSigTimeoutTime_HCP" SG_ 502 HVCMS_EVTargetVoltage 0;
BA_ "GenSigTimeoutTime_PPIM" SG_ 502 HVCMS_EVTargetVoltage 0;
BA_ "GenSigTimeoutTime_APM2" SG_ 502 HVCMS_EVTargetVoltage 0;
BA_ "GenSigTimeoutTime_VDCM" SG_ 502 HVCMS_EVTargetVoltage 0;
BA_ "GenSigTimeoutTime_BPCM" SG_ 502 HVCMS_EVTargetVoltage 0;
BA_ "GenSigTimeoutTime_EVCU2" SG_ 502 HVCMS_EVTargetVoltage 0;
BA_ "GenSigTimeoutTime_SGW" SG_ 502 HVCMS_EVTargetVoltage 0;
BA_ "GenSigTimeoutTime_HCP" SG_ 502 HVCMS_Protocol_Entry1 0;
BA_ "GenSigTimeoutTime_PPIM" SG_ 502 HVCMS_Protocol_Entry1 0;
BA_ "GenSigTimeoutTime_APM2" SG_ 502 HVCMS_Protocol_Entry1 0;
BA_ "GenSigTimeoutTime_VDCM" SG_ 502 HVCMS_Protocol_Entry1 0;
BA_ "GenSigTimeoutTime_BPCM" SG_ 502 HVCMS_Protocol_Entry1 0;
BA_ "GenSigTimeoutTime_EVCU2" SG_ 502 HVCMS_Protocol_Entry1 0;
BA_ "GenSigTimeoutTime_SGW" SG_ 502 HVCMS_Protocol_Entry1 0;
BA_ "GenSigTimeoutTime_HCP" SG_ 502 HVCMS_Protocol_Entry2 0;
BA_ "GenSigTimeoutTime_PPIM" SG_ 502 HVCMS_Protocol_Entry2 0;
BA_ "GenSigTimeoutTime_APM2" SG_ 502 HVCMS_Protocol_Entry2 0;
BA_ "GenSigTimeoutTime_VDCM" SG_ 502 HVCMS_Protocol_Entry2 0;
BA_ "GenSigTimeoutTime_HCP" SG_ 502 HVCMS_Protocol_Entry3 0;
BA_ "GenSigTimeoutTime_PPIM" SG_ 502 HVCMS_Protocol_Entry3 0;
BA_ "GenSigTimeoutTime_APM2" SG_ 502 HVCMS_Protocol_Entry3 0;
BA_ "GenSigTimeoutTime_VDCM" SG_ 502 HVCMS_Protocol_Entry3 0;
BA_ "GenSigTimeoutTime_HCP" SG_ 502 VDCM_OBCDischCurrentLim 0;
BA_ "GenSigTimeoutTime_PPIM" SG_ 502 VDCM_OBCDischCurrentLim 0;
BA_ "GenSigTimeoutTime_APM2" SG_ 502 VDCM_OBCDischCurrentLim 0;
BA_ "GenSigTimeoutTime_VDCM" SG_ 502 VDCM_OBCDischCurrentLim 0;
BA_ "GenSigTimeoutTime_BPCM" SG_ 502 OBCM_OutVoltageSyncTgt 0;
BA_ "GenSigTimeoutTime_EVCU2" SG_ 502 OBCM_OutVoltageSyncTgt 0;
BA_ "GenSigTimeoutTime_SGW" SG_ 502 OBCM_OutVoltageSyncTgt 0;
BA_ "GenSigTimeoutTime_HCP" SG_ 502 OBCM_OutVoltageSyncTgt 0;
BA_ "GenSigTimeoutTime_PPIM" SG_ 502 OBCM_OutVoltageSyncTgt 0;
BA_ "GenSigTimeoutTime_APM2" SG_ 502 OBCM_OutVoltageSyncTgt 0;
BA_ "GenSigTimeoutTime_VDCM" SG_ 502 OBCM_OutVoltageSyncTgt 0;
BA_ "GenSigTimeoutTime_HCP" SG_ 502 VDCM_ContractAuthenticationID 0;
BA_ "GenSigTimeoutTime_PPIM" SG_ 502 VDCM_ContractAuthenticationID 0;
BA_ "GenSigTimeoutTime_APM2" SG_ 502 VDCM_ContractAuthenticationID 0;
BA_ "GenSigTimeoutTime_VDCM" SG_ 502 VDCM_ContractAuthenticationID 0;
BA_ "GenSigStartValue" SG_ 502 HVCMS_EVEnergyRequest 131071;
BA_ "GenSigTimeoutTime_BPCM" SG_ 502 HVCMS_EVEnergyRequest 0;
BA_ "GenSigTimeoutTime_EVCU2" SG_ 502 HVCMS_EVEnergyRequest 0;
BA_ "GenSigTimeoutTime_SGW" SG_ 502 HVCMS_EVEnergyRequest 0;
BA_ "GenSigTimeoutTime_HCP" SG_ 502 HVCMS_EVEnergyRequest 0;
BA_ "GenSigTimeoutTime_PPIM" SG_ 502 HVCMS_EVEnergyRequest 0;
BA_ "GenSigTimeoutTime_APM2" SG_ 502 HVCMS_EVEnergyRequest 0;
BA_ "GenSigTimeoutTime_VDCM" SG_ 502 HVCMS_EVEnergyRequest 0;
BA_ "GenSigTimeoutTime_HCP" SG_ 502 VDCM_GenChallenge 0;
BA_ "GenSigTimeoutTime_PPIM" SG_ 502 VDCM_GenChallenge 0;
BA_ "GenSigTimeoutTime_APM2" SG_ 502 VDCM_GenChallenge 0;
BA_ "GenSigTimeoutTime_VDCM" SG_ 502 VDCM_GenChallenge 0;
BA_ "GenSigTimeoutTime_HCP" SG_ 502 VDCM_TypeCNegotiationSts 0;
BA_ "GenSigTimeoutTime_PPIM" SG_ 502 VDCM_TypeCNegotiationSts 0;
BA_ "GenSigTimeoutTime_APM2" SG_ 502 VDCM_TypeCNegotiationSts 0;
BA_ "GenSigTimeoutTime_VDCM" SG_ 502 VDCM_TypeCNegotiationSts 0;
BA_ "GenSigTimeoutTime_BPCM" SG_ 502 HVCMS_ServiceCategory 0;
BA_ "GenSigTimeoutTime_EVCU2" SG_ 502 HVCMS_ServiceCategory 0;
BA_ "GenSigTimeoutTime_SGW" SG_ 502 HVCMS_ServiceCategory 0;
BA_ "GenSigTimeoutTime_HCP" SG_ 502 HVCMS_ServiceCategory 0;
BA_ "GenSigTimeoutTime_PPIM" SG_ 502 HVCMS_ServiceCategory 0;
BA_ "GenSigTimeoutTime_APM2" SG_ 502 HVCMS_ServiceCategory 0;
BA_ "GenSigTimeoutTime_VDCM" SG_ 502 HVCMS_ServiceCategory 0;
BA_ "GenSigTimeoutTime_HCP" SG_ 502 HVCMS_SelectedPaymentOptn 0;
BA_ "GenSigTimeoutTime_PPIM" SG_ 502 HVCMS_SelectedPaymentOptn 0;
BA_ "GenSigTimeoutTime_APM2" SG_ 502 HVCMS_SelectedPaymentOptn 0;
BA_ "GenSigTimeoutTime_VDCM" SG_ 502 HVCMS_SelectedPaymentOptn 0;
BA_ "GenSigTimeoutTime_HCP" SG_ 502 HVCMS_SelectedServiceId 0;
BA_ "GenSigTimeoutTime_PPIM" SG_ 502 HVCMS_SelectedServiceId 0;
BA_ "GenSigTimeoutTime_APM2" SG_ 502 HVCMS_SelectedServiceId 0;
BA_ "GenSigTimeoutTime_VDCM" SG_ 502 HVCMS_SelectedServiceId 0;
BA_ "GenSigTimeoutTime_HCP" SG_ 502 HVCMS_EVErrorCode 0;
BA_ "GenSigTimeoutTime_PPIM" SG_ 502 HVCMS_EVErrorCode 0;
BA_ "GenSigTimeoutTime_APM2" SG_ 502 HVCMS_EVErrorCode 0;
BA_ "GenSigTimeoutTime_VDCM" SG_ 502 HVCMS_EVErrorCode 0;
BA_ "GenSigTimeoutTime_HCP" SG_ 502 HVCMS_RemaningTimeToBulkSOC 0;
BA_ "GenSigTimeoutTime_PPIM" SG_ 502 HVCMS_RemaningTimeToBulkSOC 0;
BA_ "GenSigTimeoutTime_APM2" SG_ 502 HVCMS_RemaningTimeToBulkSOC 0;
BA_ "GenSigTimeoutTime_VDCM" SG_ 502 HVCMS_RemaningTimeToBulkSOC 0;
BA_ "GenSigTimeoutTime_HCP" SG_ 502 HVCMS_RemaningTimeToFullSOC 0;
BA_ "GenSigTimeoutTime_PPIM" SG_ 502 HVCMS_RemaningTimeToFullSOC 0;
BA_ "GenSigTimeoutTime_APM2" SG_ 502 HVCMS_RemaningTimeToFullSOC 0;
BA_ "GenSigTimeoutTime_VDCM" SG_ 502 HVCMS_RemaningTimeToFullSOC 0;
BA_ "GenSigTimeoutTime_HCP" SG_ 502 HVCMS_SelectedEnergyTransferType 0;
BA_ "GenSigTimeoutTime_PPIM" SG_ 502 HVCMS_SelectedEnergyTransferType 0;
BA_ "GenSigTimeoutTime_APM2" SG_ 502 HVCMS_SelectedEnergyTransferType 0;
BA_ "GenSigTimeoutTime_VDCM" SG_ 502 HVCMS_SelectedEnergyTransferType 0;
BA_ "GenSigTimeoutTime_BPCM" SG_ 502 VDCM_TypeCNegotiationSts 0;
BA_ "GenSigTimeoutTime_EVCU2" SG_ 502 VDCM_TypeCNegotiationSts 0;
BA_ "GenSigTimeoutTime_SGW" SG_ 502 VDCM_TypeCNegotiationSts 0;
BA_ "GenSigTimeoutTime_BPCM" SG_ 502 VDCM_GenChallenge 0;
BA_ "GenSigTimeoutTime_EVCU2" SG_ 502 VDCM_GenChallenge 0;
BA_ "GenSigTimeoutTime_SGW" SG_ 502 VDCM_GenChallenge 0;
BA_ "GenSigTimeoutTime_BPCM" SG_ 502 HVCMS_ReadyToChargeState 0;
BA_ "GenSigTimeoutTime_EVCU2" SG_ 502 HVCMS_ReadyToChargeState 0;
BA_ "GenSigTimeoutTime_SGW" SG_ 502 HVCMS_ReadyToChargeState 0;
BA_ "GenSigTimeoutTime_BPCM" SG_ 502 HVCMS_Protocol_Entry3 0;
BA_ "GenSigTimeoutTime_EVCU2" SG_ 502 HVCMS_Protocol_Entry3 0;
BA_ "GenSigTimeoutTime_SGW" SG_ 502 HVCMS_Protocol_Entry3 0;
BA_ "GenSigTimeoutTime_BPCM" SG_ 502 VDCM_BattBulkSOC 0;
BA_ "GenSigTimeoutTime_EVCU2" SG_ 502 VDCM_BattBulkSOC 0;
BA_ "GenSigTimeoutTime_SGW" SG_ 502 VDCM_BattBulkSOC 0;
BA_ "GenSigTimeoutTime_BPCM" SG_ 502 HVCMS_ServiceScope 0;
BA_ "GenSigTimeoutTime_EVCU2" SG_ 502 HVCMS_ServiceScope 0;
BA_ "GenSigTimeoutTime_SGW" SG_ 502 HVCMS_ServiceScope 0;
BA_ "GenSigStartValue" SG_ 502 VDCM_OBCDischCurrentLim 815;
BA_ "GenSigTimeoutTime_BPCM" SG_ 502 VDCM_OBCDischCurrentLim 0;
BA_ "GenSigTimeoutTime_EVCU2" SG_ 502 VDCM_OBCDischCurrentLim 0;
BA_ "GenSigTimeoutTime_SGW" SG_ 502 VDCM_OBCDischCurrentLim 0;
BA_ "GenSigTimeoutTime_BPCM" SG_ 502 HVCMS_Protocol_Entry2 0;
BA_ "GenSigTimeoutTime_EVCU2" SG_ 502 HVCMS_Protocol_Entry2 0;
BA_ "GenSigTimeoutTime_SGW" SG_ 502 HVCMS_Protocol_Entry2 0;
BA_ "GenSigTimeoutTime_BPCM" SG_ 502 VDCM_ContractAuthenticationID 0;
BA_ "GenSigTimeoutTime_EVCU2" SG_ 502 VDCM_ContractAuthenticationID 0;
BA_ "GenSigTimeoutTime_SGW" SG_ 502 VDCM_ContractAuthenticationID 0;
BA_ "GenSigTimeoutTime_BPCM" SG_ 502 HVCMS_SelectedEnergyTransferType 0;
BA_ "GenSigTimeoutTime_EVCU2" SG_ 502 HVCMS_SelectedEnergyTransferType 0;
BA_ "GenSigTimeoutTime_SGW" SG_ 502 HVCMS_SelectedEnergyTransferType 0;
BA_ "GenSigTimeoutTime_BPCM" SG_ 502 HVCMS_RemaningTimeToFullSOC 0;
BA_ "GenSigTimeoutTime_EVCU2" SG_ 502 HVCMS_RemaningTimeToFullSOC 0;
BA_ "GenSigTimeoutTime_SGW" SG_ 502 HVCMS_RemaningTimeToFullSOC 0;
BA_ "GenSigTimeoutTime_BPCM" SG_ 502 HVCMS_RemaningTimeToBulkSOC 0;
BA_ "GenSigTimeoutTime_EVCU2" SG_ 502 HVCMS_RemaningTimeToBulkSOC 0;
BA_ "GenSigTimeoutTime_SGW" SG_ 502 HVCMS_RemaningTimeToBulkSOC 0;
BA_ "GenSigTimeoutTime_BPCM" SG_ 502 HVCMS_EVErrorCode 0;
BA_ "GenSigTimeoutTime_EVCU2" SG_ 502 HVCMS_EVErrorCode 0;
BA_ "GenSigTimeoutTime_SGW" SG_ 502 HVCMS_EVErrorCode 0;
BA_ "GenSigTimeoutTime_BPCM" SG_ 502 HVCMS_SelectedServiceId 0;
BA_ "GenSigTimeoutTime_EVCU2" SG_ 502 HVCMS_SelectedServiceId 0;
BA_ "GenSigTimeoutTime_SGW" SG_ 502 HVCMS_SelectedServiceId 0;
BA_ "GenSigTimeoutTime_BPCM" SG_ 502 HVCMS_SelectedPaymentOptn 0;
BA_ "GenSigTimeoutTime_EVCU2" SG_ 502 HVCMS_SelectedPaymentOptn 0;
BA_ "GenSigTimeoutTime_SGW" SG_ 502 HVCMS_SelectedPaymentOptn 0;
BA_ "GenSigTimeoutTime_APM2" SG_ 2564485397 N_PDU_18DAF115 0;
BA_ "GenSigTimeoutTime_BPCM" SG_ 2564485397 N_PDU_18DAF115 0;
BA_ "GenSigTimeoutTime_EVCU2" SG_ 2564485397 N_PDU_18DAF115 0;
BA_ "GenSigTimeoutTime_IDCM" SG_ 2564485397 N_PDU_18DAF115 0;
BA_ "GenSigTimeoutTime_SGW" SG_ 2564485397 N_PDU_18DAF115 0;
BA_ "GenSigTimeoutTime_APM2" SG_ 2651930775 Digit_09_APM2 0;
BA_ "GenSigTimeoutTime_BPCM" SG_ 2651930775 Digit_09_APM2 0;
BA_ "GenSigTimeoutTime_IDCM" SG_ 2651930775 Digit_09_APM2 0;
BA_ "GenSigTimeoutTime_SGW" SG_ 2651930775 Digit_09_APM2 0;
BA_ "GenSigTimeoutTime_VDCM" SG_ 2651930775 Digit_09_APM2 0;
BA_ "GenSigTimeoutTime_VDCM" SG_ 2651930775 Digit_01_APM2 0;
BA_ "GenSigTimeoutTime_APM2" SG_ 2651930775 Digit_01_APM2 0;
BA_ "GenSigSendType" SG_ 2651930775 Digit_01_APM2 1;
BA_ "GenSigTimeoutTime_BPCM" SG_ 2651930775 Digit_01_APM2 0;
BA_ "GenSigTimeoutTime_IDCM" SG_ 2651930775 Digit_01_APM2 0;
BA_ "GenSigTimeoutTime_SGW" SG_ 2651930775 Digit_01_APM2 0;
BA_ "GenSigTimeoutTime_VDCM" SG_ 2651930775 Digit_02_APM2 0;
BA_ "GenSigTimeoutTime_APM2" SG_ 2651930775 Digit_02_APM2 0;
BA_ "GenSigTimeoutTime_BPCM" SG_ 2651930775 Digit_02_APM2 0;
BA_ "GenSigTimeoutTime_IDCM" SG_ 2651930775 Digit_02_APM2 0;
BA_ "GenSigTimeoutTime_SGW" SG_ 2651930775 Digit_02_APM2 0;
BA_ "GenSigTimeoutTime_VDCM" SG_ 2651930775 Digit_03_APM2 0;
BA_ "GenSigTimeoutTime_APM2" SG_ 2651930775 Digit_03_APM2 0;
BA_ "GenSigTimeoutTime_BPCM" SG_ 2651930775 Digit_03_APM2 0;
BA_ "GenSigTimeoutTime_IDCM" SG_ 2651930775 Digit_03_APM2 0;
BA_ "GenSigTimeoutTime_SGW" SG_ 2651930775 Digit_03_APM2 0;
BA_ "GenSigTimeoutTime_SGW" SG_ 2651930775 Digit_04_APM2 0;
BA_ "GenSigTimeoutTime_VDCM" SG_ 2651930775 Digit_04_APM2 0;
BA_ "GenSigTimeoutTime_APM2" SG_ 2651930775 Digit_04_APM2 0;
BA_ "GenSigTimeoutTime_BPCM" SG_ 2651930775 Digit_04_APM2 0;
BA_ "GenSigTimeoutTime_IDCM" SG_ 2651930775 Digit_04_APM2 0;
BA_ "GenSigTimeoutTime_APM2" SG_ 2651930775 Digit_05_APM2 0;
BA_ "GenSigTimeoutTime_BPCM" SG_ 2651930775 Digit_05_APM2 0;
BA_ "GenSigTimeoutTime_IDCM" SG_ 2651930775 Digit_05_APM2 0;
BA_ "GenSigTimeoutTime_SGW" SG_ 2651930775 Digit_05_APM2 0;
BA_ "GenSigTimeoutTime_VDCM" SG_ 2651930775 Digit_05_APM2 0;
BA_ "GenSigTimeoutTime_APM2" SG_ 2651930775 Digit_06_APM2 0;
BA_ "GenSigTimeoutTime_BPCM" SG_ 2651930775 Digit_06_APM2 0;
BA_ "GenSigTimeoutTime_IDCM" SG_ 2651930775 Digit_06_APM2 0;
BA_ "GenSigTimeoutTime_SGW" SG_ 2651930775 Digit_06_APM2 0;
BA_ "GenSigTimeoutTime_VDCM" SG_ 2651930775 Digit_06_APM2 0;
BA_ "GenSigTimeoutTime_APM2" SG_ 1850 HVBatCellVoltage_Cell162 0;
BA_ "GenSigTimeoutTime_VDCM" SG_ 1850 HVBatCellVoltage_Cell162 0;
BA_ "GenSigTimeoutTime_APM2" SG_ 1850 HVBatCellVoltage_Cell161 0;
BA_ "GenSigTimeoutTime_BPCM" SG_ 1850 HVBatCellVoltage_Cell161 0;
BA_ "GenSigTimeoutTime_EVCU2" SG_ 1850 HVBatCellVoltage_Cell161 0;
BA_ "GenSigTimeoutTime_IDCM" SG_ 1850 HVBatCellVoltage_Cell161 0;
BA_ "GenSigTimeoutTime_VDCM" SG_ 1850 HVBatCellVoltage_Cell161 0;
BA_ "GenSigTimeoutTime_APM2" SG_ 1849 HVBatCellVoltage_Cell130 0;
BA_ "GenSigTimeoutTime_BPCM" SG_ 1849 HVBatCellVoltage_Cell130 0;
BA_ "GenSigTimeoutTime_EVCU2" SG_ 1849 HVBatCellVoltage_Cell130 0;
BA_ "GenSigTimeoutTime_IDCM" SG_ 1849 HVBatCellVoltage_Cell130 0;
BA_ "GenSigTimeoutTime_APM2" SG_ 1849 HVBatCellVoltage_Cell132 0;
BA_ "GenSigTimeoutTime_BPCM" SG_ 1849 HVBatCellVoltage_Cell132 0;
BA_ "GenSigTimeoutTime_EVCU2" SG_ 1849 HVBatCellVoltage_Cell132 0;
BA_ "GenSigTimeoutTime_IDCM" SG_ 1849 HVBatCellVoltage_Cell132 0;
BA_ "GenSigTimeoutTime_APM2" SG_ 1849 HVBatCellVoltage_Cell131 0;
BA_ "GenSigTimeoutTime_BPCM" SG_ 1849 HVBatCellVoltage_Cell131 0;
BA_ "GenSigTimeoutTime_EVCU2" SG_ 1849 HVBatCellVoltage_Cell131 0;
BA_ "GenSigTimeoutTime_IDCM" SG_ 1849 HVBatCellVoltage_Cell131 0;
BA_ "GenSigTimeoutTime_APM2" SG_ 1849 HVBatCellVoltage_Cell135 0;
BA_ "GenSigTimeoutTime_BPCM" SG_ 1849 HVBatCellVoltage_Cell135 0;
BA_ "GenSigTimeoutTime_EVCU2" SG_ 1849 HVBatCellVoltage_Cell135 0;
BA_ "GenSigTimeoutTime_IDCM" SG_ 1849 HVBatCellVoltage_Cell135 0;
BA_ "GenSigTimeoutTime_VDCM" SG_ 1850 HVBatCellVoltage_Cell136 0;
BA_ "GenSigTimeoutTime_APM2" SG_ 1850 HVBatCellVoltage_Cell136 0;
BA_ "GenSigTimeoutTime_BPCM" SG_ 1850 HVBatCellVoltage_Cell136 0;
BA_ "GenSigTimeoutTime_EVCU2" SG_ 1850 HVBatCellVoltage_Cell136 0;
BA_ "GenSigTimeoutTime_IDCM" SG_ 1850 HVBatCellVoltage_Cell136 0;
BA_ "GenSigTimeoutTime_APM2" SG_ 1849 HVBatCellVoltage_Cell134 0;
BA_ "GenSigTimeoutTime_BPCM" SG_ 1849 HVBatCellVoltage_Cell134 0;
BA_ "GenSigTimeoutTime_EVCU2" SG_ 1849 HVBatCellVoltage_Cell134 0;
BA_ "GenSigTimeoutTime_IDCM" SG_ 1849 HVBatCellVoltage_Cell134 0;
BA_ "GenSigTimeoutTime_APM2" SG_ 1849 HVBatCellVoltage_Cell133 0;
BA_ "GenSigTimeoutTime_BPCM" SG_ 1849 HVBatCellVoltage_Cell133 0;
BA_ "GenSigTimeoutTime_EVCU2" SG_ 1849 HVBatCellVoltage_Cell133 0;
BA_ "GenSigTimeoutTime_IDCM" SG_ 1849 HVBatCellVoltage_Cell133 0;
BA_ "GenSigTimeoutTime_VDCM" SG_ 1850 HVBatCellVoltage_Cell137 0;
BA_ "GenSigTimeoutTime_APM2" SG_ 1850 HVBatCellVoltage_Cell137 0;
BA_ "GenSigTimeoutTime_BPCM" SG_ 1850 HVBatCellVoltage_Cell137 0;
BA_ "GenSigTimeoutTime_EVCU2" SG_ 1850 HVBatCellVoltage_Cell137 0;
BA_ "GenSigTimeoutTime_IDCM" SG_ 1850 HVBatCellVoltage_Cell137 0;
BA_ "GenSigTimeoutTime_IDCM" SG_ 1850 HVBatCellVoltage_Cell138 0;
BA_ "GenSigTimeoutTime_VDCM" SG_ 1850 HVBatCellVoltage_Cell138 0;
BA_ "GenSigTimeoutTime_APM2" SG_ 1850 HVBatCellVoltage_Cell138 0;
BA_ "GenSigTimeoutTime_BPCM" SG_ 1850 HVBatCellVoltage_Cell138 0;
BA_ "GenSigTimeoutTime_EVCU2" SG_ 1850 HVBatCellVoltage_Cell138 0;
BA_ "GenSigTimeoutTime_APM2" SG_ 1850 HVBatCellVoltage_Cell139 0;
BA_ "GenSigTimeoutTime_BPCM" SG_ 1850 HVBatCellVoltage_Cell139 0;
BA_ "GenSigTimeoutTime_EVCU2" SG_ 1850 HVBatCellVoltage_Cell139 0;
BA_ "GenSigTimeoutTime_IDCM" SG_ 1850 HVBatCellVoltage_Cell139 0;
BA_ "GenSigTimeoutTime_VDCM" SG_ 1850 HVBatCellVoltage_Cell139 0;
BA_ "GenSigTimeoutTime_VDCM" SG_ 1850 HVBatCellVoltage_Cell140 0;
BA_ "GenSigTimeoutTime_APM2" SG_ 1850 HVBatCellVoltage_Cell140 0;
BA_ "GenSigTimeoutTime_BPCM" SG_ 1850 HVBatCellVoltage_Cell140 0;
BA_ "GenSigTimeoutTime_EVCU2" SG_ 1850 HVBatCellVoltage_Cell140 0;
BA_ "GenSigTimeoutTime_IDCM" SG_ 1850 HVBatCellVoltage_Cell140 0;
BA_ "GenSigTimeoutTime_VDCM" SG_ 1850 HVBatCellVoltage_Cell141 0;
BA_ "GenSigTimeoutTime_APM2" SG_ 1850 HVBatCellVoltage_Cell141 0;
BA_ "GenSigTimeoutTime_BPCM" SG_ 1850 HVBatCellVoltage_Cell141 0;
BA_ "GenSigTimeoutTime_EVCU2" SG_ 1850 HVBatCellVoltage_Cell141 0;
BA_ "GenSigTimeoutTime_IDCM" SG_ 1850 HVBatCellVoltage_Cell141 0;
BA_ "GenSigTimeoutTime_VDCM" SG_ 1850 HVBatCellVoltage_Cell142 0;
BA_ "GenSigTimeoutTime_APM2" SG_ 1850 HVBatCellVoltage_Cell142 0;
BA_ "GenSigTimeoutTime_BPCM" SG_ 1850 HVBatCellVoltage_Cell142 0;
BA_ "GenSigTimeoutTime_EVCU2" SG_ 1850 HVBatCellVoltage_Cell142 0;
BA_ "GenSigTimeoutTime_IDCM" SG_ 1850 HVBatCellVoltage_Cell142 0;
BA_ "GenSigTimeoutTime_VDCM" SG_ 1850 HVBatCellVoltage_Cell143 0;
BA_ "GenSigTimeoutTime_APM2" SG_ 1850 HVBatCellVoltage_Cell143 0;
BA_ "GenSigTimeoutTime_BPCM" SG_ 1850 HVBatCellVoltage_Cell143 0;
BA_ "GenSigTimeoutTime_EVCU2" SG_ 1850 HVBatCellVoltage_Cell143 0;
BA_ "GenSigTimeoutTime_IDCM" SG_ 1850 HVBatCellVoltage_Cell143 0;
BA_ "GenSigTimeoutTime_VDCM" SG_ 1850 HVBatCellVoltage_Cell144 0;
BA_ "GenSigTimeoutTime_APM2" SG_ 1850 HVBatCellVoltage_Cell144 0;
BA_ "GenSigTimeoutTime_BPCM" SG_ 1850 HVBatCellVoltage_Cell144 0;
BA_ "GenSigTimeoutTime_EVCU2" SG_ 1850 HVBatCellVoltage_Cell144 0;
BA_ "GenSigTimeoutTime_IDCM" SG_ 1850 HVBatCellVoltage_Cell144 0;
BA_ "GenSigTimeoutTime_VDCM" SG_ 1850 HVBatCellVoltage_Cell145 0;
BA_ "GenSigTimeoutTime_APM2" SG_ 1850 HVBatCellVoltage_Cell145 0;
BA_ "GenSigTimeoutTime_BPCM" SG_ 1850 HVBatCellVoltage_Cell145 0;
BA_ "GenSigTimeoutTime_EVCU2" SG_ 1850 HVBatCellVoltage_Cell145 0;
BA_ "GenSigTimeoutTime_IDCM" SG_ 1850 HVBatCellVoltage_Cell145 0;
BA_ "GenSigTimeoutTime_VDCM" SG_ 1850 HVBatCellVoltage_Cell146 0;
BA_ "GenSigTimeoutTime_APM2" SG_ 1850 HVBatCellVoltage_Cell146 0;
BA_ "GenSigTimeoutTime_BPCM" SG_ 1850 HVBatCellVoltage_Cell146 0;
BA_ "GenSigTimeoutTime_EVCU2" SG_ 1850 HVBatCellVoltage_Cell146 0;
BA_ "GenSigTimeoutTime_IDCM" SG_ 1850 HVBatCellVoltage_Cell146 0;
BA_ "GenSigTimeoutTime_VDCM" SG_ 1850 HVBatCellVoltage_Cell147 0;
BA_ "GenSigTimeoutTime_APM2" SG_ 1850 HVBatCellVoltage_Cell147 0;
BA_ "GenSigTimeoutTime_BPCM" SG_ 1850 HVBatCellVoltage_Cell147 0;
BA_ "GenSigTimeoutTime_EVCU2" SG_ 1850 HVBatCellVoltage_Cell147 0;
BA_ "GenSigTimeoutTime_IDCM" SG_ 1850 HVBatCellVoltage_Cell147 0;
BA_ "GenSigTimeoutTime_VDCM" SG_ 1850 HVBatCellVoltage_Cell148 0;
BA_ "GenSigTimeoutTime_APM2" SG_ 1850 HVBatCellVoltage_Cell148 0;
BA_ "GenSigTimeoutTime_BPCM" SG_ 1850 HVBatCellVoltage_Cell148 0;
BA_ "GenSigTimeoutTime_EVCU2" SG_ 1850 HVBatCellVoltage_Cell148 0;
BA_ "GenSigTimeoutTime_IDCM" SG_ 1850 HVBatCellVoltage_Cell148 0;
BA_ "GenSigTimeoutTime_VDCM" SG_ 1850 HVBatCellVoltage_Cell149 0;
BA_ "GenSigTimeoutTime_APM2" SG_ 1850 HVBatCellVoltage_Cell149 0;
BA_ "GenSigTimeoutTime_BPCM" SG_ 1850 HVBatCellVoltage_Cell149 0;
BA_ "GenSigTimeoutTime_EVCU2" SG_ 1850 HVBatCellVoltage_Cell149 0;
BA_ "GenSigTimeoutTime_IDCM" SG_ 1850 HVBatCellVoltage_Cell149 0;
BA_ "GenSigTimeoutTime_VDCM" SG_ 1850 HVBatCellVoltage_Cell150 0;
BA_ "GenSigTimeoutTime_APM2" SG_ 1850 HVBatCellVoltage_Cell150 0;
BA_ "GenSigTimeoutTime_BPCM" SG_ 1850 HVBatCellVoltage_Cell150 0;
BA_ "GenSigTimeoutTime_EVCU2" SG_ 1850 HVBatCellVoltage_Cell150 0;
BA_ "GenSigTimeoutTime_IDCM" SG_ 1850 HVBatCellVoltage_Cell150 0;
BA_ "GenSigTimeoutTime_VDCM" SG_ 1850 HVBatCellVoltage_Cell151 0;
BA_ "GenSigTimeoutTime_APM2" SG_ 1850 HVBatCellVoltage_Cell151 0;
BA_ "GenSigTimeoutTime_BPCM" SG_ 1850 HVBatCellVoltage_Cell151 0;
BA_ "GenSigTimeoutTime_EVCU2" SG_ 1850 HVBatCellVoltage_Cell151 0;
BA_ "GenSigTimeoutTime_IDCM" SG_ 1850 HVBatCellVoltage_Cell151 0;
BA_ "GenSigTimeoutTime_VDCM" SG_ 1850 HVBatCellVoltage_Cell152 0;
BA_ "GenSigTimeoutTime_APM2" SG_ 1850 HVBatCellVoltage_Cell152 0;
BA_ "GenSigTimeoutTime_BPCM" SG_ 1850 HVBatCellVoltage_Cell152 0;
BA_ "GenSigTimeoutTime_EVCU2" SG_ 1850 HVBatCellVoltage_Cell152 0;
BA_ "GenSigTimeoutTime_IDCM" SG_ 1850 HVBatCellVoltage_Cell152 0;
BA_ "GenSigTimeoutTime_VDCM" SG_ 1850 HVBatCellVoltage_Cell153 0;
BA_ "GenSigTimeoutTime_APM2" SG_ 1850 HVBatCellVoltage_Cell153 0;
BA_ "GenSigTimeoutTime_BPCM" SG_ 1850 HVBatCellVoltage_Cell153 0;
BA_ "GenSigTimeoutTime_EVCU2" SG_ 1850 HVBatCellVoltage_Cell153 0;
BA_ "GenSigTimeoutTime_IDCM" SG_ 1850 HVBatCellVoltage_Cell153 0;
BA_ "GenSigTimeoutTime_VDCM" SG_ 1850 HVBatCellVoltage_Cell154 0;
BA_ "GenSigTimeoutTime_APM2" SG_ 1850 HVBatCellVoltage_Cell154 0;
BA_ "GenSigTimeoutTime_BPCM" SG_ 1850 HVBatCellVoltage_Cell154 0;
BA_ "GenSigTimeoutTime_EVCU2" SG_ 1850 HVBatCellVoltage_Cell154 0;
BA_ "GenSigTimeoutTime_IDCM" SG_ 1850 HVBatCellVoltage_Cell154 0;
BA_ "GenSigTimeoutTime_VDCM" SG_ 1850 HVBatCellVoltage_Cell155 0;
BA_ "GenSigTimeoutTime_APM2" SG_ 1850 HVBatCellVoltage_Cell155 0;
BA_ "GenSigTimeoutTime_BPCM" SG_ 1850 HVBatCellVoltage_Cell155 0;
BA_ "GenSigTimeoutTime_EVCU2" SG_ 1850 HVBatCellVoltage_Cell155 0;
BA_ "GenSigTimeoutTime_IDCM" SG_ 1850 HVBatCellVoltage_Cell155 0;
BA_ "GenSigTimeoutTime_VDCM" SG_ 1850 HVBatCellVoltage_Cell156 0;
BA_ "GenSigTimeoutTime_APM2" SG_ 1850 HVBatCellVoltage_Cell156 0;
BA_ "GenSigTimeoutTime_BPCM" SG_ 1850 HVBatCellVoltage_Cell156 0;
BA_ "GenSigTimeoutTime_EVCU2" SG_ 1850 HVBatCellVoltage_Cell156 0;
BA_ "GenSigTimeoutTime_IDCM" SG_ 1850 HVBatCellVoltage_Cell156 0;
BA_ "GenSigTimeoutTime_VDCM" SG_ 1850 HVBatCellVoltage_Cell157 0;
BA_ "GenSigTimeoutTime_APM2" SG_ 1850 HVBatCellVoltage_Cell157 0;
BA_ "GenSigTimeoutTime_BPCM" SG_ 1850 HVBatCellVoltage_Cell157 0;
BA_ "GenSigTimeoutTime_EVCU2" SG_ 1850 HVBatCellVoltage_Cell157 0;
BA_ "GenSigTimeoutTime_IDCM" SG_ 1850 HVBatCellVoltage_Cell157 0;
BA_ "GenSigTimeoutTime_APM2" SG_ 1850 HVBatCellVoltage_Cell158 0;
BA_ "GenSigTimeoutTime_BPCM" SG_ 1850 HVBatCellVoltage_Cell158 0;
BA_ "GenSigTimeoutTime_EVCU2" SG_ 1850 HVBatCellVoltage_Cell158 0;
BA_ "GenSigTimeoutTime_IDCM" SG_ 1850 HVBatCellVoltage_Cell158 0;
BA_ "GenSigTimeoutTime_VDCM" SG_ 1850 HVBatCellVoltage_Cell158 0;
BA_ "GenSigTimeoutTime_APM2" SG_ 1850 HVBatCellVoltage_Cell159 0;
BA_ "GenSigTimeoutTime_BPCM" SG_ 1850 HVBatCellVoltage_Cell159 0;
BA_ "GenSigTimeoutTime_EVCU2" SG_ 1850 HVBatCellVoltage_Cell159 0;
BA_ "GenSigTimeoutTime_IDCM" SG_ 1850 HVBatCellVoltage_Cell159 0;
BA_ "GenSigTimeoutTime_VDCM" SG_ 1850 HVBatCellVoltage_Cell159 0;
BA_ "GenSigTimeoutTime_APM2" SG_ 1850 HVBatCellVoltage_Cell160 0;
BA_ "GenSigTimeoutTime_BPCM" SG_ 1850 HVBatCellVoltage_Cell160 0;
BA_ "GenSigTimeoutTime_EVCU2" SG_ 1850 HVBatCellVoltage_Cell160 0;
BA_ "GenSigTimeoutTime_IDCM" SG_ 1850 HVBatCellVoltage_Cell160 0;
BA_ "GenSigTimeoutTime_VDCM" SG_ 1850 HVBatCellVoltage_Cell160 0;
BA_ "GenSigTimeoutTime_APM2" SG_ 1849 HVBatCellVoltage_Cell109 0;
BA_ "GenSigTimeoutTime_BPCM" SG_ 1849 HVBatCellVoltage_Cell109 0;
BA_ "GenSigTimeoutTime_EVCU2" SG_ 1849 HVBatCellVoltage_Cell109 0;
BA_ "GenSigTimeoutTime_IDCM" SG_ 1849 HVBatCellVoltage_Cell109 0;
BA_ "GenSigTimeoutTime_APM2" SG_ 1849 HVBatCellVoltage_Cell111 0;
BA_ "GenSigTimeoutTime_BPCM" SG_ 1849 HVBatCellVoltage_Cell111 0;
BA_ "GenSigTimeoutTime_EVCU2" SG_ 1849 HVBatCellVoltage_Cell111 0;
BA_ "GenSigTimeoutTime_IDCM" SG_ 1849 HVBatCellVoltage_Cell111 0;
BA_ "GenSigTimeoutTime_APM2" SG_ 1849 HVBatCellVoltage_Cell110 0;
BA_ "GenSigTimeoutTime_BPCM" SG_ 1849 HVBatCellVoltage_Cell110 0;
BA_ "GenSigTimeoutTime_EVCU2" SG_ 1849 HVBatCellVoltage_Cell110 0;
BA_ "GenSigTimeoutTime_IDCM" SG_ 1849 HVBatCellVoltage_Cell110 0;
BA_ "GenSigTimeoutTime_APM2" SG_ 1849 HVBatCellVoltage_Cell117 0;
BA_ "GenSigTimeoutTime_BPCM" SG_ 1849 HVBatCellVoltage_Cell117 0;
BA_ "GenSigTimeoutTime_EVCU2" SG_ 1849 HVBatCellVoltage_Cell117 0;
BA_ "GenSigTimeoutTime_IDCM" SG_ 1849 HVBatCellVoltage_Cell117 0;
BA_ "GenSigTimeoutTime_APM2" SG_ 1849 HVBatCellVoltage_Cell116 0;
BA_ "GenSigTimeoutTime_BPCM" SG_ 1849 HVBatCellVoltage_Cell116 0;
BA_ "GenSigTimeoutTime_EVCU2" SG_ 1849 HVBatCellVoltage_Cell116 0;
BA_ "GenSigTimeoutTime_IDCM" SG_ 1849 HVBatCellVoltage_Cell116 0;
BA_ "GenSigTimeoutTime_BPCM" SG_ 1849 HVBatCellVoltage_Cell115 0;
BA_ "GenSigTimeoutTime_EVCU2" SG_ 1849 HVBatCellVoltage_Cell115 0;
BA_ "GenSigTimeoutTime_IDCM" SG_ 1849 HVBatCellVoltage_Cell115 0;
BA_ "GenSigTimeoutTime_BPCM" SG_ 1850 HVBatCellVoltage_Cell162 0;
BA_ "GenSigTimeoutTime_EVCU2" SG_ 1850 HVBatCellVoltage_Cell162 0;
BA_ "GenSigTimeoutTime_IDCM" SG_ 1850 HVBatCellVoltage_Cell162 0;
BA_ "GenSigTimeoutTime_VDCM" SG_ 1851 HVBatCellVoltage_Cell163 0;
BA_ "GenSigTimeoutTime_APM2" SG_ 1851 HVBatCellVoltage_Cell163 0;
BA_ "GenSigTimeoutTime_BPCM" SG_ 1851 HVBatCellVoltage_Cell163 0;
BA_ "GenSigTimeoutTime_EVCU2" SG_ 1851 HVBatCellVoltage_Cell163 0;
BA_ "GenSigTimeoutTime_IDCM" SG_ 1851 HVBatCellVoltage_Cell163 0;
BA_ "GenSigTimeoutTime_VDCM" SG_ 1851 HVBatCellVoltage_Cell164 0;
BA_ "GenSigTimeoutTime_APM2" SG_ 1851 HVBatCellVoltage_Cell164 0;
BA_ "GenSigTimeoutTime_BPCM" SG_ 1851 HVBatCellVoltage_Cell164 0;
BA_ "GenSigTimeoutTime_EVCU2" SG_ 1851 HVBatCellVoltage_Cell164 0;
BA_ "GenSigTimeoutTime_IDCM" SG_ 1851 HVBatCellVoltage_Cell164 0;
BA_ "GenSigTimeoutTime_VDCM" SG_ 1851 HVBatCellVoltage_Cell165 0;
BA_ "GenSigTimeoutTime_APM2" SG_ 1851 HVBatCellVoltage_Cell165 0;
BA_ "GenSigTimeoutTime_BPCM" SG_ 1851 HVBatCellVoltage_Cell165 0;
BA_ "GenSigTimeoutTime_EVCU2" SG_ 1851 HVBatCellVoltage_Cell165 0;
BA_ "GenSigTimeoutTime_IDCM" SG_ 1851 HVBatCellVoltage_Cell165 0;
BA_ "GenSigTimeoutTime_VDCM" SG_ 1851 HVBatCellVoltage_Cell166 0;
BA_ "GenSigTimeoutTime_APM2" SG_ 1851 HVBatCellVoltage_Cell166 0;
BA_ "GenSigTimeoutTime_BPCM" SG_ 1851 HVBatCellVoltage_Cell166 0;
BA_ "GenSigTimeoutTime_EVCU2" SG_ 1851 HVBatCellVoltage_Cell166 0;
BA_ "GenSigTimeoutTime_IDCM" SG_ 1851 HVBatCellVoltage_Cell166 0;
BA_ "GenSigTimeoutTime_VDCM" SG_ 1851 HVBatCellVoltage_Cell167 0;
BA_ "GenSigTimeoutTime_APM2" SG_ 1851 HVBatCellVoltage_Cell167 0;
BA_ "GenSigTimeoutTime_BPCM" SG_ 1851 HVBatCellVoltage_Cell167 0;
BA_ "GenSigTimeoutTime_EVCU2" SG_ 1851 HVBatCellVoltage_Cell167 0;
BA_ "GenSigTimeoutTime_IDCM" SG_ 1851 HVBatCellVoltage_Cell167 0;
BA_ "GenSigTimeoutTime_VDCM" SG_ 1851 HVBatCellVoltage_Cell168 0;
BA_ "GenSigTimeoutTime_APM2" SG_ 1851 HVBatCellVoltage_Cell168 0;
BA_ "GenSigTimeoutTime_BPCM" SG_ 1851 HVBatCellVoltage_Cell168 0;
BA_ "GenSigTimeoutTime_EVCU2" SG_ 1851 HVBatCellVoltage_Cell168 0;
BA_ "GenSigTimeoutTime_IDCM" SG_ 1851 HVBatCellVoltage_Cell168 0;
BA_ "GenSigTimeoutTime_VDCM" SG_ 1851 HVBatCellVoltage_Cell169 0;
BA_ "GenSigTimeoutTime_APM2" SG_ 1851 HVBatCellVoltage_Cell169 0;
BA_ "GenSigTimeoutTime_BPCM" SG_ 1851 HVBatCellVoltage_Cell169 0;
BA_ "GenSigTimeoutTime_EVCU2" SG_ 1851 HVBatCellVoltage_Cell169 0;
BA_ "GenSigTimeoutTime_IDCM" SG_ 1851 HVBatCellVoltage_Cell169 0;
BA_ "GenSigTimeoutTime_VDCM" SG_ 1851 HVBatCellVoltage_Cell170 0;
BA_ "GenSigTimeoutTime_APM2" SG_ 1851 HVBatCellVoltage_Cell170 0;
BA_ "GenSigTimeoutTime_BPCM" SG_ 1851 HVBatCellVoltage_Cell170 0;
BA_ "GenSigTimeoutTime_EVCU2" SG_ 1851 HVBatCellVoltage_Cell170 0;
BA_ "GenSigTimeoutTime_IDCM" SG_ 1851 HVBatCellVoltage_Cell170 0;
BA_ "GenSigTimeoutTime_VDCM" SG_ 1851 HVBatCellVoltage_Cell171 0;
BA_ "GenSigTimeoutTime_APM2" SG_ 1851 HVBatCellVoltage_Cell171 0;
BA_ "GenSigTimeoutTime_BPCM" SG_ 1851 HVBatCellVoltage_Cell171 0;
BA_ "GenSigTimeoutTime_EVCU2" SG_ 1851 HVBatCellVoltage_Cell171 0;
BA_ "GenSigTimeoutTime_IDCM" SG_ 1851 HVBatCellVoltage_Cell171 0;
BA_ "GenSigTimeoutTime_VDCM" SG_ 1851 HVBatCellVoltage_Cell172 0;
BA_ "GenSigTimeoutTime_APM2" SG_ 1851 HVBatCellVoltage_Cell172 0;
BA_ "GenSigTimeoutTime_BPCM" SG_ 1851 HVBatCellVoltage_Cell172 0;
BA_ "GenSigTimeoutTime_EVCU2" SG_ 1851 HVBatCellVoltage_Cell172 0;
BA_ "GenSigTimeoutTime_IDCM" SG_ 1851 HVBatCellVoltage_Cell172 0;
BA_ "GenSigTimeoutTime_VDCM" SG_ 1851 HVBatCellVoltage_Cell173 0;
BA_ "GenSigTimeoutTime_APM2" SG_ 1851 HVBatCellVoltage_Cell173 0;
BA_ "GenSigTimeoutTime_BPCM" SG_ 1851 HVBatCellVoltage_Cell173 0;
BA_ "GenSigTimeoutTime_EVCU2" SG_ 1851 HVBatCellVoltage_Cell173 0;
BA_ "GenSigTimeoutTime_IDCM" SG_ 1851 HVBatCellVoltage_Cell173 0;
BA_ "GenSigTimeoutTime_VDCM" SG_ 1851 HVBatCellVoltage_Cell174 0;
BA_ "GenSigTimeoutTime_APM2" SG_ 1851 HVBatCellVoltage_Cell174 0;
BA_ "GenSigTimeoutTime_BPCM" SG_ 1851 HVBatCellVoltage_Cell174 0;
BA_ "GenSigTimeoutTime_EVCU2" SG_ 1851 HVBatCellVoltage_Cell174 0;
BA_ "GenSigTimeoutTime_IDCM" SG_ 1851 HVBatCellVoltage_Cell174 0;
BA_ "GenSigTimeoutTime_VDCM" SG_ 1851 HVBatCellVoltage_Cell175 0;
BA_ "GenSigTimeoutTime_APM2" SG_ 1851 HVBatCellVoltage_Cell175 0;
BA_ "GenSigTimeoutTime_BPCM" SG_ 1851 HVBatCellVoltage_Cell175 0;
BA_ "GenSigTimeoutTime_EVCU2" SG_ 1851 HVBatCellVoltage_Cell175 0;
BA_ "GenSigTimeoutTime_IDCM" SG_ 1851 HVBatCellVoltage_Cell175 0;
BA_ "GenSigTimeoutTime_VDCM" SG_ 1851 HVBatCellVoltage_Cell176 0;
BA_ "GenSigTimeoutTime_APM2" SG_ 1851 HVBatCellVoltage_Cell176 0;
BA_ "GenSigTimeoutTime_BPCM" SG_ 1851 HVBatCellVoltage_Cell176 0;
BA_ "GenSigTimeoutTime_EVCU2" SG_ 1851 HVBatCellVoltage_Cell176 0;
BA_ "GenSigTimeoutTime_IDCM" SG_ 1851 HVBatCellVoltage_Cell176 0;
BA_ "GenSigTimeoutTime_VDCM" SG_ 1851 HVBatCellVoltage_Cell185 0;
BA_ "GenSigTimeoutTime_APM2" SG_ 1851 HVBatCellVoltage_Cell185 0;
BA_ "GenSigTimeoutTime_BPCM" SG_ 1851 HVBatCellVoltage_Cell185 0;
BA_ "GenSigTimeoutTime_EVCU2" SG_ 1851 HVBatCellVoltage_Cell185 0;
BA_ "GenSigTimeoutTime_IDCM" SG_ 1851 HVBatCellVoltage_Cell185 0;
BA_ "GenSigTimeoutTime_SGW" SG_ 1851 HVBatCellVoltage_Cell185 0;
BA_ "GenSigTimeoutTime_VDCM" SG_ 1851 HVBatCellVoltage_Cell186 0;
BA_ "GenSigTimeoutTime_APM2" SG_ 1851 HVBatCellVoltage_Cell186 0;
BA_ "GenSigTimeoutTime_BPCM" SG_ 1851 HVBatCellVoltage_Cell186 0;
BA_ "GenSigTimeoutTime_EVCU2" SG_ 1851 HVBatCellVoltage_Cell186 0;
BA_ "GenSigTimeoutTime_IDCM" SG_ 1851 HVBatCellVoltage_Cell186 0;
BA_ "GenSigTimeoutTime_SGW" SG_ 1851 HVBatCellVoltage_Cell186 0;
BA_ "GenSigTimeoutTime_VDCM" SG_ 1851 HVBatCellVoltage_Cell187 0;
BA_ "GenSigTimeoutTime_APM2" SG_ 1851 HVBatCellVoltage_Cell187 0;
BA_ "GenSigTimeoutTime_BPCM" SG_ 1851 HVBatCellVoltage_Cell187 0;
BA_ "GenSigTimeoutTime_EVCU2" SG_ 1851 HVBatCellVoltage_Cell187 0;
BA_ "GenSigTimeoutTime_IDCM" SG_ 1851 HVBatCellVoltage_Cell187 0;
BA_ "GenSigTimeoutTime_SGW" SG_ 1851 HVBatCellVoltage_Cell187 0;
BA_ "GenSigTimeoutTime_VDCM" SG_ 1851 HVBatCellVoltage_Cell188 0;
BA_ "GenSigTimeoutTime_APM2" SG_ 1851 HVBatCellVoltage_Cell188 0;
BA_ "GenSigTimeoutTime_BPCM" SG_ 1851 HVBatCellVoltage_Cell188 0;
BA_ "GenSigTimeoutTime_EVCU2" SG_ 1851 HVBatCellVoltage_Cell188 0;
BA_ "GenSigTimeoutTime_IDCM" SG_ 1851 HVBatCellVoltage_Cell188 0;
BA_ "GenSigTimeoutTime_SGW" SG_ 1851 HVBatCellVoltage_Cell188 0;
BA_ "GenSigTimeoutTime_VDCM" SG_ 1851 HVBatCellVoltage_Cell189 0;
BA_ "GenSigTimeoutTime_APM2" SG_ 1851 HVBatCellVoltage_Cell189 0;
BA_ "GenSigTimeoutTime_BPCM" SG_ 1851 HVBatCellVoltage_Cell189 0;
BA_ "GenSigTimeoutTime_EVCU2" SG_ 1851 HVBatCellVoltage_Cell189 0;
BA_ "GenSigTimeoutTime_IDCM" SG_ 1851 HVBatCellVoltage_Cell189 0;
BA_ "GenSigTimeoutTime_SGW" SG_ 1851 HVBatCellVoltage_Cell189 0;
BA_ "GenSigTimeoutTime_VDCM" SG_ 1852 HVBatCellVoltage_Cell190 0;
BA_ "GenSigTimeoutTime_VDCM" SG_ 1852 HVBatCellVoltage_Cell191 0;
BA_ "GenSigTimeoutTime_VDCM" SG_ 1852 HVBatCellVoltage_Cell192 0;
BA_ "GenSigTimeoutTime_VDCM" SG_ 1851 HVBatCellVoltage_Cell181 0;
BA_ "GenSigTimeoutTime_APM2" SG_ 1851 HVBatCellVoltage_Cell181 0;
BA_ "GenSigTimeoutTime_BPCM" SG_ 1851 HVBatCellVoltage_Cell181 0;
BA_ "GenSigTimeoutTime_EVCU2" SG_ 1851 HVBatCellVoltage_Cell181 0;
BA_ "GenSigTimeoutTime_IDCM" SG_ 1851 HVBatCellVoltage_Cell181 0;
BA_ "GenSigTimeoutTime_VDCM" SG_ 1851 HVBatCellVoltage_Cell182 0;
BA_ "GenSigTimeoutTime_APM2" SG_ 1851 HVBatCellVoltage_Cell182 0;
BA_ "GenSigTimeoutTime_BPCM" SG_ 1851 HVBatCellVoltage_Cell182 0;
BA_ "GenSigTimeoutTime_EVCU2" SG_ 1851 HVBatCellVoltage_Cell182 0;
BA_ "GenSigTimeoutTime_IDCM" SG_ 1851 HVBatCellVoltage_Cell182 0;
BA_ "GenSigTimeoutTime_VDCM" SG_ 1851 HVBatCellVoltage_Cell183 0;
BA_ "GenSigTimeoutTime_APM2" SG_ 1851 HVBatCellVoltage_Cell183 0;
BA_ "GenSigTimeoutTime_BPCM" SG_ 1851 HVBatCellVoltage_Cell183 0;
BA_ "GenSigTimeoutTime_EVCU2" SG_ 1851 HVBatCellVoltage_Cell183 0;
BA_ "GenSigTimeoutTime_IDCM" SG_ 1851 HVBatCellVoltage_Cell183 0;
BA_ "GenSigTimeoutTime_VDCM" SG_ 1851 HVBatCellVoltage_Cell184 0;
BA_ "GenSigTimeoutTime_APM2" SG_ 1851 HVBatCellVoltage_Cell184 0;
BA_ "GenSigTimeoutTime_BPCM" SG_ 1851 HVBatCellVoltage_Cell184 0;
BA_ "GenSigTimeoutTime_EVCU2" SG_ 1851 HVBatCellVoltage_Cell184 0;
BA_ "GenSigTimeoutTime_IDCM" SG_ 1851 HVBatCellVoltage_Cell184 0;
BA_ "GenSigTimeoutTime_SGW" SG_ 1851 HVBatCellVoltage_Cell184 0;
BA_ "GenSigTimeoutTime_VDCM" SG_ 1851 HVBatCellVoltage_Cell179 0;
BA_ "GenSigTimeoutTime_APM2" SG_ 1851 HVBatCellVoltage_Cell179 0;
BA_ "GenSigTimeoutTime_BPCM" SG_ 1851 HVBatCellVoltage_Cell179 0;
BA_ "GenSigTimeoutTime_EVCU2" SG_ 1851 HVBatCellVoltage_Cell179 0;
BA_ "GenSigTimeoutTime_IDCM" SG_ 1851 HVBatCellVoltage_Cell179 0;
BA_ "GenSigTimeoutTime_VDCM" SG_ 1851 HVBatCellVoltage_Cell180 0;
BA_ "GenSigTimeoutTime_APM2" SG_ 1851 HVBatCellVoltage_Cell180 0;
BA_ "GenSigTimeoutTime_BPCM" SG_ 1851 HVBatCellVoltage_Cell180 0;
BA_ "GenSigTimeoutTime_EVCU2" SG_ 1851 HVBatCellVoltage_Cell180 0;
BA_ "GenSigTimeoutTime_IDCM" SG_ 1851 HVBatCellVoltage_Cell180 0;
BA_ "GenSigTimeoutTime_VDCM" SG_ 1851 HVBatCellVoltage_Cell178 0;
BA_ "GenSigTimeoutTime_APM2" SG_ 1851 HVBatCellVoltage_Cell178 0;
BA_ "GenSigTimeoutTime_BPCM" SG_ 1851 HVBatCellVoltage_Cell178 0;
BA_ "GenSigTimeoutTime_EVCU2" SG_ 1851 HVBatCellVoltage_Cell178 0;
BA_ "GenSigTimeoutTime_IDCM" SG_ 1851 HVBatCellVoltage_Cell178 0;
BA_ "GenSigTimeoutTime_VDCM" SG_ 1851 HVBatCellVoltage_Cell177 0;
BA_ "GenSigTimeoutTime_APM2" SG_ 1851 HVBatCellVoltage_Cell177 0;
BA_ "GenSigTimeoutTime_BPCM" SG_ 1851 HVBatCellVoltage_Cell177 0;
BA_ "GenSigTimeoutTime_EVCU2" SG_ 1851 HVBatCellVoltage_Cell177 0;
BA_ "GenSigTimeoutTime_IDCM" SG_ 1851 HVBatCellVoltage_Cell177 0;
BA_ "GenSigTimeoutTime_VDCM" SG_ 1852 HVBatCellVoltage_Cell216 0;
BA_ "GenSigTimeoutTime_EVCU2" SG_ 1852 HVBatCellVoltage_Cell208 0;
BA_ "GenSigTimeoutTime_IDCM" SG_ 1852 HVBatCellVoltage_Cell208 0;
BA_ "GenSigTimeoutTime_SGW" SG_ 1852 HVBatCellVoltage_Cell208 0;
BA_ "GenSigTimeoutTime_VDCM" SG_ 1852 HVBatCellVoltage_Cell208 0;
BA_ "GenSigTimeoutTime_APM2" SG_ 1852 HVBatCellVoltage_Cell208 0;
BA_ "GenSigTimeoutTime_BPCM" SG_ 1852 HVBatCellVoltage_Cell208 0;
BA_ "GenSigTimeoutTime_APM2" SG_ 1852 HVBatCellVoltage_Cell209 0;
BA_ "GenSigTimeoutTime_BPCM" SG_ 1852 HVBatCellVoltage_Cell209 0;
BA_ "GenSigTimeoutTime_EVCU2" SG_ 1852 HVBatCellVoltage_Cell209 0;
BA_ "GenSigTimeoutTime_IDCM" SG_ 1852 HVBatCellVoltage_Cell209 0;
BA_ "GenSigTimeoutTime_SGW" SG_ 1852 HVBatCellVoltage_Cell209 0;
BA_ "GenSigTimeoutTime_VDCM" SG_ 1852 HVBatCellVoltage_Cell209 0;
BA_ "GenSigTimeoutTime_APM2" SG_ 1852 HVBatCellVoltage_Cell210 0;
BA_ "GenSigTimeoutTime_BPCM" SG_ 1852 HVBatCellVoltage_Cell210 0;
BA_ "GenSigTimeoutTime_EVCU2" SG_ 1852 HVBatCellVoltage_Cell210 0;
BA_ "GenSigTimeoutTime_IDCM" SG_ 1852 HVBatCellVoltage_Cell210 0;
BA_ "GenSigTimeoutTime_SGW" SG_ 1852 HVBatCellVoltage_Cell210 0;
BA_ "GenSigTimeoutTime_VDCM" SG_ 1852 HVBatCellVoltage_Cell210 0;
BA_ "GenSigTimeoutTime_APM2" SG_ 1852 HVBatCellVoltage_Cell211 0;
BA_ "GenSigTimeoutTime_BPCM" SG_ 1852 HVBatCellVoltage_Cell211 0;
BA_ "GenSigTimeoutTime_EVCU2" SG_ 1852 HVBatCellVoltage_Cell211 0;
BA_ "GenSigTimeoutTime_IDCM" SG_ 1852 HVBatCellVoltage_Cell211 0;
BA_ "GenSigTimeoutTime_SGW" SG_ 1852 HVBatCellVoltage_Cell211 0;
BA_ "GenSigTimeoutTime_VDCM" SG_ 1852 HVBatCellVoltage_Cell211 0;
BA_ "GenSigTimeoutTime_APM2" SG_ 1852 HVBatCellVoltage_Cell212 0;
BA_ "GenSigTimeoutTime_BPCM" SG_ 1852 HVBatCellVoltage_Cell212 0;
BA_ "GenSigTimeoutTime_EVCU2" SG_ 1852 HVBatCellVoltage_Cell212 0;
BA_ "GenSigTimeoutTime_IDCM" SG_ 1852 HVBatCellVoltage_Cell212 0;
BA_ "GenSigTimeoutTime_SGW" SG_ 1852 HVBatCellVoltage_Cell212 0;
BA_ "GenSigTimeoutTime_VDCM" SG_ 1852 HVBatCellVoltage_Cell212 0;
BA_ "GenSigTimeoutTime_APM2" SG_ 1852 HVBatCellVoltage_Cell213 0;
BA_ "GenSigTimeoutTime_BPCM" SG_ 1852 HVBatCellVoltage_Cell213 0;
BA_ "GenSigTimeoutTime_VDCM" SG_ 1852 HVBatCellVoltage_Cell213 0;
BA_ "GenSigTimeoutTime_VDCM" SG_ 1852 HVBatCellVoltage_Cell214 0;
BA_ "GenSigTimeoutTime_VDCM" SG_ 1852 HVBatCellVoltage_Cell215 0;
BA_ "GenSigTimeoutTime_VDCM" SG_ 1852 HVBatCellVoltage_Cell193 0;
BA_ "GenSigTimeoutTime_VDCM" SG_ 1852 HVBatCellVoltage_Cell194 0;
BA_ "GenSigTimeoutTime_VDCM" SG_ 1852 HVBatCellVoltage_Cell195 0;
BA_ "GenSigTimeoutTime_VDCM" SG_ 1852 HVBatCellVoltage_Cell196 0;
BA_ "GenSigTimeoutTime_VDCM" SG_ 1852 HVBatCellVoltage_Cell197 0;
BA_ "GenSigTimeoutTime_VDCM" SG_ 1852 HVBatCellVoltage_Cell198 0;
BA_ "GenSigTimeoutTime_VDCM" SG_ 1852 HVBatCellVoltage_Cell200 0;
BA_ "GenSigTimeoutTime_VDCM" SG_ 1852 HVBatCellVoltage_Cell201 0;
BA_ "GenSigTimeoutTime_VDCM" SG_ 1852 HVBatCellVoltage_Cell202 0;
BA_ "GenSigTimeoutTime_VDCM" SG_ 1852 HVBatCellVoltage_Cell203 0;
BA_ "GenSigTimeoutTime_VDCM" SG_ 1852 HVBatCellVoltage_Cell204 0;
BA_ "GenSigTimeoutTime_VDCM" SG_ 1852 HVBatCellVoltage_Cell205 0;
BA_ "GenSigTimeoutTime_VDCM" SG_ 1852 HVBatCellVoltage_Cell206 0;
BA_ "GenSigTimeoutTime_VDCM" SG_ 1852 HVBatCellVoltage_Cell207 0;
BA_ "GenSigTimeoutTime_APM2" SG_ 1852 HVBatCellVoltage_Cell207 0;
BA_ "GenSigTimeoutTime_BPCM" SG_ 1852 HVBatCellVoltage_Cell207 0;
BA_ "GenSigTimeoutTime_EVCU2" SG_ 1852 HVBatCellVoltage_Cell207 0;
BA_ "GenSigTimeoutTime_IDCM" SG_ 1852 HVBatCellVoltage_Cell207 0;
BA_ "GenSigTimeoutTime_SGW" SG_ 1852 HVBatCellVoltage_Cell207 0;
BA_ "GenSigTimeoutTime_APM2" SG_ 1852 HVBatCellVoltage_Cell206 0;
BA_ "GenSigTimeoutTime_BPCM" SG_ 1852 HVBatCellVoltage_Cell206 0;
BA_ "GenSigTimeoutTime_EVCU2" SG_ 1852 HVBatCellVoltage_Cell206 0;
BA_ "GenSigTimeoutTime_IDCM" SG_ 1852 HVBatCellVoltage_Cell206 0;
BA_ "GenSigTimeoutTime_SGW" SG_ 1852 HVBatCellVoltage_Cell206 0;
BA_ "GenSigTimeoutTime_APM2" SG_ 1852 HVBatCellVoltage_Cell205 0;
BA_ "GenSigTimeoutTime_BPCM" SG_ 1852 HVBatCellVoltage_Cell205 0;
BA_ "GenSigTimeoutTime_EVCU2" SG_ 1852 HVBatCellVoltage_Cell205 0;
BA_ "GenSigTimeoutTime_IDCM" SG_ 1852 HVBatCellVoltage_Cell205 0;
BA_ "GenSigTimeoutTime_SGW" SG_ 1852 HVBatCellVoltage_Cell205 0;
BA_ "GenSigTimeoutTime_APM2" SG_ 1852 HVBatCellVoltage_Cell204 0;
BA_ "GenSigTimeoutTime_BPCM" SG_ 1852 HVBatCellVoltage_Cell204 0;
BA_ "GenSigTimeoutTime_EVCU2" SG_ 1852 HVBatCellVoltage_Cell204 0;
BA_ "GenSigTimeoutTime_IDCM" SG_ 1852 HVBatCellVoltage_Cell204 0;
BA_ "GenSigTimeoutTime_SGW" SG_ 1852 HVBatCellVoltage_Cell204 0;
BA_ "GenSigTimeoutTime_APM2" SG_ 1852 HVBatCellVoltage_Cell203 0;
BA_ "GenSigTimeoutTime_BPCM" SG_ 1852 HVBatCellVoltage_Cell203 0;
BA_ "GenSigTimeoutTime_EVCU2" SG_ 1852 HVBatCellVoltage_Cell203 0;
BA_ "GenSigTimeoutTime_IDCM" SG_ 1852 HVBatCellVoltage_Cell203 0;
BA_ "GenSigTimeoutTime_SGW" SG_ 1852 HVBatCellVoltage_Cell203 0;
BA_ "GenSigTimeoutTime_APM2" SG_ 1852 HVBatCellVoltage_Cell202 0;
BA_ "GenSigTimeoutTime_BPCM" SG_ 1852 HVBatCellVoltage_Cell202 0;
BA_ "GenSigTimeoutTime_EVCU2" SG_ 1852 HVBatCellVoltage_Cell202 0;
BA_ "GenSigTimeoutTime_IDCM" SG_ 1852 HVBatCellVoltage_Cell202 0;
BA_ "GenSigTimeoutTime_SGW" SG_ 1852 HVBatCellVoltage_Cell202 0;
BA_ "GenSigTimeoutTime_APM2" SG_ 1852 HVBatCellVoltage_Cell201 0;
BA_ "GenSigTimeoutTime_BPCM" SG_ 1852 HVBatCellVoltage_Cell201 0;
BA_ "GenSigTimeoutTime_EVCU2" SG_ 1852 HVBatCellVoltage_Cell201 0;
BA_ "GenSigTimeoutTime_IDCM" SG_ 1852 HVBatCellVoltage_Cell201 0;
BA_ "GenSigTimeoutTime_SGW" SG_ 1852 HVBatCellVoltage_Cell201 0;
BA_ "GenSigTimeoutTime_APM2" SG_ 1852 HVBatCellVoltage_Cell200 0;
BA_ "GenSigTimeoutTime_BPCM" SG_ 1852 HVBatCellVoltage_Cell200 0;
BA_ "GenSigTimeoutTime_EVCU2" SG_ 1852 HVBatCellVoltage_Cell200 0;
BA_ "GenSigTimeoutTime_IDCM" SG_ 1852 HVBatCellVoltage_Cell200 0;
BA_ "GenSigTimeoutTime_SGW" SG_ 1852 HVBatCellVoltage_Cell200 0;
BA_ "GenSigTimeoutTime_APM2" SG_ 1852 HVBatCellVoltage_Cell198 0;
BA_ "GenSigTimeoutTime_BPCM" SG_ 1852 HVBatCellVoltage_Cell198 0;
BA_ "GenSigTimeoutTime_EVCU2" SG_ 1852 HVBatCellVoltage_Cell198 0;
BA_ "GenSigTimeoutTime_IDCM" SG_ 1852 HVBatCellVoltage_Cell198 0;
BA_ "GenSigTimeoutTime_SGW" SG_ 1852 HVBatCellVoltage_Cell198 0;
BA_ "GenSigTimeoutTime_APM2" SG_ 1852 HVBatCellVoltage_Cell197 0;
BA_ "GenSigTimeoutTime_BPCM" SG_ 1852 HVBatCellVoltage_Cell197 0;
BA_ "GenSigTimeoutTime_EVCU2" SG_ 1852 HVBatCellVoltage_Cell197 0;
BA_ "GenSigTimeoutTime_IDCM" SG_ 1852 HVBatCellVoltage_Cell197 0;
BA_ "GenSigTimeoutTime_SGW" SG_ 1852 HVBatCellVoltage_Cell197 0;
BA_ "GenSigTimeoutTime_APM2" SG_ 1852 HVBatCellVoltage_Cell196 0;
BA_ "GenSigTimeoutTime_BPCM" SG_ 1852 HVBatCellVoltage_Cell196 0;
BA_ "GenSigTimeoutTime_EVCU2" SG_ 1852 HVBatCellVoltage_Cell196 0;
BA_ "GenSigTimeoutTime_IDCM" SG_ 1852 HVBatCellVoltage_Cell196 0;
BA_ "GenSigTimeoutTime_SGW" SG_ 1852 HVBatCellVoltage_Cell196 0;
BA_ "GenSigTimeoutTime_APM2" SG_ 1852 HVBatCellVoltage_Cell195 0;
BA_ "GenSigTimeoutTime_BPCM" SG_ 1852 HVBatCellVoltage_Cell195 0;
BA_ "GenSigTimeoutTime_EVCU2" SG_ 1852 HVBatCellVoltage_Cell195 0;
BA_ "GenSigTimeoutTime_IDCM" SG_ 1852 HVBatCellVoltage_Cell195 0;
BA_ "GenSigTimeoutTime_SGW" SG_ 1852 HVBatCellVoltage_Cell195 0;
BA_ "GenSigTimeoutTime_APM2" SG_ 1852 HVBatCellVoltage_Cell194 0;
BA_ "GenSigTimeoutTime_BPCM" SG_ 1852 HVBatCellVoltage_Cell194 0;
VAL_ 1849 HVBatCellVoltage_Cell117 8191 "SNA";
VAL_ 1849 HVBatCellVoltage_Cell116 8191 "SNA";
VAL_ 1849 HVBatCellVoltage_Cell115 8191 "SNA";
VAL_ 1849 HVBatCellVoltage_Cell114 8191 "SNA";
VAL_ 1849 HVBatCellVoltage_Cell113 8191 "SNA";
VAL_ 1849 HVBatCellVoltage_Cell112 8191 "SNA";
VAL_ 1849 HVBatCellVoltage_Cell111 8191 "SNA";
VAL_ 1849 HVBatCellVoltage_Cell110 8191 "SNA";
VAL_ 1849 HVBatCellVoltage_Cell109 8191 "SNA";
VAL_ 1852 HVBatCellVoltage_Cell192 8191 "SNA";
VAL_ 1852 HVBatCellVoltage_Cell191 8191 "SNA";
VAL_ 1852 HVBatCellVoltage_Cell190 8191 "SNA";
VAL_ 1851 HVBatCellVoltage_Cell189 8191 "SNA";
VAL_ 1851 HVBatCellVoltage_Cell188 8191 "SNA";
VAL_ 1851 HVBatCellVoltage_Cell187 8191 "SNA";
VAL_ 1851 HVBatCellVoltage_Cell186 8191 "SNA";
VAL_ 1851 HVBatCellVoltage_Cell185 8191 "SNA";
VAL_ 1851 HVBatCellVoltage_Cell184 8191 "SNA";
VAL_ 1851 HVBatCellVoltage_Cell183 8191 "SNA";
VAL_ 1851 HVBatCellVoltage_Cell182 8191 "SNA";
VAL_ 1851 HVBatCellVoltage_Cell181 8191 "SNA";
VAL_ 1851 HVBatCellVoltage_Cell180 8191 "SNA";
VAL_ 1851 HVBatCellVoltage_Cell179 8191 "SNA";
VAL_ 1851 HVBatCellVoltage_Cell178 8191 "SNA";
VAL_ 1851 HVBatCellVoltage_Cell177 8191 "SNA";
VAL_ 1851 HVBatCellVoltage_Cell176 8191 "SNA";
VAL_ 1851 HVBatCellVoltage_Cell175 8191 "SNA";
VAL_ 1851 HVBatCellVoltage_Cell174 8191 "SNA";
VAL_ 1851 HVBatCellVoltage_Cell173 8191 "SNA";
VAL_ 1851 HVBatCellVoltage_Cell172 8191 "SNA";
VAL_ 1851 HVBatCellVoltage_Cell171 8191 "SNA";
VAL_ 1851 HVBatCellVoltage_Cell170 8191 "SNA";
VAL_ 1851 HVBatCellVoltage_Cell169 8191 "SNA";
VAL_ 1851 HVBatCellVoltage_Cell168 8191 "SNA";
VAL_ 1851 HVBatCellVoltage_Cell167 8191 "SNA";
VAL_ 1851 HVBatCellVoltage_Cell166 8191 "SNA";
VAL_ 1851 HVBatCellVoltage_Cell165 8191 "SNA";
VAL_ 1851 HVBatCellVoltage_Cell164 8191 "SNA";
VAL_ 1851 HVBatCellVoltage_Cell163 8191 "SNA";
VAL_ 1850 HVBatCellVoltage_Cell162 8191 "SNA";
VAL_ 1850 HVBatCellVoltage_Cell161 8191 "SNA";
VAL_ 1850 HVBatCellVoltage_Cell160 8191 "SNA";
VAL_ 1850 HVBatCellVoltage_Cell159 8191 "SNA";
VAL_ 1850 HVBatCellVoltage_Cell158 8191 "SNA";
VAL_ 1850 HVBatCellVoltage_Cell157 8191 "SNA";
VAL_ 1850 HVBatCellVoltage_Cell156 8191 "SNA";
VAL_ 1850 HVBatCellVoltage_Cell155 8191 "SNA";
VAL_ 1850 HVBatCellVoltage_Cell154 8191 "SNA";
VAL_ 1850 HVBatCellVoltage_Cell153 8191 "SNA";
VAL_ 1850 HVBatCellVoltage_Cell152 8191 "SNA";
VAL_ 1850 HVBatCellVoltage_Cell151 8191 "SNA";
VAL_ 1850 HVBatCellVoltage_Cell150 8191 "SNA";
VAL_ 1850 HVBatCellVoltage_Cell149 8191 "SNA";
VAL_ 1850 HVBatCellVoltage_Cell148 8191 "SNA";
VAL_ 1850 HVBatCellVoltage_Cell147 8191 "SNA";
VAL_ 1850 HVBatCellVoltage_Cell146 8191 "SNA";
VAL_ 1850 HVBatCellVoltage_Cell145 8191 "SNA";
VAL_ 1850 HVBatCellVoltage_Cell144 8191 "SNA";
VAL_ 1850 HVBatCellVoltage_Cell143 8191 "SNA";
VAL_ 1850 HVBatCellVoltage_Cell142 8191 "SNA";
VAL_ 1850 HVBatCellVoltage_Cell141 8191 "SNA";
VAL_ 1850 HVBatCellVoltage_Cell140 8191 "SNA";
VAL_ 1850 HVBatCellVoltage_Cell139 8191 "SNA";
VAL_ 1850 HVBatCellVoltage_Cell138 8191 "SNA";
VAL_ 1850 HVBatCellVoltage_Cell137 8191 "SNA";
VAL_ 1850 HVBatCellVoltage_Cell136 8191 "SNA";
VAL_ 1849 HVBatCellVoltage_Cell135 8191 "SNA";
VAL_ 1849 HVBatCellVoltage_Cell134 8191 "SNA";
VAL_ 1849 HVBatCellVoltage_Cell133 8191 "SNA";
VAL_ 1849 HVBatCellVoltage_Cell132 8191 "SNA";
VAL_ 1849 HVBatCellVoltage_Cell131 8191 "SNA";
VAL_ 1849 HVBatCellVoltage_Cell130 8191 "SNA";
VAL_ 1849 HVBatCellVoltage_Cell129 8191 "SNA";
VAL_ 1849 HVBatCellVoltage_Cell128 8191 "SNA";
VAL_ 1849 HVBatCellVoltage_Cell127 8191 "SNA";
VAL_ 1849 HVBatCellVoltage_Cell126 8191 "SNA";
VAL_ 1849 HVBatCellVoltage_Cell125 8191 "SNA";
VAL_ 1849 HVBatCellVoltage_Cell124 8191 "SNA";
VAL_ 1849 HVBatCellVoltage_Cell123 8191 "SNA";
VAL_ 1849 HVBatCellVoltage_Cell122 8191 "SNA";
VAL_ 1849 HVBatCellVoltage_Cell121 8191 "SNA";
VAL_ 1849 HVBatCellVoltage_Cell120 8191 "SNA";
VAL_ 1849 HVBatCellVoltage_Cell119 8191 "SNA";
VAL_ 1849 HVBatCellVoltage_Cell118 8191 "SNA";
VAL_ 502 HVCMS_ServiceScope 65535 "SNA";
VAL_ 502 HVCMS_ReadyToChargeState 0 "Not_Ready" 1 "Ready";
VAL_ 502 HVCMS_Protocol_Entry3 65535 "SNA";
VAL_ 502 HVCMS_Protocol_Entry2 65535 "SNA";
VAL_ 502 HVCMS_Protocol_Entry1 65535 "SNA";
VAL_ 502 HVCMS_EVTargetVoltage 16383 "SNA";
VAL_ 502 HVCMS_EVTargetCurrent 1023 "SNA";
VAL_ 502 HVCMS_EVRESS_SOC 4095 "SNA";
VAL_ 502 HVCMS_EVReady 0 "Not_Ready" 1 "Ready";
VAL_ 502 HVCMS_EVMax_V_Limit 16383 "SNA";
VAL_ 502 HVCMS_EVMax_P_Limit 16777215 "SNA";
VAL_ 502 HVCMS_EVMax_I_Limit 1023 "SNA";
VAL_ 502 HVCMS_EVEnergyCapacity 131071 "SNA";
VAL_ 502 HVCMS_ChargingComplete 0 "Not_Completed" 1 "Completed";
VAL_ 502 HVCMS_BulkChargingComplete 0 "Not_Completed" 1 "Completed";
VAL_ 498 HVCMS_EVSEPresentVoltage 16383 "SNA";
VAL_ 498 HVCMS_EVSEPeakCurrentRipple 1023 "SNA";
VAL_ 498 HVCMS_EVSEMinCurrentLimit 1023 "SNA";
VAL_ 498 HVCMS_EVSEMaxPowerLimit 16777215 "SNA";
VAL_ 498 HVCMS_EVSEMaxCurrentLimit 1023 "SNA";
VAL_ 498 HVCMS_EVSECurrRegulationTol 1023 "SNA";
VAL_ 498 HVCMS_EnergyToBeDelivered 131071 "SNA";
VAL_ 498 EVSE_IsolationSts 0 "GFD_Not_Performed" 1 "GFD_Ok" 2 "GFD_Fail" 3 "GFD_Invalid" 4 "GFD_Warning" 7 "SNA";
VAL_ 498 DC_TimeOut 0 "FALSE" 1 "TRUE";
VAL_ 498 DC_Isolation_Disable_Cmd 0 "FALSE" 1 "TRUE";
VAL_ 244 BMS_HV_Trac_PreCha_Contac_Sts 0 "Open" 1 "Closed" 3 "Error_Stuck_Open" 4 "Error_Stuck_Closed" 7 "SNA";
VAL_ 244 BMS_HV_Trac_Main_Contac_Sts 0 "Open" 1 "Closed" 3 "Error_Stuck_Open" 4 "Error_Stuck_Closed" 7 "SNA";
VAL_ 244 BMS_HV_SOC 1023 "SNA";
VAL_ 244 BMS_HV_Current 32767 "SNA";
VAL_ 244 BMS_HV_Char_PreCha_Contac_Sts 0 "Open" 1 "Closed" 3 "Error_Stuck_Open" 4 "Error_Stuck_Closed" 7 "SNA";
VAL_ 244 BMS_HV_Char_Main_Contac_Sts 0 "Open" 1 "Closed" 3 "Error_Stuck_Open" 4 "Error_Stuck_Closed" 7 "SNA";
VAL_ 244 BMS_HV_Capacity_Vldty 0 "Valid" 1 "Not_Valid";
VAL_ 244 BMS_HV_Battery_GFD_Sts 0 "GFD_Not_Performed" 1 "GFD_OK" 2 "GFD_Fail" 3 "GFD_INVALID_meas_noise" 4 "Disabled";
VAL_ 252 BMS_HV_Current_MaxDischrg_MdTrm 16383 "SNA";
VAL_ 252 BMS_HV_Current_MaxDischrg_LgTrm 16383 "SNA";
VAL_ 252 BMS_HV_Current_Discharge_ShrTrm 16383 "SNA";
VAL_ 252 BMS_CntctrsShtTrmOpeningWarn 0 "FALSE" 1 "TRUE";
VAL_ 252 BMS_CntctrsMidTrmOpeningWarn 0 "FALSE" 1 "TRUE";
VAL_ 500 BMS_HV_NumCellMinTemp 511 "SNA";
VAL_ 500 BMS_HV_NumCellMaxTemp 511 "SNA";
VAL_ 500 BMS_Cell_Volt_Min_Vldty 0 "Valid" 1 "Not_Valid";
VAL_ 500 BMS_Cell_Volt_Min 8191 "SNA";
VAL_ 500 BMS_Cell_Volt_Max_Vldty 0 "Valid" 1 "Not_Valid";
VAL_ 500 BMS_Cell_Volt_Max 8191 "SNA";
VAL_ 250 APM_Water_Temp 255 "SNA";
VAL_ 250 APM_RecoveryAction 1 "APM_Not_working" 2 "APM_safe_state" 3 "APM_safe_state_and_not_working" 4 "APM_voltage_control_mode" 5 "APM_wake_up_loss" 6 "APM_safe_state_and_voltage_control_mode" 8 "Wake_up_loss" 16 "Eeprom_loss";
VAL_ 250 APM_PSFB_Temp2 4095 "SNA";
VAL_ 250 APM_PSFB_Temp1 4095 "SNA";
VAL_ 250 APM_LV_V_Fbk 4095 "SNA";
VAL_ 250 APM_LV_I_Fbk 4095 "SNA";
VAL_ 250 APM_HV_V_Fbk 4095 "SNA";
VAL_ 250 APM_HV_I_Fbk 4095 "SNA";
VAL_ 250 APM_Buck_Temp 4095 "SNA";
VAL_ 502 VDCM_TypeCNegotiationSts 0 "Not_Requested" 1 "Ongoing" 2 "OK" 3 "Not_OK";
VAL_ 502 HVCMS_EVEnergyRequest 131071 "SNA";
VAL_ 498 OBCM_PLCTypeSts 0 "Not determinated" 1 "Basic signaling communication" 2 "HLC" 7 "SNA";
VAL_ 498 HVCMS_EVSEVoltageLimitAchieved 0 "No_limit_ach" 1 "Limit_ach" 2 "Init" 3 "SNA";
VAL_ 498 HVCMS_EVSEPowerLimitAchieved 0 "No_limit_ach" 1 "Limit_ach" 2 "Init" 3 "SNA";
VAL_ 498 HVCMS_EVSEMinimumVoltageLimit 65535 "SNA";
VAL_ 498 HVCMS_EVSEMaximumVoltageLimit 65535 "SNA";
VAL_ 498 HVCMS_EVSECurrentLimitAchieved 0 "No_limit_ach" 1 "Limit_ach" 2 "Init" 3 "SNA";
VAL_ 244 BPCM_Comm_Fail_CAN 0 "No_Fault" 1 "BPCM_LOC_MCPB" 2 "BPCM_LOC_MCPC" 3 "BPCM_LOC_MCPA" 4 "BPCM_LOC_MCPB_MCPC" 5 "BPCM_LOC_MCPA_MCPB" 6 "BPCM_LOC_MCPA_MCPC" 7 "BPCM_LOC_MCPA_MCPB_MCPC" 8 "BPCM_LOC_VDCM" 14 "BPCM_Bus_Failure_CAN" 15 "SNA";
VAL_ 244 BMS_HV_Trac_Bus_Sts 0 "OPEN" 1 "CLOSED" 2 "PRECHARGING" 3 "PRECHARGING FAILED" 4 "PRECHARGING INHIBITED" 7 "SNA";
VAL_ 502 OBCM_OutVoltageSyncTgt 1023 "SNA";
VAL_ 498 HVCMS_EVSEPresentCurrent 65535 "SNA";
VAL_ 498 EVSE_OfferedEnergyTransferType 0 "NotAvailable" 1 "AC_single_phase_core" 2 "AC_three_phase_core" 3 "DC_core" 4 "DC_extended" 5 "DC_combo_core" 6 "DC_unique";
VAL_ 244 BMS_HV_Temperature_Min 2047 "SNA";
VAL_ 244 BMS_HV_Temperature_Max 2047 "SNA";
VAL_ 244 BMS_HV_Temperature_Avg 2047 "SNA";
VAL_ 244 BMS_HV_SOH_Vldty 0 "Valid" 1 "Not_Valid";
VAL_ 244 BMS_HV_AC_Char_Main_Contac_Sts 0 "Open" 1 "Closed" 3 "Error_Stuck_Open" 4 "Error_Stuck_Closed" 7 "SNA";
VAL_ 250 APM_UtilPctOfDCDC 127 "SNA";
VAL_ 250 APM_TempColdPlate 254 "Failure" 255 "SNA";
VAL_ 250 APM_OutputPower 1023 "SNA";
VAL_ 250 APM_InputPower 1023 "SNA";
VAL_ 250 APM_IdcHvSetPFdbk 1023 "SNA";
VAL_ 250 APM_HvVsetPFdbk 511 "SNA";
VAL_ 250 APM_FailureType 0 "No_failure" 1 "Failure_chargingInhibited" 2 "Failure_chargingAllowed" 3 "SNA";
VAL_ 250 APM_FailureReason 0 "No_Failure" 1 "Fail_high_voltage_at_HV" 2 "Fail_low_voltage_at_HV" 3 "Fail_high_voltage_at_LV" 4 "Fail_low_voltage_at_LV" 5 "Fail_high_PCB_temperature" 6 "Fail_high_DCB_temperature" 7 "Fail_high_cur_at_LV" 8 "Fail_high_cur_at_HV" 9 "Fail_short_circ_at_LV" 10 "Fail_short_circ_at_HV" 11 "Fail_open_circ_at_LV" 12 "Fail_open_circ_at_HV" 13 "Fail_init_failure" 14 "Fail_wake_up_issue" 15 "Fail_internal_hardware" 16 "Fail_bat_feed_low" 17 "Fail_bat_feed_high" 18 "Fail_Aux_OV" 19 "Fail_Aux_UV" 20 "Fail_HVIL_fault" 21 "Fail_LOC_with_HCP" 22 "Fail_LOC_with_BPCM" 23 "Fail_cont_not_closed" 24 "Fail_SBC_fault" 25 "Memory_Fail" 26 "Implausible_data_from_HCP" 27 "Implausible_data_from_BPCM" 28 "CAN_bus_off" 29 "Fail_temp_diff_is_high" 30 "Fail_high_voltage_diff_is_high" 31 "Fail_for_other_reason" 32 "LOC_ORC" 33 "Implausble_data_ORC" 63 "SNA";
VAL_ 250 APM_EstPwrLoss 255 "SNA";
VAL_ 250 APM_DeratingReason 0 "No_derating" 1 "high_temp_De_rating" 2 "low_temp_De_rating" 3 "OverVolt_HV_De_rating" 4 "lowVolt_HV_De_rating" 5 "highVolt_LV_De_rating" 6 "lowVolt_LV_De_rating" 7 "highCurrent_LV_Current_limit" 8 "internal_HD_fail_De_rating" 9 "high_current_HV_De_rating" 31 "SNA";
VAL_ 250 APM_DeratingModeStatus 0 "No_derating" 1 "Derating_Initialized" 2 "Derating_Initialized_Failure" 3 "Derating_Mode" 7 "SNA";
VAL_ 250 APM_CtrlSts_Fbk 0 "IDLE" 1 "Buck_CV_voltage" 2 "Buck_CC_current_control" 3 "APM_Temporary_Fault" 4 "Buck_Special" 6 "PreCharge" 7 "DisCharge" 8 "OFF" 9 "Derating" 10 "APM_Critical_Fault" 15 "SNA";
VAL_ 2654486679 CBV_bit0_RepeatMessageRequestBit_1E384097 0 "Repeat Message State not requested" 1 "Repeat Message State requested";
VAL_ 2654486679 CBV_bit3_NMCoordinatorBit_1E384097 0 "Start of synchronized shutdown is not requested by main coordinator" 1 "Start of synchronized shutdown is requested by main coordinator";
VAL_ 2654486679 CBV_bit4_ActiveWakeupBit_1E384097 0 "PassiveWakeup" 1 "ActiveWakeup";
VAL_ 2654486679 CBV_bit6_PartialNtwInfBit_1E384097 0 "NM PDU contains no Partial Network request information" 1 "NM PDU contains Partial Network request information";
VAL_ 498 HVCMS_TxMessageStat 0 "NoRequest" 1 "SupportedAppProtocolReq" 2 "SessionSetupReq" 3 "ServiceDiscoveryReq" 4 "ServiceDetailReq" 5 "PaymentServiceSelectionReq" 6 "PaymentDetailsReq" 7 "AuthorizationReq" 8 "ChargeParameterDiscoveryReq" 9 "PowerDeliveryReq" 10 "CertificateUpdateReq" 11 "CertificateInstallationReq" 12 "SessionStopReq" 13 "MeteringReceiptReq" 14 "ChargingStatusReq" 15 "CableCheckReq" 16 "PreChargeReq" 17 "CurrentDemandReq" 18 "WeldingDetectionReq" 19 "Contract_AuthenticationReq" 20 "PowerDeliveryReq_Precharge" 21 "PowerDeliveryReq_EnergyTransfer" 22 "DC_BidirectionalControlReq" 23 "PowerDeliveryReq_Renegotiation" 24 "ChargeParameterDiscovery_Reneg" 31 "SNA";
VAL_ 498 HVCMS_ResponseCode 0 "OK" 1 "OK_CertificateExpiresSoon" 2 "OK_NewSessionEstablished" 3 "OK_OldSessionJoined" 4 "FAILED" 5 "FAILED_SequenceError" 6 "FAILED_SignatureError" 7 "FAILED_UnknownSession" 8 "FAILED_ServiceIDInvalid" 9 "FAILED_PaymentSelectionInvalid" 10 "FAILED_ServiceSelectionInvalid" 11 "FAILED_CertificateExpired" 12 "FAILED_NoCertificateAvailable" 13 "FAILED_CertChainError" 14 "FAILED_ContractCanceled" 15 "FAILED_ChallengeInvalid" 16 "FAILED_WrongEnergyTransferType" 17 "FAILED_WrongChargeParameter" 18 "FAILED_ChargingProfileInvalid" 19 "FAILED_TariffSelectionInvalid" 20 "FAILED_EVSEPresentVoltageToLow" 21 "FAILED_PowerDeliveryNotApplied" 22 "FAILED_MeteringSignatureNotValid" 23 "OK_SuccessfullNegotiation" 24 "OK_SucceedNegotiatnMinorDeviatn" 25 "Failed_NoNegotiation" 31 "SNA";
VAL_ 498 HVCMS_EVSEProcessing 0 "Ongoing" 1 "Finished";
VAL_ 498 EVSE_FreeService 0 "Paid_Service" 1 "Free_Service";
VAL_ 244 ImpactHardwireV 0 "Fail_Not_Present" 1 "Fail_Present";
VAL_ 244 ImpactHardwire 0 "Not_Actuate" 1 "Actuate";
VAL_ 502 HVCMS_ServiceCategory 0 "No_Service" 1 "EV_charging" 2 "Internet" 3 "VAS" 4 "BPT_Service" 5 "WPT_Service" 6 "ACDC_Service" 7 "Contract_Certificate" 8 "EVSEInformation" 15 "SNA";
VAL_ 502 HVCMS_SelectedPaymentOptn 0 "No payment selected" 1 "External Payment" 2 "Contract" 3 "SNA";
VAL_ 502 HVCMS_SelectedEnergyTransferType 0 "No_energy_transfer_type" 1 "AC_single_phase_core" 2 "AC_three_phase_core" 3 "DC_core" 4 "DC_Extended" 5 "DC_combo_core" 6 "DC_unique" 15 "SNA";
VAL_ 502 HVCMS_RemaningTimeToFullSOC 65535 "SNA";
VAL_ 502 HVCMS_RemaningTimeToBulkSOC 65535 "SNA";
VAL_ 502 HVCMS_EVErrorCode 0 "No_error" 1 "FAILED_RESSTTemperatureInhibit" 2 "FAILED_EVShiftPosition" 3 "FAILED_ChargerConnectorLockFault" 4 "FAILED_EVRESSMalfunction" 5 "FAILED_ChargingCurrentDifferential" 6 "FAILED_ChargingcurrentvoltageOutOfRange" 7 "Failed_InletHot" 8 "FAILED_ChargingSystemIncompatibility" 15 "SNA";
VAL_ 498 TxMessageResponse 0 "No_V2G_communication_initialized" 1 "SupportedAppProtocolRes" 2 "SessionSetupRes" 3 "ServiceDiscoveryRes" 4 "ServicePaymentSelectionRes" 5 "Contract_AuthenticationRes" 6 "ChargeParameterDiscoveryRes" 7 "CableCheckRes" 8 "Pre_chargeRes" 9 "PowerDeliveryRes_Precharge" 10 "CurrentDemandRes" 11 "PowerDeliveryRes_EnergyTransfer" 12 "WeldingDetectionRes" 13 "SessionStopRes" 14 "DC_BidirectionalControlRes" 15 "ServiceDetailRes" 16 "PaymentDetailsRes" 17 "AuthorizationRes" 18 "CertificateInstallationRes" 19 "CertificateUpdateRes" 20 "MeteringReceiptRes" 21 "PowerDeliveryReq_Renegotiation" 22 "ChargeParameterDiscovery_Reneg" 31 "SNA";
VAL_ 498 HVCMS_EVSEStatusCode 0 "Charger_standby not ready" 1 "Charger ready charging" 2 "Charger prepaid limits exceeded" 3 "Charger shutdown" 4 "Utility interrupt event" 5 "Isolation monitoring internal" 6 "Isolation monitoring active" 7 "Charger emergency shutdown" 8 "Reserved" 9 "Reserved" 10 "Reserved" 11 "Reserved" 12 "Reserved" 13 "Charging system incompatibility" 14 "Charger malfunction" 15 "No_Data";
VAL_ 498 EVSE_OfferedService 0 "None" 1 "AC_DC_Charging" 2 "Certificate" 3 "InternetAccess" 4 "UseCaseInformation" 5 "Other";
VAL_ 498 EVSE_OfferedPaymentOptn 0 "No payment selected" 1 "External Payment" 2 "Contract" 3 "SNA";
VAL_ 244 BMS_HV_Capacity 2047 "SNA";
VAL_ 250 APM_DeratingPower 63 "SNA";
VAL_ 1852 HVBatCellVoltage_Cell216 8191 "SNA";
VAL_ 1852 HVBatCellVoltage_Cell215 8191 "SNA";
VAL_ 1852 HVBatCellVoltage_Cell214 8191 "SNA";
VAL_ 1852 HVBatCellVoltage_Cell213 8191 "SNA";
VAL_ 1852 HVBatCellVoltage_Cell212 8191 "SNA";
VAL_ 1852 HVBatCellVoltage_Cell211 8191 "SNA";
VAL_ 1852 HVBatCellVoltage_Cell210 8191 "SNA";
VAL_ 1852 HVBatCellVoltage_Cell209 8191 "SNA";
VAL_ 1852 HVBatCellVoltage_Cell208 8191 "SNA";
VAL_ 1852 HVBatCellVoltage_Cell207 8191 "SNA";
VAL_ 1852 HVBatCellVoltage_Cell206 8191 "SNA";
VAL_ 1852 HVBatCellVoltage_Cell205 8191 "SNA";
VAL_ 1852 HVBatCellVoltage_Cell204 8191 "SNA";
VAL_ 1852 HVBatCellVoltage_Cell203 8191 "SNA";
VAL_ 1852 HVBatCellVoltage_Cell202 8191 "SNA";
VAL_ 1852 HVBatCellVoltage_Cell201 8191 "SNA";
VAL_ 1852 HVBatCellVoltage_Cell200 8191 "SNA";
VAL_ 1852 HVBatCellVoltage_Cell198 8191 "SNA";
VAL_ 1852 HVBatCellVoltage_Cell197 8191 "SNA";
VAL_ 1852 HVBatCellVoltage_Cell196 8191 "SNA";
VAL_ 1852 HVBatCellVoltage_Cell195 8191 "SNA";
VAL_ 1852 HVBatCellVoltage_Cell194 8191 "SNA";
VAL_ 1852 HVBatCellVoltage_Cell193 8191 "SNA";
VAL_ 498 V2H_HVCMS_EVSEPresentCurrent 1023 "SNA";
VAL_ 498 EVSE_Supported_ISO1 0 "FALSE" 1 "TRUE";
VAL_ 498 EVSE_Supported_DIN 0 "FALSE" 1 "TRUE";
VAL_ 498 EVSE_Supported_SAE 0 "FALSE" 1 "TRUE";
VAL_ 498 EVSE_Service2_Certificate 0 "Not_Available" 1 "Available";
VAL_ 498 EVSE_OfferedPaymentEIM 0 "FALSE" 1 "TRUE";
VAL_ 498 EVSE_OfferedPaymentContract 0 "FALSE" 1 "TRUE";
VAL_ 498 EVSE_Notification 0 "None" 1 "StopCharging" 2 "ReNegotiation";
VAL_ 498 OBCM_ThermalRunaway 0 "Intial_status_before_check" 1 "No_thermal_Runaway" 2 "Thermal_Runaway_detected" 3 "SNA";
VAL_ 250 APM_ThermalRunaway 0 "Intial_status_before_check" 1 "No_thermal_Runaway" 2 "Thermal_Runaway_detected" 3 "SNA";
VAL_ 498 ReceiptRequired 0 "FALSE" 1 "TRUE";
VAL_ 502 V2X_HVCMS_SlctdEnergyTransfType 0 "No_Service" 1 "Other_Custom";
VAL_ 498 V2X_EVSE_Service_6_V2G 0 "Not_available" 1 "Available";
VAL_ 498 V2X_EVSE_Service_5_V2H 0 "Not_available" 1 "Available";
SIG_GROUP_ 498 OBCM_VDCM_Pkt 1 : HVCMS_EVSEPresentVoltage HVCMS_EVSEPeakCurrentRipple HVCMS_EVSEMinCurrentLimit HVCMS_EVSEMaxPowerLimit HVCMS_EVSEMaxCurrentLimit HVCMS_EVSECurrRegulationTol HVCMS_EnergyToBeDelivered EVSE_IsolationSts EVSE_Accepted_Protocol DC_TimeOut DC_Isolation_Disable_Cmd OBCM_PLCTypeSts HVCMS_TxMessageStat HVCMS_ResponseCode HVCMS_EVSEVoltageLimitAchieved HVCMS_EVSEProcessing HVCMS_EVSEPresentCurrent HVCMS_EVSEPowerLimitAchieved HVCMS_EVSEMinimumVoltageLimit HVCMS_EVSEMaximumVoltageLimit HVCMS_EVSECurrentLimitAchieved EVSE_OfferedEnergyTransferType EVSE_FreeService EVSE_OfferedPaymentOptn EVSE_OfferedService EVSE_ServiceId HVCMS_EVSEStatusCode TxMessageResponse V2H_HVCMS_EVSEPresentCurrent MC_OBCM_VDCM EVSE_Supported_SAE EVSE_Supported_ISO1 EVSE_Supported_DIN EVSE_Service2_Certificate EVSE_OfferedPaymentEIM EVSE_OfferedPaymentContract EVSE_Notification CRC_OBCM_VDCM OBCM_ThermalRunaway V2X_EVSE_Service_6_V2G V2X_EVSE_Service_5_V2H ReceiptRequired;
SIG_GROUP_ 250 APM_VDCM_Pkt 1 : APM_Water_Temp APM_RecoveryAction APM_PSFB_Temp2 APM_PSFB_Temp1 APM_LV_V_Fbk APM_LV_I_Fbk APM_HV_V_Fbk APM_HV_I_Fbk APM_Buck_Temp APM_UtilPctOfDCDC APM_TempColdPlate APM_PowerLimitMode APM_OutputPower APM_InputPower APM_IdcHvSetPFdbk APM_HvVsetPFdbk APM_HvOverVStatus APM_FailureType APM_FailureReason APM_EstPwrLoss APM_DeratingReason APM_DeratingModeStatus APM_CurrentLimitMode APM_CtrlSts_Fbk MessageCounter_APM_VDCM CRC_APM_VDCM APM_DeratingPower APM_ThermalRunaway;
